BU_:  Airbag BAP_Tester ICAS1_Gateway ICAS1_KommunikationsServer LE1 LE2 Motor_BEV Schaltbetaetigung

BU_:  Airbag BAP_Tester ICAS1_Gateway ICAS1_KommunikationsServer LE1 LE2 Motor_BEV Schaltbetaetigung

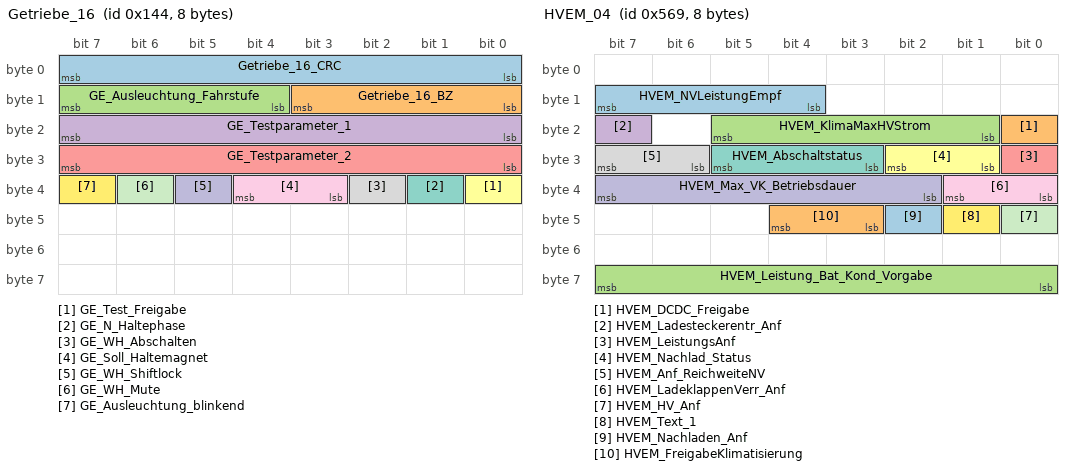
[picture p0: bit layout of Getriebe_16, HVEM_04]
BO_ 324 Getriebe_16: 8 Motor_BEV
 SG_ Getriebe_16_CRC  : 0|8@1+ (1.000000,0.000000) [0.000000|255.000000] "" ICAS1_Gateway Schaltbetaetigung
 SG_ Getriebe_16_BZ  : 8|4@1+ (1.000000,0.000000) [0.000000|15.000000] "" ICAS1_Gateway Schaltbetaetigung
 SG_ GE_Ausleuchtung_Fahrstufe  : 12|4@1+ (1.000000,0.000000) [0.000000|15.000000] "" ICAS1_Gateway Schaltbetaetigung
 SG_ GE_Testparameter_1  : 16|8@1+ (1.000000,0.000000) [0.000000|255.000000] "" ICAS1_Gateway Schaltbetaetigung
 SG_ GE_Testparameter_2  : 24|8@1+ (1.000000,0.000000) [0.000000|255.000000] "" ICAS1_Gateway Schaltbetaetigung
 SG_ GE_Test_Freigabe  : 32|1@1+ (1.000000,0.000000) [0.000000|1.000000] "" ICAS1_Gateway Schaltbetaetigung
 SG_ GE_N_Haltephase  : 33|1@1+ (1.000000,0.000000) [0.000000|1.000000] "" ICAS1_Gateway Schaltbetaetigung
 SG_ GE_WH_Abschalten  : 34|1@1+ (1.000000,0.000000) [0.000000|1.000000] "" ICAS1_Gateway Schaltbetaetigung
 SG_ GE_Soll_Haltemagnet  : 35|2@1+ (1.000000,0.000000) [0.000000|3.000000] "" ICAS1_Gateway Schaltbetaetigung
 SG_ GE_WH_Shiftlock  : 37|1@1+ (1.000000,0.000000) [0.000000|1.000000] "" ICAS1_Gateway Schaltbetaetigung
 SG_ GE_WH_Mute  : 38|1@1+ (1.000000,0.000000) [0.000000|1.000000] "" ICAS1_Gateway Schaltbetaetigung
 SG_ GE_Ausleuchtung_blinkend  : 39|1@1+ (1.000000,0.000000) [0.000000|1.000000] "" ICAS1_Gateway Schaltbetaetigung

BO_ 299 GRA_ACC_01: 8 ICAS1_Gateway
 SG_ GRA_ACC_01_CRC  : 0|8@1+ (1.000000,0.000000) [0.000000|255.000000] "" Motor_BEV
 SG_ GRA_ACC_01_BZ  : 8|4@1+ (1.000000,0.000000) [0.000000|15.000000] "" Motor_BEV
 SG_ GRA_Hauptschalter  : 12|1@1+ (1.000000,0.000000) [0.000000|1.000000] "" Motor_BEV
 SG_ GRA_Abbrechen  : 13|1@1+ (1.000000,0.000000) [0.000000|1.000000] "" Motor_BEV
 SG_ GRA_Typ_Hauptschalter  : 14|1@1+ (1.000000,0.000000) [0.000000|1.000000] "" Motor_BEV
 SG_ GRA_Limiter  : 15|1@1+ (1.000000,0.000000) [0.000000|1.000000] "" Motor_BEV
 SG_ GRA_Tip_Setzen  : 16|1@1+ (1.000000,0.000000) [0.000000|1.000000] "" Motor_BEV
 SG_ GRA_Tip_Hoch  : 17|1@1+ (1.000000,0.000000) [0.000000|1.000000] "" Motor_BEV
 SG_ GRA_Tip_Runter  : 18|1@1+ (1.000000,0.000000) [0.000000|1.000000] "" Motor_BEV
 SG_ GRA_Tip_Wiederaufnahme  : 19|1@1+ (1.000000,0.000000) [0.000000|1.000000] "" Motor_BEV
 SG_ GRA_Verstellung_Zeitluecke  : 20|2@1+ (1.000000,0.000000) [0.000000|3.000000] "" Vector__XXX
 SG_ GRA_Codierung  : 22|2@1+ (1.000000,0.000000) [0.000000|3.000000] "" Motor_BEV
 SG_ GRA_Fehler  : 24|1@1+ (1.000000,0.000000) [0.000000|1.000000] "" Motor_BEV
 SG_ GRA_LIM_Taste_verfuegbar  : 25|1@1+ (1.000000,0.000000) [0.000000|1.000000] "" Motor_BEV
 SG_ GRA_Tip_Stufe_2  : 26|1@1+ (1.000000,0.000000) [0.000000|1.000000] "" Motor_BEV
 SG_ GRA_Typ_Bedienteil  : 27|3@1+ (1.000000,0.000000) [0.000000|7.000000] "" Motor_BEV
 SG_ GRA_TravelAssist  : 30|1@1+ (1.000000,0.000000) [0.000000|1.000000] "" Vector__XXX
 SG_ GRA_reserveByte4  : 31|1@1+ (1.000000,0.000000) [0.000000|1.000000] "" Vector__XXX
 SG_ GRA_reserveByte5  : 32|8@1+ (1.000000,0.000000) [0.000000|255.000000] "" Vector__XXX
 SG_ GRA_reserveByte6  : 40|8@1+ (1.000000,0.000000) [0.000000|255.000000] "" Vector__XXX
 SG_ GRA_reserveByte7  : 48|8@1+ (1.000000,0.000000) [0.000000|255.000000] "" Vector__XXX
 SG_ GRA_reserveByte8  : 56|8@1+ (1.000000,0.000000) [0.000000|255.000000] "" Vector__XXX

BO_ 1452 HVEM_02: 8 ICAS1_Gateway
 SG_ HVEM_IstStrom_HVVerbraucher  : 0|12@1+ (0.100000,-204.700000) [-204.700000|204.600000] "Unit_Amper" Vector__XXX
 SG_ HVEM_Energie_Klima_Vorgabe_HighR  : 12|3@1+ (10.000000,0.000000) [0.000000|50.000000] "Unit_WattHour" Vector__XXX
 SG_ HVEM_IstLeistungNA  : 15|9@1+ (50.000000,0.000000) [0.000000|25450.000000] "Unit_Watt" Motor_BEV
 SG_ HVEM_Leistung_Klima_Vorgabe  : 24|8@1+ (50.000000,0.000000) [0.000000|12650.000000] "Unit_Watt" Vector__XXX
 SG_ HVEM_Nutzbare_Energie  : 32|11@1+ (50.000000,0.000000) [0.000000|102200.000000] "Unit_WattHour" Vector__XXX
 SG_ HVEM_Energie_Klima_Vorgabe  : 43|8@1+ (50.000000,0.000000) [0.000000|12650.000000] "Unit_WattHour" Vector__XXX
 SG_ HVEM_HVK_Aktivitaet  : 51|2@1+ (1.000000,0.000000) [0.000000|3.000000] "" Motor_BEV
 SG_ HVEM_Pruefpuls_Anf  : 53|2@1+ (1.000000,0.000000) [0.000000|3.000000] "" Motor_BEV
 SG_ HVEM_HV_Anf  : 62|1@1+ (1.000000,0.000000) [0.000000|1.000000] "" Motor_BEV
 SG_ HVEM_MO_MaxLeistungIgnoriert  : 63|1@1+ (1.000000,0.000000) [0.000000|1.000000] "" Vector__XXX

BO_ 1385 HVEM_04: 8 ICAS1_Gateway
 SG_ HVEM_NVLeistungEmpf  : 12|4@1+ (100.000000,0.000000) [0.000000|1500.000000] "Unit_Watt" Vector__XXX
 SG_ HVEM_DCDC_Freigabe  : 16|1@1+ (1.000000,0.000000) [0.000000|1.000000] "" Motor_BEV
 SG_ HVEM_KlimaMaxHVStrom  : 17|5@1+ (1.000000,0.000000) [0.000000|31.000000] "Unit_Amper" Vector__XXX
 SG_ HVEM_Ladesteckerentr_Anf  : 23|1@1+ (1.000000,0.000000) [0.000000|1.000000] "" Vector__XXX
 SG_ HVEM_LeistungsAnf  : 24|1@1+ (1.000000,0.000000) [0.000000|1.000000] "" Vector__XXX
 SG_ HVEM_Nachlad_Status  : 25|2@1+ (1.000000,0.000000) [0.000000|3.000000] "" Vector__XXX
 SG_ HVEM_Abschaltstatus  : 27|3@1+ (1.000000,0.000000) [0.000000|7.000000] "" Vector__XXX
 SG_ HVEM_Anf_ReichweiteNV  : 30|2@1+ (1.000000,0.000000) [0.000000|3.000000] "" Vector__XXX
 SG_ HVEM_LadeklappenVerr_Anf  : 32|2@1+ (1.000000,0.000000) [0.000000|3.000000] "" Vector__XXX
 SG_ HVEM_Max_VK_Betriebsdauer  : 34|6@1+ (1.000000,0.000000) [0.000000|60.000000] "Unit_Minut" Vector__XXX
 SG_ HVEM_HV_Anf  : 40|1@1+ (1.000000,0.000000) [0.000000|1.000000] "" Vector__XXX
 SG_ HVEM_Text_1  : 41|1@1+ (1.000000,0.000000) [0.000000|1.000000] "" Vector__XXX
 SG_ HVEM_Nachladen_Anf  : 42|1@1+ (1.000000,0.000000) [0.000000|1.000000] "" Vector__XXX
 SG_ HVEM_FreigabeKlimatisierung  : 43|2@1+ (1.000000,0.000000) [0.000000|3.000000] "" Vector__XXX
 SG_ HVEM_Leistung_Bat_Kond_Vorgabe  : 56|8@1+ (50.000000,0.000000) [0.000000|12650.000000] "Unit_Watt" Vector__XXX

BO_ 1283 HVK_01: 8 Motor_BEV
 SG_ HVK_01_CRC  : 0|8@1+ (1.000000,0.000000) [0.000000|255.000000] "" ICAS1_Gateway LE1 LE2
 SG_ HVK_01_BZ  : 8|4@1+ (1.000000,0.000000) [0.000000|15.000000] "" ICAS1_Gateway LE1 LE2
 SG_ HVK_Istmodus_Anf  : 12|1@1+ (1.000000,0.000000) [0.000000|1.000000] "" ICAS1_Gateway
 SG_ HVK_TN1_Sollmodus  : 13|2@1+ (1.000000,0.000000) [0.000000|3.000000] "" ICAS1_Gateway
 SG_ HVK_Vorladung_aktiv  : 15|1@1+ (1.000000,0.000000) [0.000000|1.000000] "" ICAS1_Gateway
 SG_ HVK_BMS_Sollmodus  : 24|3@1+ (1.000000,0.000000) [0.000000|7.000000] "" ICAS1_Gateway
 SG_ HVK_DCDC_Sollmodus  : 27|3@1+ (1.000000,0.000000) [0.000000|7.000000] "" ICAS1_Gateway
 SG_ HVK_EKK_Sollmodus  : 30|3@1+ (1.000000,0.000000) [0.000000|7.000000] "" ICAS1_Gateway
 SG_ HVK_HVPTC_Sollmodus  : 33|3@1+ (1.000000,0.000000) [0.000000|7.000000] "" ICAS1_Gateway
 SG_ HVK_HVLM_Sollmodus  : 36|3@1+ (1.000000,0.000000) [0.000000|7.000000] "" ICAS1_Gateway
 SG_ HVK_HV_Netz_Warnungen  : 39|2@1+ (1.000000,0.000000) [0.000000|3.000000] "" ICAS1_Gateway ICAS1_KommunikationsServer
 SG_ HV_Bordnetz_aktiv  : 41|1@1+ (1.000000,0.000000) [0.000000|1.000000] "" ICAS1_Gateway LE1 LE2
 SG_ HV_Bordnetz_Fehler  : 42|1@1+ (1.000000,0.000000) [0.000000|1.000000] "" ICAS1_Gateway
 SG_ HVK_Gesamtst_Spgfreiheit  : 43|2@1+ (1.000000,0.000000) [0.000000|3.000000] "" ICAS1_Gateway ICAS1_KommunikationsServer
 SG_ HVK_AktiveEntladung_Anf  : 45|1@1+ (1.000000,0.000000) [0.000000|1.000000] "" ICAS1_Gateway LE1 LE2
 SG_ HVK_HVEM_Freigabe  : 46|2@1+ (1.000000,0.000000) [0.000000|3.000000] "" ICAS1_Gateway
 SG_ HVK_Notentladung_Anf  : 48|2@1+ (1.000000,0.000000) [0.000000|3.000000] "" ICAS1_Gateway LE1 LE2
 SG_ HVK_Iso_Messung_Start  : 50|3@1+ (1.000000,0.000000) [0.000000|7.000000] "" ICAS1_Gateway
 SG_ HVK_Ladebereit  : 53|3@1+ (1.000000,0.000000) [0.000000|7.000000] "" ICAS1_Gateway
 SG_ HVK_PPulsFreigabe  : 56|2@1+ (1.000000,0.000000) [0.000000|3.000000] "" ICAS1_Gateway

BO_ 2463978813 HVL_01: 8 ICAS1_Gateway
 SG_ HVL_01_CRC  : 0|8@1+ (1.000000,0.000000) [0.000000|255.000000] "" Motor_BEV
 SG_ HVL_01_BZ  : 8|4@1+ (1.000000,0.000000) [0.000000|15.000000] "" Motor_BEV
 SG_ HVL_Steckerstatus  : 12|2@1+ (1.000000,0.000000) [0.000000|3.000000] "" Motor_BEV
 SG_ HVL_LadeAnforderung  : 24|3@1+ (1.000000,0.000000) [0.000000|7.000000] "" Motor_BEV

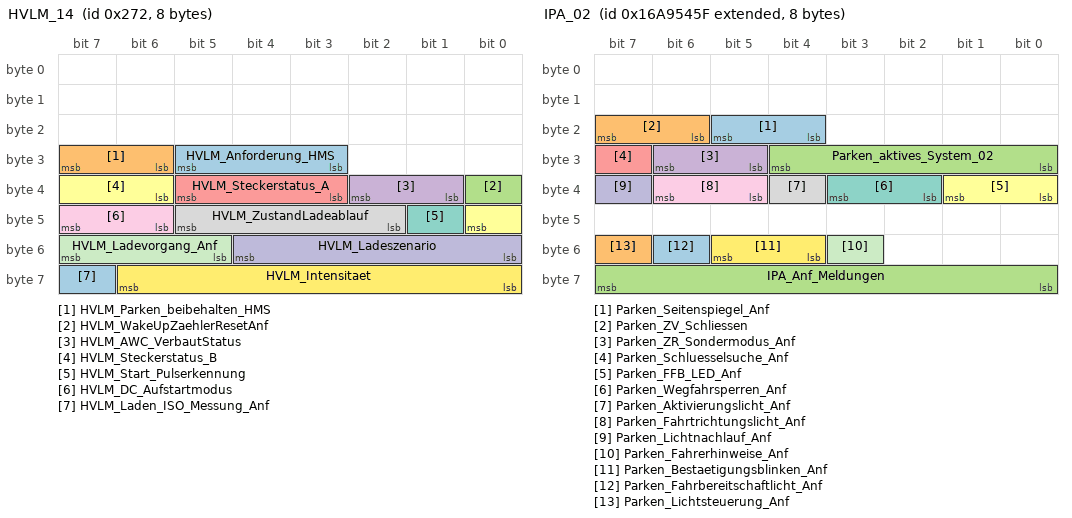
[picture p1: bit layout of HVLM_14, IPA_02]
BO_ 626 HVLM_14: 8 ICAS1_Gateway
 SG_ HVLM_Anforderung_HMS  : 27|3@1+ (1.000000,0.000000) [0.000000|7.000000] "" Vector__XXX
 SG_ HVLM_Parken_beibehalten_HMS  : 30|2@1+ (1.000000,0.000000) [0.000000|3.000000] "" Vector__XXX
 SG_ HVLM_WakeUpZaehlerResetAnf  : 32|1@1+ (1.000000,0.000000) [0.000000|1.000000] "" Vector__XXX
 SG_ HVLM_AWC_VerbautStatus  : 33|2@1+ (1.000000,0.000000) [0.000000|3.000000] "" Motor_BEV
 SG_ HVLM_Steckerstatus_A  : 35|3@1+ (1.000000,0.000000) [0.000000|7.000000] "" Motor_BEV
 SG_ HVLM_Steckerstatus_B  : 38|3@1+ (1.000000,0.000000) [0.000000|7.000000] "" Vector__XXX
 SG_ HVLM_Start_Pulserkennung  : 41|1@1+ (1.000000,0.000000) [0.000000|1.000000] "" Vector__XXX
 SG_ HVLM_ZustandLadeablauf  : 42|4@1+ (1.000000,0.000000) [0.000000|15.000000] "" Motor_BEV
 SG_ HVLM_DC_Aufstartmodus  : 46|2@1+ (1.000000,0.000000) [0.000000|3.000000] "" Motor_BEV
 SG_ HVLM_Ladeszenario  : 48|5@1+ (1.000000,0.000000) [0.000000|31.000000] "" Vector__XXX
 SG_ HVLM_Ladevorgang_Anf  : 53|3@1+ (1.000000,0.000000) [0.000000|7.000000] "" Motor_BEV
 SG_ HVLM_Intensitaet  : 56|7@1+ (1.000000,0.000000) [0.000000|100.000000] "Unit_PerCent" Vector__XXX
 SG_ HVLM_Laden_ISO_Messung_Anf  : 63|1@1+ (1.000000,0.000000) [0.000000|1.000000] "" Motor_BEV

BO_ 268 IMMO_CORD_01: 8 Motor_BEV
 SG_ ImoCord_Auth_Aufforderung_WFS  : 63|1@1+ (1.000000,0.000000) [0.000000|1.000000] "" LE1 LE2

BO_ 23 IMMO_MSG3_Antwort: 8 ICAS1_Gateway
 SG_ WFS_IMMO_MSG3_CRC  : 0|32@1+ (1.000000,0.000000) [0.000000|4294967295.000000] "" LE2
 SG_ WFS_IMMO_MSG3_Status  : 56|8@1+ (1.000000,0.000000) [0.000000|255.000000] "" LE2

BO_ 25 IMMO_MSG4_Antwort: 8 ICAS1_Gateway
 SG_ WFS_IMMO_MSG4_CRC  : 0|32@1+ (1.000000,0.000000) [0.000000|4294967295.000000] "" LE1
 SG_ WFS_IMMO_MSG4_Status  : 56|8@1+ (1.000000,0.000000) [0.000000|255.000000] "" LE1

BO_ 2527679583 IPA_02: 8 ICAS1_Gateway
 SG_ Parken_Seitenspiegel_Anf  : 20|2@1+ (1.000000,0.000000) [0.000000|3.000000] "" Vector__XXX
 SG_ Parken_ZV_Schliessen  : 22|2@1+ (1.000000,0.000000) [0.000000|3.000000] "" Vector__XXX
 SG_ Parken_aktives_System_02  : 24|5@1+ (1.000000,0.000000) [0.000000|31.000000] "" Vector__XXX
 SG_ Parken_ZR_Sondermodus_Anf  : 29|2@1+ (1.000000,0.000000) [0.000000|3.000000] "" Vector__XXX
 SG_ Parken_Schluesselsuche_Anf  : 31|1@1+ (1.000000,0.000000) [0.000000|1.000000] "" Vector__XXX
 SG_ Parken_FFB_LED_Anf  : 32|2@1+ (1.000000,0.000000) [0.000000|3.000000] "" Vector__XXX
 SG_ Parken_Wegfahrsperren_Anf  : 34|2@1+ (1.000000,0.000000) [0.000000|3.000000] "" LE1 LE2
 SG_ Parken_Aktivierungslicht_Anf  : 36|1@1+ (1.000000,0.000000) [0.000000|1.000000] "" Vector__XXX
 SG_ Parken_Fahrtrichtungslicht_Anf  : 37|2@1+ (1.000000,0.000000) [0.000000|3.000000] "" Vector__XXX
 SG_ Parken_Lichtnachlauf_Anf  : 39|1@1+ (1.000000,0.000000) [0.000000|1.000000] "" Vector__XXX
 SG_ Parken_Fahrerhinweise_Anf  : 51|1@1+ (1.000000,0.000000) [0.000000|1.000000] "" Vector__XXX
 SG_ Parken_Bestaetigungsblinken_Anf  : 52|2@1+ (1.000000,0.000000) [0.000000|3.000000] "" Vector__XXX
 SG_ Parken_Fahrbereitschaftlicht_Anf  : 54|1@1+ (1.000000,0.000000) [0.000000|1.000000] "" Vector__XXX
 SG_ Parken_Lichtsteuerung_Anf  : 55|1@1+ (1.000000,0.000000) [0.000000|1.000000] "" Vector__XXX
 SG_ IPA_Anf_Meldungen  : 56|8@1+ (1.000000,0.000000) [0.000000|255.000000] "" Vector__XXX

BO_ 1813 ISO_Airbag_01_Req: 8 ICAS1_Gateway
 SG_ ISO_Airbag_01_Req_Data  : 0|64@1+ (1.000000,0.000000) [0.000000|18446744073709551616.000000] "" Airbag

BO_ 1919 ISO_Airbag_01_Resp: 8 Airbag
 SG_ ISO_Airbag_01_Resp_Data  : 0|64@1+ (1.000000,0.000000) [0.000000|18446744073709551616.000000] "" ICAS1_Gateway

BO_ 1792 ISO_Funktionaler_Req_All: 8 ICAS1_Gateway
 SG_ ISO_ALL_01_Req_Data  : 0|64@1+ (1.000000,0.000000) [0.000000|18446744073709551616.000000] "" Airbag LE1 LE2 Motor_BEV

BO_ 2621440021 ISOx_Airbag_01_Req_FD: 64 ICAS1_Gateway
 SG_ ISOx_Airbag_01_Req_FD_Data  : 0|512@1+ (1.000000,0.000000) [0.000000|13407807929942597099574024998205846127479365820592393377723561443721764030073546976801874298166903427690031858186486050853753882811946569946433649006084096.000000] "" Airbag

BO_ 2621571093 ISOx_Airbag_01_Resp_FD: 64 Airbag
 SG_ ISOx_Airbag_01_Resp_FD_Data  : 0|512@1+ (1.000000,0.000000) [0.000000|13407807929942597099574024998205846127479365820592393377723561443721764030073546976801874298166903427690031858186486050853753882811946569946433649006084096.000000] "" ICAS1_Gateway

BO_ 2549874812 ISOx_EMotor_01_Req: 8 ICAS1_Gateway
 SG_ ISO_EMotor_01_Req_Data  : 0|64@1+ (1.000000,0.000000) [0.000000|18446744073709551616.000000] "" LE1

BO_ 2621440124 ISOx_EMotor_01_Req_FD: 64 ICAS1_Gateway
 SG_ ISOx_EMotor_01_Req_FD_Data  : 0|512@1+ (1.000000,0.000000) [0.000000|13407807929942597099574024998205846127479365820592393377723561443721764030073546976801874298166903427690031858186486050853753882811946569946433649006084096.000000] "" LE1

BO_ 2550005884 ISOx_EMotor_01_Resp: 8 LE1
 SG_ ISO_EMotor_01_Resp_Data  : 0|64@1+ (1.000000,0.000000) [0.000000|18446744073709551616.000000] "" ICAS1_Gateway

BO_ 2621571196 ISOx_EMotor_01_Resp_FD: 64 LE1
 SG_ ISOx_EMotor_01_Resp_FD_Data  : 0|512@1+ (1.000000,0.000000) [0.000000|13407807929942597099574024998205846127479365820592393377723561443721764030073546976801874298166903427690031858186486050853753882811946569946433649006084096.000000] "" ICAS1_Gateway

BO_ 2549874872 ISOx_EMotor_02_Req: 8 ICAS1_Gateway
 SG_ ISO_EMotor_02_Req_Data  : 0|64@1+ (1.000000,0.000000) [0.000000|18446744073709551616.000000] "" LE2

BO_ 2621440184 ISOx_EMotor_02_Req_FD: 64 ICAS1_Gateway
 SG_ ISOx_EMotor_02_Req_FD_Data  : 0|512@1+ (1.000000,0.000000) [0.000000|13407807929942597099574024998205846127479365820592393377723561443721764030073546976801874298166903427690031858186486050853753882811946569946433649006084096.000000] "" LE2

BO_ 2550005944 ISOx_EMotor_02_Resp: 8 LE2
 SG_ ISO_EMotor_02_Resp_Data  : 0|64@1+ (1.000000,0.000000) [0.000000|18446744073709551616.000000] "" ICAS1_Gateway

BO_ 2621571256 ISOx_EMotor_02_Resp_FD: 64 LE2
 SG_ ISOx_EMotor_02_Resp_FD_Data  : 0|512@1+ (1.000000,0.000000) [0.000000|13407807929942597099574024998205846127479365820592393377723561443721764030073546976801874298166903427690031858186486050853753882811946569946433649006084096.000000] "" ICAS1_Gateway

BO_ 2621505536 ISOx_Funkt_Req_All_FD: 64 ICAS1_Gateway
 SG_ ISOx_Funkt_Req_All_FD_Data  : 0|512@1+ (1.000000,0.000000) [0.000000|13407807929942597099574024998205846127479365820592393377723561443721764030073546976801874298166903427690031858186486050853753882811946569946433649006084096.000000] "" Airbag LE1 LE2 Motor_BEV

BO_ 2549874806 ISOx_MO_01_Req: 8 ICAS1_Gateway
 SG_ ISOx_MO_01_Req_Data  : 0|64@1+ (1.000000,0.000000) [0.000000|18446744073709551616.000000] "" Motor_BEV

BO_ 2621440118 ISOx_MO_01_Req_FD: 64 ICAS1_Gateway
 SG_ ISOx_MO_01_Req_FD_Data  : 0|512@1+ (1.000000,0.000000) [0.000000|13407807929942597099574024998205846127479365820592393377723561443721764030073546976801874298166903427690031858186486050853753882811946569946433649006084096.000000] "" Motor_BEV

BO_ 2550005878 ISOx_MO_01_Resp: 8 Motor_BEV
 SG_ ISOx_MO_01_Resp_Data  : 0|64@1+ (1.000000,0.000000) [0.000000|18446744073709551616.000000] "" ICAS1_Gateway

BO_ 2621571190 ISOx_MO_01_Resp_FD: 64 Motor_BEV
 SG_ ISOx_MO_01_Resp_FD_Data  : 0|512@1+ (1.000000,0.000000) [0.000000|13407807929942597099574024998205846127479365820592393377723561443721764030073546976801874298166903427690031858186486050853753882811946569946433649006084096.000000] "" ICAS1_Gateway

BO_ 2527679684 Kamera_ASM_01: 8 ICAS1_Gateway
 SG_ Kamera_ASM_Ereignis  : 0|8@1+ (1.000000,0.000000) [1.000000|254.000000] "" Airbag
 SG_ Kamera_ASM_Zeitstempel  : 8|8@1+ (0.080000,0.000000) [0.000000|20.320000] "Unit_Secon" Airbag
 SG_ Kamera_ASM_Data_1  : 16|8@1+ (1.000000,0.000000) [0.000000|255.000000] "" Airbag
 SG_ Kamera_ASM_Data_2  : 24|8@1+ (1.000000,0.000000) [0.000000|255.000000] "" Airbag
 SG_ Kamera_ASM_Data_3  : 32|8@1+ (1.000000,0.000000) [0.000000|255.000000] "" Airbag
 SG_ Kamera_ASM_Data_4  : 40|8@1+ (1.000000,0.000000) [0.000000|255.000000] "" Airbag
 SG_ Kamera_ASM_Data_5  : 48|8@1+ (1.000000,0.000000) [0.000000|255.000000] "" Airbag
 SG_ Kamera_ASM_Data_6  : 56|8@1+ (1.000000,0.000000) [0.000000|255.000000] "" Airbag

BO_ 960 Klemmen_Status_01: 4 ICAS1_Gateway
 SG_ Klemmen_Status_01_CRC  : 0|8@1+ (1.000000,0.000000) [0.000000|255.000000] "" Motor_BEV
 SG_ Klemmen_Status_01_BZ  : 8|4@1+ (1.000000,0.000000) [0.000000|15.000000] "" Motor_BEV
 SG_ RSt_Fahrerhinweise  : 12|4@1+ (1.000000,0.000000) [0.000000|15.000000] "" Vector__XXX
 SG_ ZAS_Kl_S  : 16|1@1+ (1.000000,0.000000) [0.000000|1.000000] "" Vector__XXX
 SG_ ZAS_Kl_15  : 17|1@1+ (1.000000,0.000000) [0.000000|1.000000] "" Airbag LE1 LE2 Motor_BEV Schaltbetaetigung
 SG_ ZAS_Kl_X  : 18|1@1+ (1.000000,0.000000) [0.000000|1.000000] "" Vector__XXX
 SG_ ZAS_Kl_50_Startanforderung  : 19|1@1+ (1.000000,0.000000) [0.000000|1.000000] "" Motor_BEV
 SG_ BCM_Remotestart_Betrieb  : 20|1@1+ (1.000000,0.000000) [0.000000|1.000000] "" Vector__XXX
 SG_ ZAS_Kl_Infotainment  : 21|1@1+ (1.000000,0.000000) [0.000000|1.000000] "" Vector__XXX
 SG_ BCM_Remotestart_KL15_Anf  : 22|1@1+ (1.000000,0.000000) [0.000000|1.000000] "" Vector__XXX
 SG_ BCM_Remotestart_MO_Start  : 23|1@1+ (1.000000,0.000000) [0.000000|1.000000] "" Vector__XXX
 SG_ KST_Warn_P1_ZST_def  : 24|1@1+ (1.000000,0.000000) [0.000000|1.000000] "" Vector__XXX
 SG_ KST_Warn_P2_ZST_def  : 25|1@1+ (1.000000,0.000000) [0.000000|1.000000] "" Vector__XXX
 SG_ KST_Fahrerhinweis_1  : 26|1@1+ (1.000000,0.000000) [0.000000|1.000000] "" Vector__XXX
 SG_ KST_Fahrerhinweis_2  : 27|1@1+ (1.000000,0.000000) [0.000000|1.000000] "" Vector__XXX
 SG_ BCM_Ausparken_Betrieb  : 28|1@1+ (1.000000,0.000000) [0.000000|1.000000] "" Vector__XXX
 SG_ KST_Fahrerhinweis_4  : 29|1@1+ (1.000000,0.000000) [0.000000|1.000000] "" Vector__XXX
 SG_ KST_Fahrerhinweis_5  : 30|1@1+ (1.000000,0.000000) [0.000000|1.000000] "" Vector__XXX
 SG_ KST_Fahrerhinweis_6  : 31|1@1+ (1.000000,0.000000) [0.000000|1.000000] "" Vector__XXX

BO_ 2463978753 Klemmen_Status_02: 8 ICAS1_Gateway
 SG_ KST_WFS_Fahrfreigabe_Anforderung  : 12|2@1+ (1.000000,0.000000) [0.000000|3.000000] "" LE1 LE2
 SG_ KST_Sonderzustand_Status  : 14|2@1+ (1.000000,0.000000) [0.000000|3.000000] "" LE1 LE2
 SG_ KST_Sonderzustand_Anforderung  : 16|5@1+ (1.000000,0.000000) [0.000000|31.000000] "" LE1 LE2

BO_ 1420 Klemmen_Steuerung_01: 8 ICAS1_Gateway
 SG_ Klemmen_Steuerung_01_CRC  : 0|8@1+ (1.000000,0.000000) [0.000000|255.000000] "" Vector__XXX
 SG_ Klemmen_Steuerung_01_BZ  : 8|4@1+ (1.000000,0.000000) [0.000000|15.000000] "" Vector__XXX
 SG_ KST_Anf_Klemme_15  : 12|1@1+ (1.000000,0.000000) [0.000000|1.000000] "" Vector__XXX
 SG_ KST_Anf_Klemme_50  : 13|1@1+ (1.000000,0.000000) [0.000000|1.000000] "" Motor_BEV
 SG_ KST_Anf_Klemme_S  : 14|1@1+ (1.000000,0.000000) [0.000000|1.000000] "" Vector__XXX
 SG_ KST_Txt_Werkstatt  : 15|1@1+ (1.000000,0.000000) [0.000000|1.000000] "" Vector__XXX
 SG_ KST_Txt_P_Gang  : 16|1@1+ (1.000000,0.000000) [0.000000|1.000000] "" Vector__XXX
 SG_ KST_Txt_Panikabschaltung  : 17|1@1+ (1.000000,0.000000) [0.000000|1.000000] "" Vector__XXX
 SG_ KST_Anf_Klemmenfreigabe_ELV  : 18|1@1+ (1.000000,0.000000) [0.000000|1.000000] "" Vector__XXX
 SG_ KST_Txt_Komfortabschaltung  : 19|1@1+ (1.000000,0.000000) [0.000000|1.000000] "" Vector__XXX
 SG_ KST_ZAT_betaetigt  : 20|1@1+ (1.000000,0.000000) [0.000000|1.000000] "" Vector__XXX
 SG_ KST_Unterdr_Zuendungsmeldung  : 21|1@1+ (1.000000,0.000000) [0.000000|1.000000] "" Vector__XXX
 SG_ KST_aut_Abschaltung_Zuendung  : 22|1@1+ (1.000000,0.000000) [0.000000|1.000000] "" Vector__XXX
 SG_ KST_Anf_Klemmenfreigabe_WFS  : 23|1@1+ (1.000000,0.000000) [0.000000|1.000000] "" Vector__XXX
 SG_ KST_Anf_ZV_Verriegelung  : 24|1@1+ (1.000000,0.000000) [0.000000|1.000000] "" Vector__XXX
 SG_ Relais_VoKo_angesteuert  : 25|1@1+ (1.000000,0.000000) [0.000000|1.000000] "" Vector__XXX
 SG_ RSt_Anforderung_HMS  : 26|3@1+ (1.000000,0.000000) [0.000000|7.000000] "" Vector__XXX
 SG_ KST_Zuendungswarnung  : 29|2@1+ (1.000000,0.000000) [0.000000|3.000000] "" Vector__XXX
 SG_ KST_Fahrer_Info_Text  : 31|3@1+ (1.000000,0.000000) [0.000000|7.000000] "" Vector__XXX

BO_ 949 Klima_11: 8 ICAS1_Gateway
 SG_ KL_Drehz_Anh  : 0|1@1+ (1.000000,0.000000) [0.000000|1.000000] "" Vector__XXX
 SG_ KL_Vorwarn_Komp_ein  : 1|1@1+ (1.000000,0.000000) [0.000000|1.000000] "" Vector__XXX
 SG_ KL_AC_Schalter  : 2|1@1+ (1.000000,0.000000) [0.000000|1.000000] "" Vector__XXX
 SG_ KL_Komp_Moment_alt  : 3|1@1+ (1.000000,0.000000) [0.000000|1.000000] "" Vector__XXX
 SG_ KL_Vorwarn_Zuheizer_ein  : 6|1@1+ (1.000000,0.000000) [0.000000|1.000000] "" Vector__XXX
 SG_ KL_Zustand  : 7|1@1+ (1.000000,0.000000) [0.000000|1.000000] "" Vector__XXX
 SG_ KL_Kompressorkupplung_linear  : 8|8@1+ (20.000000,0.000000) [0.000000|4000.000000] "Unit_MilliAmper" Vector__XXX
 SG_ KL_Charisma_FahrPr  : 16|4@1+ (1.000000,0.000000) [0.000000|15.000000] "" Vector__XXX
 SG_ KL_Charisma_Status  : 20|2@1+ (1.000000,0.000000) [0.000000|3.000000] "" Vector__XXX
 SG_ KL_nachtr_Stopp_Anf  : 22|1@1+ (1.000000,0.000000) [0.000000|1.000000] "" Vector__XXX
 SG_ KL_T_Charge  : 23|1@1+ (1.000000,0.000000) [0.000000|1.000000] "" Vector__XXX
 SG_ KL_Last_Kompr  : 24|8@1+ (0.250000,0.000000) [0.000000|63.500000] "Unit_NewtoMeter" Vector__XXX
 SG_ KL_Spannungs_Anf  : 32|2@1+ (1.000000,0.000000) [0.000000|3.000000] "" Vector__XXX
 SG_ KL_Thermomanagement  : 34|2@1+ (1.000000,0.000000) [0.000000|3.000000] "" Motor_BEV
 SG_ KL_StartStopp_Info  : 36|2@1+ (1.000000,0.000000) [0.000000|3.000000] "" Vector__XXX
 SG_ KL_Freilauf_Info  : 38|2@1+ (1.000000,0.000000) [0.000000|3.000000] "" Vector__XXX
 SG_ KL_Anf_KL  : 40|8@1+ (0.400000,0.000000) [0.000000|101.600000] "Unit_PerCent" Motor_BEV
 SG_ KL_el_Zuheizer_Stufe  : 48|3@1+ (1.000000,0.000000) [0.000000|7.000000] "" Vector__XXX
 SG_ KL_Ausstattung_Klima  : 51|3@1+ (1.000000,0.000000) [0.000000|7.000000] "" Vector__XXX
 SG_ KL_Variante_Standheizung  : 54|2@1+ (1.000000,0.000000) [0.000000|3.000000] "" Vector__XXX
 SG_ KL_Anf_KV  : 57|7@1+ (1.000000,0.000000) [0.000000|100.000000] "Unit_PerCent" Motor_BEV

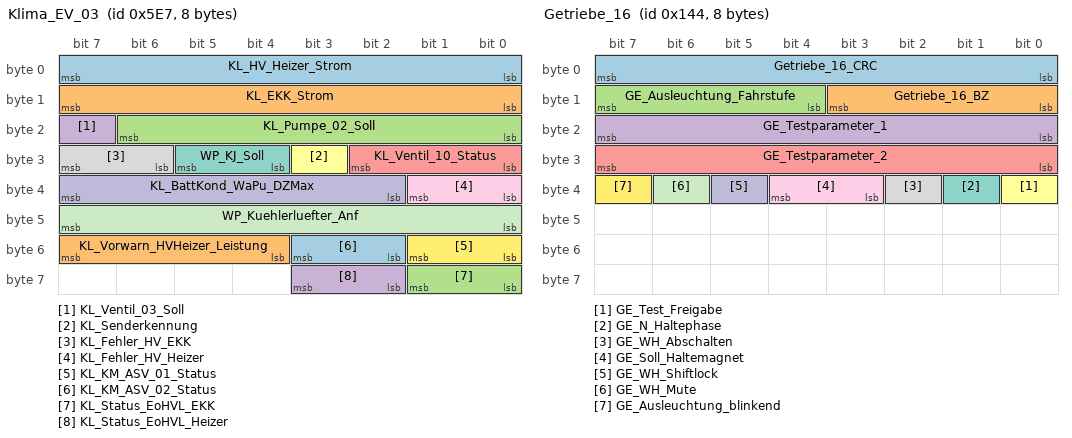
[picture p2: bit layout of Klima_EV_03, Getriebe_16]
BO_ 1511 Klima_EV_03: 8 ICAS1_Gateway
 SG_ KL_HV_Heizer_Strom  : 0|8@1+ (0.250000,0.000000) [0.000000|63.500000] "Unit_Amper" Motor_BEV
 SG_ KL_EKK_Strom  : 8|8@1+ (0.250000,0.000000) [0.000000|63.500000] "Unit_Amper" Motor_BEV
 SG_ KL_Pumpe_02_Soll  : 16|7@1+ (1.000000,0.000000) [0.000000|100.000000] "Unit_PerCent" Motor_BEV
 SG_ KL_Ventil_03_Soll  : 23|1@1+ (1.000000,0.000000) [0.000000|1.000000] "" Vector__XXX
 SG_ KL_Ventil_10_Status  : 24|3@1+ (1.000000,0.000000) [0.000000|7.000000] "" Vector__XXX
 SG_ KL_Senderkennung  : 27|1@1+ (1.000000,0.000000) [0.000000|1.000000] "" Vector__XXX
 SG_ WP_KJ_Soll  : 28|2@1+ (1.000000,0.000000) [0.000000|3.000000] "" Vector__XXX
 SG_ KL_Fehler_HV_EKK  : 30|2@1+ (1.000000,0.000000) [0.000000|3.000000] "" Vector__XXX
 SG_ KL_Fehler_HV_Heizer  : 32|2@1+ (1.000000,0.000000) [0.000000|3.000000] "" Vector__XXX
 SG_ KL_BattKond_WaPu_DZMax  : 34|6@1+ (2.000000,0.000000) [0.000000|100.000000] "Unit_PerCent" Vector__XXX
 SG_ WP_Kuehlerluefter_Anf  : 40|8@1+ (0.400000,0.000000) [0.000000|101.600000] "Unit_PerCent" Vector__XXX
 SG_ KL_KM_ASV_01_Status  : 48|2@1+ (1.000000,0.000000) [0.000000|3.000000] "" Vector__XXX
 SG_ KL_KM_ASV_02_Status  : 50|2@1+ (1.000000,0.000000) [0.000000|3.000000] "" Vector__XXX
 SG_ KL_Vorwarn_HVHeizer_Leistung  : 52|4@1+ (1.000000,0.000000) [0.000000|15.000000] "" Vector__XXX
 SG_ KL_Status_EoHVL_EKK  : 56|2@1+ (1.000000,0.000000) [0.000000|3.000000] "" Motor_BEV
 SG_ KL_Status_EoHVL_Heizer  : 58|2@1+ (1.000000,0.000000) [0.000000|3.000000] "" Motor_BEV

BU_:  Airbag BAP_Tester ICAS1_Gateway ICAS1_KommunikationsServer LE1 LE2 Motor_BEV Schaltbetaetigung

BO_ 324 Getriebe_16: 8 Motor_BEV
 SG_ Getriebe_16_CRC  : 0|8@1+ (1.000000,0.000000) [0.000000|255.000000] "" ICAS1_Gateway Schaltbetaetigung
 SG_ Getriebe_16_BZ  : 8|4@1+ (1.000000,0.000000) [0.000000|15.000000] "" ICAS1_Gateway Schaltbetaetigung
 SG_ GE_Ausleuchtung_Fahrstufe  : 12|4@1+ (1.000000,0.000000) [0.000000|15.000000] "" ICAS1_Gateway Schaltbetaetigung
 SG_ GE_Testparameter_1  : 16|8@1+ (1.000000,0.000000) [0.000000|255.000000] "" ICAS1_Gateway Schaltbetaetigung
 SG_ GE_Testparameter_2  : 24|8@1+ (1.000000,0.000000) [0.000000|255.000000] "" ICAS1_Gateway Schaltbetaetigung
 SG_ GE_Test_Freigabe  : 32|1@1+ (1.000000,0.000000) [0.000000|1.000000] "" ICAS1_Gateway Schaltbetaetigung
 SG_ GE_N_Haltephase  : 33|1@1+ (1.000000,0.000000) [0.000000|1.000000] "" ICAS1_Gateway Schaltbetaetigung
 SG_ GE_WH_Abschalten  : 34|1@1+ (1.000000,0.000000) [0.000000|1.000000] "" ICAS1_Gateway Schaltbetaetigung
 SG_ GE_Soll_Haltemagnet  : 35|2@1+ (1.000000,0.000000) [0.000000|3.000000] "" ICAS1_Gateway Schaltbetaetigung
 SG_ GE_WH_Shiftlock  : 37|1@1+ (1.000000,0.000000) [0.000000|1.000000] "" ICAS1_Gateway Schaltbetaetigung
 SG_ GE_WH_Mute  : 38|1@1+ (1.000000,0.000000) [0.000000|1.000000] "" ICAS1_Gateway Schaltbetaetigung
 SG_ GE_Ausleuchtung_blinkend  : 39|1@1+ (1.000000,0.000000) [0.000000|1.000000] "" ICAS1_Gateway Schaltbetaetigung

BO_ 299 GRA_ACC_01: 8 ICAS1_Gateway
 SG_ GRA_ACC_01_CRC  : 0|8@1+ (1.000000,0.000000) [0.000000|255.000000] "" Motor_BEV
 SG_ GRA_ACC_01_BZ  : 8|4@1+ (1.000000,0.000000) [0.000000|15.000000] "" Motor_BEV
 SG_ GRA_Hauptschalter  : 12|1@1+ (1.000000,0.000000) [0.000000|1.000000] "" Motor_BEV
 SG_ GRA_Abbrechen  : 13|1@1+ (1.000000,0.000000) [0.000000|1.000000] "" Motor_BEV
 SG_ GRA_Typ_Hauptschalter  : 14|1@1+ (1.000000,0.000000) [0.000000|1.000000] "" Motor_BEV
 SG_ GRA_Limiter  : 15|1@1+ (1.000000,0.000000) [0.000000|1.000000] "" Motor_BEV
 SG_ GRA_Tip_Setzen  : 16|1@1+ (1.000000,0.000000) [0.000000|1.000000] "" Motor_BEV
 SG_ GRA_Tip_Hoch  : 17|1@1+ (1.000000,0.000000) [0.000000|1.000000] "" Motor_BEV
 SG_ GRA_Tip_Runter  : 18|1@1+ (1.000000,0.000000) [0.000000|1.000000] "" Motor_BEV
 SG_ GRA_Tip_Wiederaufnahme  : 19|1@1+ (1.000000,0.000000) [0.000000|1.000000] "" Motor_BEV
 SG_ GRA_Verstellung_Zeitluecke  : 20|2@1+ (1.000000,0.000000) [0.000000|3.000000] "" Vector__XXX
 SG_ GRA_Codierung  : 22|2@1+ (1.000000,0.000000) [0.000000|3.000000] "" Motor_BEV
 SG_ GRA_Fehler  : 24|1@1+ (1.000000,0.000000) [0.000000|1.000000] "" Motor_BEV
 SG_ GRA_LIM_Taste_verfuegbar  : 25|1@1+ (1.000000,0.000000) [0.000000|1.000000] "" Motor_BEV
 SG_ GRA_Tip_Stufe_2  : 26|1@1+ (1.000000,0.000000) [0.000000|1.000000] "" Motor_BEV
 SG_ GRA_Typ_Bedienteil  : 27|3@1+ (1.000000,0.000000) [0.000000|7.000000] "" Motor_BEV
 SG_ GRA_TravelAssist  : 30|1@1+ (1.000000,0.000000) [0.000000|1.000000] "" Vector__XXX
 SG_ GRA_reserveByte4  : 31|1@1+ (1.000000,0.000000) [0.000000|1.000000] "" Vector__XXX
 SG_ GRA_reserveByte5  : 32|8@1+ (1.000000,0.000000) [0.000000|255.000000] "" Vector__XXX
 SG_ GRA_reserveByte6  : 40|8@1+ (1.000000,0.000000) [0.000000|255.000000] "" Vector__XXX
 SG_ GRA_reserveByte7  : 48|8@1+ (1.000000,0.000000) [0.000000|255.000000] "" Vector__XXX
 SG_ GRA_reserveByte8  : 56|8@1+ (1.000000,0.000000) [0.000000|255.000000] "" Vector__XXX

BO_ 1452 HVEM_02: 8 ICAS1_Gateway
 SG_ HVEM_IstStrom_HVVerbraucher  : 0|12@1+ (0.100000,-204.700000) [-204.700000|204.600000] "Unit_Amper" Vector__XXX
 SG_ HVEM_Energie_Klima_Vorgabe_HighR  : 12|3@1+ (10.000000,0.000000) [0.000000|50.000000] "Unit_WattHour" Vector__XXX
 SG_ HVEM_IstLeistungNA  : 15|9@1+ (50.000000,0.000000) [0.000000|25450.000000] "Unit_Watt" Motor_BEV
 SG_ HVEM_Leistung_Klima_Vorgabe  : 24|8@1+ (50.000000,0.000000) [0.000000|12650.000000] "Unit_Watt" Vector__XXX
 SG_ HVEM_Nutzbare_Energie  : 32|11@1+ (50.000000,0.000000) [0.000000|102200.000000] "Unit_WattHour" Vector__XXX
 SG_ HVEM_Energie_Klima_Vorgabe  : 43|8@1+ (50.000000,0.000000) [0.000000|12650.000000] "Unit_WattHour" Vector__XXX
 SG_ HVEM_HVK_Aktivitaet  : 51|2@1+ (1.000000,0.000000) [0.000000|3.000000] "" Motor_BEV
 SG_ HVEM_Pruefpuls_Anf  : 53|2@1+ (1.000000,0.000000) [0.000000|3.000000] "" Motor_BEV
 SG_ HVEM_HV_Anf  : 62|1@1+ (1.000000,0.000000) [0.000000|1.000000] "" Motor_BEV
 SG_ HVEM_MO_MaxLeistungIgnoriert  : 63|1@1+ (1.000000,0.000000) [0.000000|1.000000] "" Vector__XXX

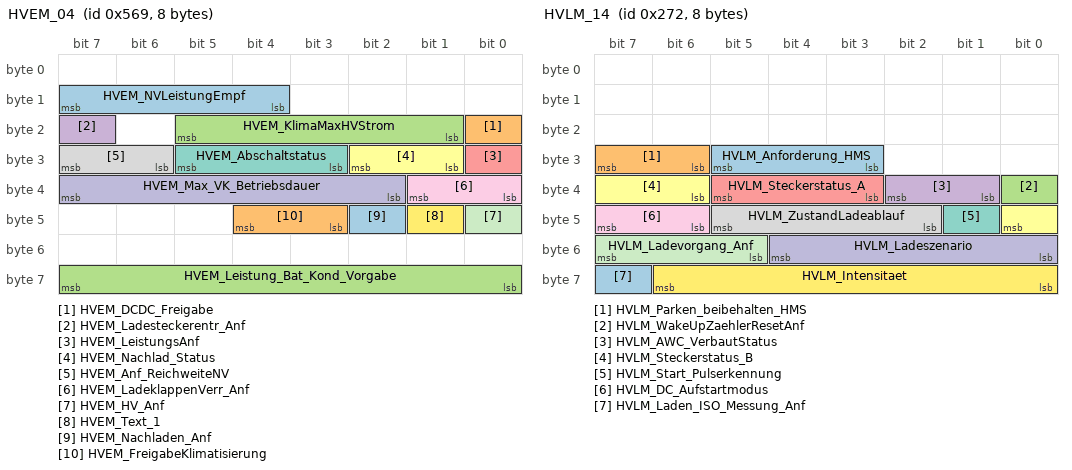
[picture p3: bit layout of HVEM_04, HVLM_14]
BO_ 1385 HVEM_04: 8 ICAS1_Gateway
 SG_ HVEM_NVLeistungEmpf  : 12|4@1+ (100.000000,0.000000) [0.000000|1500.000000] "Unit_Watt" Vector__XXX
 SG_ HVEM_DCDC_Freigabe  : 16|1@1+ (1.000000,0.000000) [0.000000|1.000000] "" Motor_BEV
 SG_ HVEM_KlimaMaxHVStrom  : 17|5@1+ (1.000000,0.000000) [0.000000|31.000000] "Unit_Amper" Vector__XXX
 SG_ HVEM_Ladesteckerentr_Anf  : 23|1@1+ (1.000000,0.000000) [0.000000|1.000000] "" Vector__XXX
 SG_ HVEM_LeistungsAnf  : 24|1@1+ (1.000000,0.000000) [0.000000|1.000000] "" Vector__XXX
 SG_ HVEM_Nachlad_Status  : 25|2@1+ (1.000000,0.000000) [0.000000|3.000000] "" Vector__XXX
 SG_ HVEM_Abschaltstatus  : 27|3@1+ (1.000000,0.000000) [0.000000|7.000000] "" Vector__XXX
 SG_ HVEM_Anf_ReichweiteNV  : 30|2@1+ (1.000000,0.000000) [0.000000|3.000000] "" Vector__XXX
 SG_ HVEM_LadeklappenVerr_Anf  : 32|2@1+ (1.000000,0.000000) [0.000000|3.000000] "" Vector__XXX
 SG_ HVEM_Max_VK_Betriebsdauer  : 34|6@1+ (1.000000,0.000000) [0.000000|60.000000] "Unit_Minut" Vector__XXX
 SG_ HVEM_HV_Anf  : 40|1@1+ (1.000000,0.000000) [0.000000|1.000000] "" Vector__XXX
 SG_ HVEM_Text_1  : 41|1@1+ (1.000000,0.000000) [0.000000|1.000000] "" Vector__XXX
 SG_ HVEM_Nachladen_Anf  : 42|1@1+ (1.000000,0.000000) [0.000000|1.000000] "" Vector__XXX
 SG_ HVEM_FreigabeKlimatisierung  : 43|2@1+ (1.000000,0.000000) [0.000000|3.000000] "" Vector__XXX
 SG_ HVEM_Leistung_Bat_Kond_Vorgabe  : 56|8@1+ (50.000000,0.000000) [0.000000|12650.000000] "Unit_Watt" Vector__XXX

BO_ 1283 HVK_01: 8 Motor_BEV
 SG_ HVK_01_CRC  : 0|8@1+ (1.000000,0.000000) [0.000000|255.000000] "" ICAS1_Gateway LE1 LE2
 SG_ HVK_01_BZ  : 8|4@1+ (1.000000,0.000000) [0.000000|15.000000] "" ICAS1_Gateway LE1 LE2
 SG_ HVK_Istmodus_Anf  : 12|1@1+ (1.000000,0.000000) [0.000000|1.000000] "" ICAS1_Gateway
 SG_ HVK_TN1_Sollmodus  : 13|2@1+ (1.000000,0.000000) [0.000000|3.000000] "" ICAS1_Gateway
 SG_ HVK_Vorladung_aktiv  : 15|1@1+ (1.000000,0.000000) [0.000000|1.000000] "" ICAS1_Gateway
 SG_ HVK_BMS_Sollmodus  : 24|3@1+ (1.000000,0.000000) [0.000000|7.000000] "" ICAS1_Gateway
 SG_ HVK_DCDC_Sollmodus  : 27|3@1+ (1.000000,0.000000) [0.000000|7.000000] "" ICAS1_Gateway
 SG_ HVK_EKK_Sollmodus  : 30|3@1+ (1.000000,0.000000) [0.000000|7.000000] "" ICAS1_Gateway
 SG_ HVK_HVPTC_Sollmodus  : 33|3@1+ (1.000000,0.000000) [0.000000|7.000000] "" ICAS1_Gateway
 SG_ HVK_HVLM_Sollmodus  : 36|3@1+ (1.000000,0.000000) [0.000000|7.000000] "" ICAS1_Gateway
 SG_ HVK_HV_Netz_Warnungen  : 39|2@1+ (1.000000,0.000000) [0.000000|3.000000] "" ICAS1_Gateway ICAS1_KommunikationsServer
 SG_ HV_Bordnetz_aktiv  : 41|1@1+ (1.000000,0.000000) [0.000000|1.000000] "" ICAS1_Gateway LE1 LE2
 SG_ HV_Bordnetz_Fehler  : 42|1@1+ (1.000000,0.000000) [0.000000|1.000000] "" ICAS1_Gateway
 SG_ HVK_Gesamtst_Spgfreiheit  : 43|2@1+ (1.000000,0.000000) [0.000000|3.000000] "" ICAS1_Gateway ICAS1_KommunikationsServer
 SG_ HVK_AktiveEntladung_Anf  : 45|1@1+ (1.000000,0.000000) [0.000000|1.000000] "" ICAS1_Gateway LE1 LE2
 SG_ HVK_HVEM_Freigabe  : 46|2@1+ (1.000000,0.000000) [0.000000|3.000000] "" ICAS1_Gateway
 SG_ HVK_Notentladung_Anf  : 48|2@1+ (1.000000,0.000000) [0.000000|3.000000] "" ICAS1_Gateway LE1 LE2
 SG_ HVK_Iso_Messung_Start  : 50|3@1+ (1.000000,0.000000) [0.000000|7.000000] "" ICAS1_Gateway
 SG_ HVK_Ladebereit  : 53|3@1+ (1.000000,0.000000) [0.000000|7.000000] "" ICAS1_Gateway
 SG_ HVK_PPulsFreigabe  : 56|2@1+ (1.000000,0.000000) [0.000000|3.000000] "" ICAS1_Gateway

BO_ 2463978813 HVL_01: 8 ICAS1_Gateway
 SG_ HVL_01_CRC  : 0|8@1+ (1.000000,0.000000) [0.000000|255.000000] "" Motor_BEV
 SG_ HVL_01_BZ  : 8|4@1+ (1.000000,0.000000) [0.000000|15.000000] "" Motor_BEV
 SG_ HVL_Steckerstatus  : 12|2@1+ (1.000000,0.000000) [0.000000|3.000000] "" Motor_BEV
 SG_ HVL_LadeAnforderung  : 24|3@1+ (1.000000,0.000000) [0.000000|7.000000] "" Motor_BEV

BO_ 626 HVLM_14: 8 ICAS1_Gateway
 SG_ HVLM_Anforderung_HMS  : 27|3@1+ (1.000000,0.000000) [0.000000|7.000000] "" Vector__XXX
 SG_ HVLM_Parken_beibehalten_HMS  : 30|2@1+ (1.000000,0.000000) [0.000000|3.000000] "" Vector__XXX
 SG_ HVLM_WakeUpZaehlerResetAnf  : 32|1@1+ (1.000000,0.000000) [0.000000|1.000000] "" Vector__XXX
 SG_ HVLM_AWC_VerbautStatus  : 33|2@1+ (1.000000,0.000000) [0.000000|3.000000] "" Motor_BEV
 SG_ HVLM_Steckerstatus_A  : 35|3@1+ (1.000000,0.000000) [0.000000|7.000000] "" Motor_BEV
 SG_ HVLM_Steckerstatus_B  : 38|3@1+ (1.000000,0.000000) [0.000000|7.000000] "" Vector__XXX
 SG_ HVLM_Start_Pulserkennung  : 41|1@1+ (1.000000,0.000000) [0.000000|1.000000] "" Vector__XXX
 SG_ HVLM_ZustandLadeablauf  : 42|4@1+ (1.000000,0.000000) [0.000000|15.000000] "" Motor_BEV
 SG_ HVLM_DC_Aufstartmodus  : 46|2@1+ (1.000000,0.000000) [0.000000|3.000000] "" Motor_BEV
 SG_ HVLM_Ladeszenario  : 48|5@1+ (1.000000,0.000000) [0.000000|31.000000] "" Vector__XXX
 SG_ HVLM_Ladevorgang_Anf  : 53|3@1+ (1.000000,0.000000) [0.000000|7.000000] "" Motor_BEV
 SG_ HVLM_Intensitaet  : 56|7@1+ (1.000000,0.000000) [0.000000|100.000000] "Unit_PerCent" Vector__XXX
 SG_ HVLM_Laden_ISO_Messung_Anf  : 63|1@1+ (1.000000,0.000000) [0.000000|1.000000] "" Motor_BEV

BO_ 268 IMMO_CORD_01: 8 Motor_BEV
 SG_ ImoCord_Auth_Aufforderung_WFS  : 63|1@1+ (1.000000,0.000000) [0.000000|1.000000] "" LE1 LE2

BO_ 23 IMMO_MSG3_Antwort: 8 ICAS1_Gateway
 SG_ WFS_IMMO_MSG3_CRC  : 0|32@1+ (1.000000,0.000000) [0.000000|4294967295.000000] "" LE2
 SG_ WFS_IMMO_MSG3_Status  : 56|8@1+ (1.000000,0.000000) [0.000000|255.000000] "" LE2

BO_ 25 IMMO_MSG4_Antwort: 8 ICAS1_Gateway
 SG_ WFS_IMMO_MSG4_CRC  : 0|32@1+ (1.000000,0.000000) [0.000000|4294967295.000000] "" LE1
 SG_ WFS_IMMO_MSG4_Status  : 56|8@1+ (1.000000,0.000000) [0.000000|255.000000] "" LE1

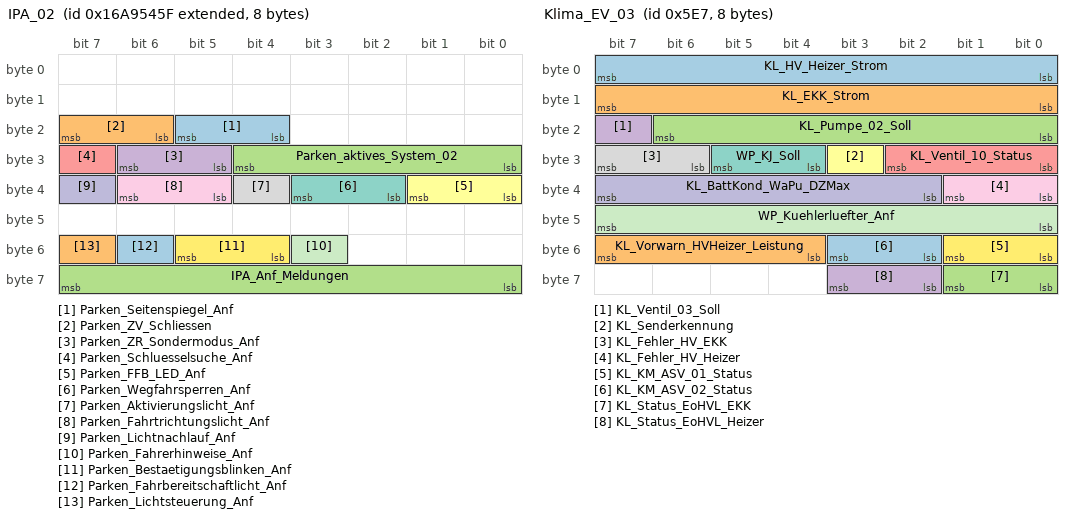
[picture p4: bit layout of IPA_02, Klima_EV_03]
BO_ 2527679583 IPA_02: 8 ICAS1_Gateway
 SG_ Parken_Seitenspiegel_Anf  : 20|2@1+ (1.000000,0.000000) [0.000000|3.000000] "" Vector__XXX
 SG_ Parken_ZV_Schliessen  : 22|2@1+ (1.000000,0.000000) [0.000000|3.000000] "" Vector__XXX
 SG_ Parken_aktives_System_02  : 24|5@1+ (1.000000,0.000000) [0.000000|31.000000] "" Vector__XXX
 SG_ Parken_ZR_Sondermodus_Anf  : 29|2@1+ (1.000000,0.000000) [0.000000|3.000000] "" Vector__XXX
 SG_ Parken_Schluesselsuche_Anf  : 31|1@1+ (1.000000,0.000000) [0.000000|1.000000] "" Vector__XXX
 SG_ Parken_FFB_LED_Anf  : 32|2@1+ (1.000000,0.000000) [0.000000|3.000000] "" Vector__XXX
 SG_ Parken_Wegfahrsperren_Anf  : 34|2@1+ (1.000000,0.000000) [0.000000|3.000000] "" LE1 LE2
 SG_ Parken_Aktivierungslicht_Anf  : 36|1@1+ (1.000000,0.000000) [0.000000|1.000000] "" Vector__XXX
 SG_ Parken_Fahrtrichtungslicht_Anf  : 37|2@1+ (1.000000,0.000000) [0.000000|3.000000] "" Vector__XXX
 SG_ Parken_Lichtnachlauf_Anf  : 39|1@1+ (1.000000,0.000000) [0.000000|1.000000] "" Vector__XXX
 SG_ Parken_Fahrerhinweise_Anf  : 51|1@1+ (1.000000,0.000000) [0.000000|1.000000] "" Vector__XXX
 SG_ Parken_Bestaetigungsblinken_Anf  : 52|2@1+ (1.000000,0.000000) [0.000000|3.000000] "" Vector__XXX
 SG_ Parken_Fahrbereitschaftlicht_Anf  : 54|1@1+ (1.000000,0.000000) [0.000000|1.000000] "" Vector__XXX
 SG_ Parken_Lichtsteuerung_Anf  : 55|1@1+ (1.000000,0.000000) [0.000000|1.000000] "" Vector__XXX
 SG_ IPA_Anf_Meldungen  : 56|8@1+ (1.000000,0.000000) [0.000000|255.000000] "" Vector__XXX

BO_ 1813 ISO_Airbag_01_Req: 8 ICAS1_Gateway
 SG_ ISO_Airbag_01_Req_Data  : 0|64@1+ (1.000000,0.000000) [0.000000|18446744073709551616.000000] "" Airbag

BO_ 1919 ISO_Airbag_01_Resp: 8 Airbag
 SG_ ISO_Airbag_01_Resp_Data  : 0|64@1+ (1.000000,0.000000) [0.000000|18446744073709551616.000000] "" ICAS1_Gateway

BO_ 1792 ISO_Funktionaler_Req_All: 8 ICAS1_Gateway
 SG_ ISO_ALL_01_Req_Data  : 0|64@1+ (1.000000,0.000000) [0.000000|18446744073709551616.000000] "" Airbag LE1 LE2 Motor_BEV

BO_ 2621440021 ISOx_Airbag_01_Req_FD: 64 ICAS1_Gateway
 SG_ ISOx_Airbag_01_Req_FD_Data  : 0|512@1+ (1.000000,0.000000) [0.000000|13407807929942597099574024998205846127479365820592393377723561443721764030073546976801874298166903427690031858186486050853753882811946569946433649006084096.000000] "" Airbag

BO_ 2621571093 ISOx_Airbag_01_Resp_FD: 64 Airbag
 SG_ ISOx_Airbag_01_Resp_FD_Data  : 0|512@1+ (1.000000,0.000000) [0.000000|13407807929942597099574024998205846127479365820592393377723561443721764030073546976801874298166903427690031858186486050853753882811946569946433649006084096.000000] "" ICAS1_Gateway

BO_ 2549874812 ISOx_EMotor_01_Req: 8 ICAS1_Gateway
 SG_ ISO_EMotor_01_Req_Data  : 0|64@1+ (1.000000,0.000000) [0.000000|18446744073709551616.000000] "" LE1

BO_ 2621440124 ISOx_EMotor_01_Req_FD: 64 ICAS1_Gateway
 SG_ ISOx_EMotor_01_Req_FD_Data  : 0|512@1+ (1.000000,0.000000) [0.000000|13407807929942597099574024998205846127479365820592393377723561443721764030073546976801874298166903427690031858186486050853753882811946569946433649006084096.000000] "" LE1

BO_ 2550005884 ISOx_EMotor_01_Resp: 8 LE1
 SG_ ISO_EMotor_01_Resp_Data  : 0|64@1+ (1.000000,0.000000) [0.000000|18446744073709551616.000000] "" ICAS1_Gateway

BO_ 2621571196 ISOx_EMotor_01_Resp_FD: 64 LE1
 SG_ ISOx_EMotor_01_Resp_FD_Data  : 0|512@1+ (1.000000,0.000000) [0.000000|13407807929942597099574024998205846127479365820592393377723561443721764030073546976801874298166903427690031858186486050853753882811946569946433649006084096.000000] "" ICAS1_Gateway

BO_ 2549874872 ISOx_EMotor_02_Req: 8 ICAS1_Gateway
 SG_ ISO_EMotor_02_Req_Data  : 0|64@1+ (1.000000,0.000000) [0.000000|18446744073709551616.000000] "" LE2

BO_ 2621440184 ISOx_EMotor_02_Req_FD: 64 ICAS1_Gateway
 SG_ ISOx_EMotor_02_Req_FD_Data  : 0|512@1+ (1.000000,0.000000) [0.000000|13407807929942597099574024998205846127479365820592393377723561443721764030073546976801874298166903427690031858186486050853753882811946569946433649006084096.000000] "" LE2

BO_ 2550005944 ISOx_EMotor_02_Resp: 8 LE2
 SG_ ISO_EMotor_02_Resp_Data  : 0|64@1+ (1.000000,0.000000) [0.000000|18446744073709551616.000000] "" ICAS1_Gateway

BO_ 2621571256 ISOx_EMotor_02_Resp_FD: 64 LE2
 SG_ ISOx_EMotor_02_Resp_FD_Data  : 0|512@1+ (1.000000,0.000000) [0.000000|13407807929942597099574024998205846127479365820592393377723561443721764030073546976801874298166903427690031858186486050853753882811946569946433649006084096.000000] "" ICAS1_Gateway

BO_ 2621505536 ISOx_Funkt_Req_All_FD: 64 ICAS1_Gateway
 SG_ ISOx_Funkt_Req_All_FD_Data  : 0|512@1+ (1.000000,0.000000) [0.000000|13407807929942597099574024998205846127479365820592393377723561443721764030073546976801874298166903427690031858186486050853753882811946569946433649006084096.000000] "" Airbag LE1 LE2 Motor_BEV

BO_ 2549874806 ISOx_MO_01_Req: 8 ICAS1_Gateway
 SG_ ISOx_MO_01_Req_Data  : 0|64@1+ (1.000000,0.000000) [0.000000|18446744073709551616.000000] "" Motor_BEV

BO_ 2621440118 ISOx_MO_01_Req_FD: 64 ICAS1_Gateway
 SG_ ISOx_MO_01_Req_FD_Data  : 0|512@1+ (1.000000,0.000000) [0.000000|13407807929942597099574024998205846127479365820592393377723561443721764030073546976801874298166903427690031858186486050853753882811946569946433649006084096.000000] "" Motor_BEV

BO_ 2550005878 ISOx_MO_01_Resp: 8 Motor_BEV
 SG_ ISOx_MO_01_Resp_Data  : 0|64@1+ (1.000000,0.000000) [0.000000|18446744073709551616.000000] "" ICAS1_Gateway

BO_ 2621571190 ISOx_MO_01_Resp_FD: 64 Motor_BEV
 SG_ ISOx_MO_01_Resp_FD_Data  : 0|512@1+ (1.000000,0.000000) [0.000000|13407807929942597099574024998205846127479365820592393377723561443721764030073546976801874298166903427690031858186486050853753882811946569946433649006084096.000000] "" ICAS1_Gateway

BO_ 2527679684 Kamera_ASM_01: 8 ICAS1_Gateway
 SG_ Kamera_ASM_Ereignis  : 0|8@1+ (1.000000,0.000000) [1.000000|254.000000] "" Airbag
 SG_ Kamera_ASM_Zeitstempel  : 8|8@1+ (0.080000,0.000000) [0.000000|20.320000] "Unit_Secon" Airbag
 SG_ Kamera_ASM_Data_1  : 16|8@1+ (1.000000,0.000000) [0.000000|255.000000] "" Airbag
 SG_ Kamera_ASM_Data_2  : 24|8@1+ (1.000000,0.000000) [0.000000|255.000000] "" Airbag
 SG_ Kamera_ASM_Data_3  : 32|8@1+ (1.000000,0.000000) [0.000000|255.000000] "" Airbag
 SG_ Kamera_ASM_Data_4  : 40|8@1+ (1.000000,0.000000) [0.000000|255.000000] "" Airbag
 SG_ Kamera_ASM_Data_5  : 48|8@1+ (1.000000,0.000000) [0.000000|255.000000] "" Airbag
 SG_ Kamera_ASM_Data_6  : 56|8@1+ (1.000000,0.000000) [0.000000|255.000000] "" Airbag

BO_ 960 Klemmen_Status_01: 4 ICAS1_Gateway
 SG_ Klemmen_Status_01_CRC  : 0|8@1+ (1.000000,0.000000) [0.000000|255.000000] "" Motor_BEV
 SG_ Klemmen_Status_01_BZ  : 8|4@1+ (1.000000,0.000000) [0.000000|15.000000] "" Motor_BEV
 SG_ RSt_Fahrerhinweise  : 12|4@1+ (1.000000,0.000000) [0.000000|15.000000] "" Vector__XXX
 SG_ ZAS_Kl_S  : 16|1@1+ (1.000000,0.000000) [0.000000|1.000000] "" Vector__XXX
 SG_ ZAS_Kl_15  : 17|1@1+ (1.000000,0.000000) [0.000000|1.000000] "" Airbag LE1 LE2 Motor_BEV Schaltbetaetigung
 SG_ ZAS_Kl_X  : 18|1@1+ (1.000000,0.000000) [0.000000|1.000000] "" Vector__XXX
 SG_ ZAS_Kl_50_Startanforderung  : 19|1@1+ (1.000000,0.000000) [0.000000|1.000000] "" Motor_BEV
 SG_ BCM_Remotestart_Betrieb  : 20|1@1+ (1.000000,0.000000) [0.000000|1.000000] "" Vector__XXX
 SG_ ZAS_Kl_Infotainment  : 21|1@1+ (1.000000,0.000000) [0.000000|1.000000] "" Vector__XXX
 SG_ BCM_Remotestart_KL15_Anf  : 22|1@1+ (1.000000,0.000000) [0.000000|1.000000] "" Vector__XXX
 SG_ BCM_Remotestart_MO_Start  : 23|1@1+ (1.000000,0.000000) [0.000000|1.000000] "" Vector__XXX
 SG_ KST_Warn_P1_ZST_def  : 24|1@1+ (1.000000,0.000000) [0.000000|1.000000] "" Vector__XXX
 SG_ KST_Warn_P2_ZST_def  : 25|1@1+ (1.000000,0.000000) [0.000000|1.000000] "" Vector__XXX
 SG_ KST_Fahrerhinweis_1  : 26|1@1+ (1.000000,0.000000) [0.000000|1.000000] "" Vector__XXX
 SG_ KST_Fahrerhinweis_2  : 27|1@1+ (1.000000,0.000000) [0.000000|1.000000] "" Vector__XXX
 SG_ BCM_Ausparken_Betrieb  : 28|1@1+ (1.000000,0.000000) [0.000000|1.000000] "" Vector__XXX
 SG_ KST_Fahrerhinweis_4  : 29|1@1+ (1.000000,0.000000) [0.000000|1.000000] "" Vector__XXX
 SG_ KST_Fahrerhinweis_5  : 30|1@1+ (1.000000,0.000000) [0.000000|1.000000] "" Vector__XXX
 SG_ KST_Fahrerhinweis_6  : 31|1@1+ (1.000000,0.000000) [0.000000|1.000000] "" Vector__XXX

BO_ 2463978753 Klemmen_Status_02: 8 ICAS1_Gateway
 SG_ KST_WFS_Fahrfreigabe_Anforderung  : 12|2@1+ (1.000000,0.000000) [0.000000|3.000000] "" LE1 LE2
 SG_ KST_Sonderzustand_Status  : 14|2@1+ (1.000000,0.000000) [0.000000|3.000000] "" LE1 LE2
 SG_ KST_Sonderzustand_Anforderung  : 16|5@1+ (1.000000,0.000000) [0.000000|31.000000] "" LE1 LE2

BO_ 1420 Klemmen_Steuerung_01: 8 ICAS1_Gateway
 SG_ Klemmen_Steuerung_01_CRC  : 0|8@1+ (1.000000,0.000000) [0.000000|255.000000] "" Vector__XXX
 SG_ Klemmen_Steuerung_01_BZ  : 8|4@1+ (1.000000,0.000000) [0.000000|15.000000] "" Vector__XXX
 SG_ KST_Anf_Klemme_15  : 12|1@1+ (1.000000,0.000000) [0.000000|1.000000] "" Vector__XXX
 SG_ KST_Anf_Klemme_50  : 13|1@1+ (1.000000,0.000000) [0.000000|1.000000] "" Motor_BEV
 SG_ KST_Anf_Klemme_S  : 14|1@1+ (1.000000,0.000000) [0.000000|1.000000] "" Vector__XXX
 SG_ KST_Txt_Werkstatt  : 15|1@1+ (1.000000,0.000000) [0.000000|1.000000] "" Vector__XXX
 SG_ KST_Txt_P_Gang  : 16|1@1+ (1.000000,0.000000) [0.000000|1.000000] "" Vector__XXX
 SG_ KST_Txt_Panikabschaltung  : 17|1@1+ (1.000000,0.000000) [0.000000|1.000000] "" Vector__XXX
 SG_ KST_Anf_Klemmenfreigabe_ELV  : 18|1@1+ (1.000000,0.000000) [0.000000|1.000000] "" Vector__XXX
 SG_ KST_Txt_Komfortabschaltung  : 19|1@1+ (1.000000,0.000000) [0.000000|1.000000] "" Vector__XXX
 SG_ KST_ZAT_betaetigt  : 20|1@1+ (1.000000,0.000000) [0.000000|1.000000] "" Vector__XXX
 SG_ KST_Unterdr_Zuendungsmeldung  : 21|1@1+ (1.000000,0.000000) [0.000000|1.000000] "" Vector__XXX
 SG_ KST_aut_Abschaltung_Zuendung  : 22|1@1+ (1.000000,0.000000) [0.000000|1.000000] "" Vector__XXX
 SG_ KST_Anf_Klemmenfreigabe_WFS  : 23|1@1+ (1.000000,0.000000) [0.000000|1.000000] "" Vector__XXX
 SG_ KST_Anf_ZV_Verriegelung  : 24|1@1+ (1.000000,0.000000) [0.000000|1.000000] "" Vector__XXX
 SG_ Relais_VoKo_angesteuert  : 25|1@1+ (1.000000,0.000000) [0.000000|1.000000] "" Vector__XXX
 SG_ RSt_Anforderung_HMS  : 26|3@1+ (1.000000,0.000000) [0.000000|7.000000] "" Vector__XXX
 SG_ KST_Zuendungswarnung  : 29|2@1+ (1.000000,0.000000) [0.000000|3.000000] "" Vector__XXX
 SG_ KST_Fahrer_Info_Text  : 31|3@1+ (1.000000,0.000000) [0.000000|7.000000] "" Vector__XXX

BO_ 949 Klima_11: 8 ICAS1_Gateway
 SG_ KL_Drehz_Anh  : 0|1@1+ (1.000000,0.000000) [0.000000|1.000000] "" Vector__XXX
 SG_ KL_Vorwarn_Komp_ein  : 1|1@1+ (1.000000,0.000000) [0.000000|1.000000] "" Vector__XXX
 SG_ KL_AC_Schalter  : 2|1@1+ (1.000000,0.000000) [0.000000|1.000000] "" Vector__XXX
 SG_ KL_Komp_Moment_alt  : 3|1@1+ (1.000000,0.000000) [0.000000|1.000000] "" Vector__XXX
 SG_ KL_Vorwarn_Zuheizer_ein  : 6|1@1+ (1.000000,0.000000) [0.000000|1.000000] "" Vector__XXX
 SG_ KL_Zustand  : 7|1@1+ (1.000000,0.000000) [0.000000|1.000000] "" Vector__XXX
 SG_ KL_Kompressorkupplung_linear  : 8|8@1+ (20.000000,0.000000) [0.000000|4000.000000] "Unit_MilliAmper" Vector__XXX
 SG_ KL_Charisma_FahrPr  : 16|4@1+ (1.000000,0.000000) [0.000000|15.000000] "" Vector__XXX
 SG_ KL_Charisma_Status  : 20|2@1+ (1.000000,0.000000) [0.000000|3.000000] "" Vector__XXX
 SG_ KL_nachtr_Stopp_Anf  : 22|1@1+ (1.000000,0.000000) [0.000000|1.000000] "" Vector__XXX
 SG_ KL_T_Charge  : 23|1@1+ (1.000000,0.000000) [0.000000|1.000000] "" Vector__XXX
 SG_ KL_Last_Kompr  : 24|8@1+ (0.250000,0.000000) [0.000000|63.500000] "Unit_NewtoMeter" Vector__XXX
 SG_ KL_Spannungs_Anf  : 32|2@1+ (1.000000,0.000000) [0.000000|3.000000] "" Vector__XXX
 SG_ KL_Thermomanagement  : 34|2@1+ (1.000000,0.000000) [0.000000|3.000000] "" Motor_BEV
 SG_ KL_StartStopp_Info  : 36|2@1+ (1.000000,0.000000) [0.000000|3.000000] "" Vector__XXX
 SG_ KL_Freilauf_Info  : 38|2@1+ (1.000000,0.000000) [0.000000|3.000000] "" Vector__XXX
 SG_ KL_Anf_KL  : 40|8@1+ (0.400000,0.000000) [0.000000|101.600000] "Unit_PerCent" Motor_BEV
 SG_ KL_el_Zuheizer_Stufe  : 48|3@1+ (1.000000,0.000000) [0.000000|7.000000] "" Vector__XXX
 SG_ KL_Ausstattung_Klima  : 51|3@1+ (1.000000,0.000000) [0.000000|7.000000] "" Vector__XXX
 SG_ KL_Variante_Standheizung  : 54|2@1+ (1.000000,0.000000) [0.000000|3.000000] "" Vector__XXX
 SG_ KL_Anf_KV  : 57|7@1+ (1.000000,0.000000) [0.000000|100.000000] "Unit_PerCent" Motor_BEV

BO_ 1511 Klima_EV_03: 8 ICAS1_Gateway
 SG_ KL_HV_Heizer_Strom  : 0|8@1+ (0.250000,0.000000) [0.000000|63.500000] "Unit_Amper" Motor_BEV
 SG_ KL_EKK_Strom  : 8|8@1+ (0.250000,0.000000) [0.000000|63.500000] "Unit_Amper" Motor_BEV
 SG_ KL_Pumpe_02_Soll  : 16|7@1+ (1.000000,0.000000) [0.000000|100.000000] "Unit_PerCent" Motor_BEV
 SG_ KL_Ventil_03_Soll  : 23|1@1+ (1.000000,0.000000) [0.000000|1.000000] "" Vector__XXX
 SG_ KL_Ventil_10_Status  : 24|3@1+ (1.000000,0.000000) [0.000000|7.000000] "" Vector__XXX
 SG_ KL_Senderkennung  : 27|1@1+ (1.000000,0.000000) [0.000000|1.000000] "" Vector__XXX
 SG_ WP_KJ_Soll  : 28|2@1+ (1.000000,0.000000) [0.000000|3.000000] "" Vector__XXX
 SG_ KL_Fehler_HV_EKK  : 30|2@1+ (1.000000,0.000000) [0.000000|3.000000] "" Vector__XXX
 SG_ KL_Fehler_HV_Heizer  : 32|2@1+ (1.000000,0.000000) [0.000000|3.000000] "" Vector__XXX
 SG_ KL_BattKond_WaPu_DZMax  : 34|6@1+ (2.000000,0.000000) [0.000000|100.000000] "Unit_PerCent" Vector__XXX
 SG_ WP_Kuehlerluefter_Anf  : 40|8@1+ (0.400000,0.000000) [0.000000|101.600000] "Unit_PerCent" Vector__XXX
 SG_ KL_KM_ASV_01_Status  : 48|2@1+ (1.000000,0.000000) [0.000000|3.000000] "" Vector__XXX
 SG_ KL_KM_ASV_02_Status  : 50|2@1+ (1.000000,0.000000) [0.000000|3.000000] "" Vector__XXX
 SG_ KL_Vorwarn_HVHeizer_Leistung  : 52|4@1+ (1.000000,0.000000) [0.000000|15.000000] "" Vector__XXX
 SG_ KL_Status_EoHVL_EKK  : 56|2@1+ (1.000000,0.000000) [0.000000|3.000000] "" Motor_BEV
 SG_ KL_Status_EoHVL_Heizer  : 58|2@1+ (1.000000,0.000000) [0.000000|3.000000] "" Motor_BEV

BU_:  Airbag BAP_Tester ICAS1_Gateway ICAS1_KommunikationsServer LE1 LE2 Motor_BEV Schaltbetaetigung

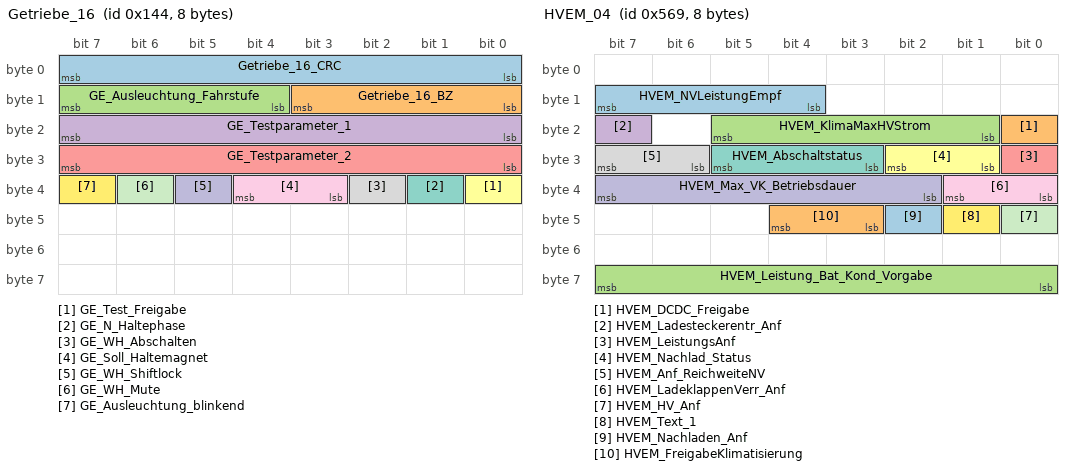
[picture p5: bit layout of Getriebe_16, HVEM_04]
BO_ 324 Getriebe_16: 8 Motor_BEV
 SG_ Getriebe_16_CRC  : 0|8@1+ (1.000000,0.000000) [0.000000|255.000000] "" ICAS1_Gateway Schaltbetaetigung
 SG_ Getriebe_16_BZ  : 8|4@1+ (1.000000,0.000000) [0.000000|15.000000] "" ICAS1_Gateway Schaltbetaetigung
 SG_ GE_Ausleuchtung_Fahrstufe  : 12|4@1+ (1.000000,0.000000) [0.000000|15.000000] "" ICAS1_Gateway Schaltbetaetigung
 SG_ GE_Testparameter_1  : 16|8@1+ (1.000000,0.000000) [0.000000|255.000000] "" ICAS1_Gateway Schaltbetaetigung
 SG_ GE_Testparameter_2  : 24|8@1+ (1.000000,0.000000) [0.000000|255.000000] "" ICAS1_Gateway Schaltbetaetigung
 SG_ GE_Test_Freigabe  : 32|1@1+ (1.000000,0.000000) [0.000000|1.000000] "" ICAS1_Gateway Schaltbetaetigung
 SG_ GE_N_Haltephase  : 33|1@1+ (1.000000,0.000000) [0.000000|1.000000] "" ICAS1_Gateway Schaltbetaetigung
 SG_ GE_WH_Abschalten  : 34|1@1+ (1.000000,0.000000) [0.000000|1.000000] "" ICAS1_Gateway Schaltbetaetigung
 SG_ GE_Soll_Haltemagnet  : 35|2@1+ (1.000000,0.000000) [0.000000|3.000000] "" ICAS1_Gateway Schaltbetaetigung
 SG_ GE_WH_Shiftlock  : 37|1@1+ (1.000000,0.000000) [0.000000|1.000000] "" ICAS1_Gateway Schaltbetaetigung
 SG_ GE_WH_Mute  : 38|1@1+ (1.000000,0.000000) [0.000000|1.000000] "" ICAS1_Gateway Schaltbetaetigung
 SG_ GE_Ausleuchtung_blinkend  : 39|1@1+ (1.000000,0.000000) [0.000000|1.000000] "" ICAS1_Gateway Schaltbetaetigung

BO_ 299 GRA_ACC_01: 8 ICAS1_Gateway
 SG_ GRA_ACC_01_CRC  : 0|8@1+ (1.000000,0.000000) [0.000000|255.000000] "" Motor_BEV
 SG_ GRA_ACC_01_BZ  : 8|4@1+ (1.000000,0.000000) [0.000000|15.000000] "" Motor_BEV
 SG_ GRA_Hauptschalter  : 12|1@1+ (1.000000,0.000000) [0.000000|1.000000] "" Motor_BEV
 SG_ GRA_Abbrechen  : 13|1@1+ (1.000000,0.000000) [0.000000|1.000000] "" Motor_BEV
 SG_ GRA_Typ_Hauptschalter  : 14|1@1+ (1.000000,0.000000) [0.000000|1.000000] "" Motor_BEV
 SG_ GRA_Limiter  : 15|1@1+ (1.000000,0.000000) [0.000000|1.000000] "" Motor_BEV
 SG_ GRA_Tip_Setzen  : 16|1@1+ (1.000000,0.000000) [0.000000|1.000000] "" Motor_BEV
 SG_ GRA_Tip_Hoch  : 17|1@1+ (1.000000,0.000000) [0.000000|1.000000] "" Motor_BEV
 SG_ GRA_Tip_Runter  : 18|1@1+ (1.000000,0.000000) [0.000000|1.000000] "" Motor_BEV
 SG_ GRA_Tip_Wiederaufnahme  : 19|1@1+ (1.000000,0.000000) [0.000000|1.000000] "" Motor_BEV
 SG_ GRA_Verstellung_Zeitluecke  : 20|2@1+ (1.000000,0.000000) [0.000000|3.000000] "" Vector__XXX
 SG_ GRA_Codierung  : 22|2@1+ (1.000000,0.000000) [0.000000|3.000000] "" Motor_BEV
 SG_ GRA_Fehler  : 24|1@1+ (1.000000,0.000000) [0.000000|1.000000] "" Motor_BEV
 SG_ GRA_LIM_Taste_verfuegbar  : 25|1@1+ (1.000000,0.000000) [0.000000|1.000000] "" Motor_BEV
 SG_ GRA_Tip_Stufe_2  : 26|1@1+ (1.000000,0.000000) [0.000000|1.000000] "" Motor_BEV
 SG_ GRA_Typ_Bedienteil  : 27|3@1+ (1.000000,0.000000) [0.000000|7.000000] "" Motor_BEV
 SG_ GRA_TravelAssist  : 30|1@1+ (1.000000,0.000000) [0.000000|1.000000] "" Vector__XXX
 SG_ GRA_reserveByte4  : 31|1@1+ (1.000000,0.000000) [0.000000|1.000000] "" Vector__XXX
 SG_ GRA_reserveByte5  : 32|8@1+ (1.000000,0.000000) [0.000000|255.000000] "" Vector__XXX
 SG_ GRA_reserveByte6  : 40|8@1+ (1.000000,0.000000) [0.000000|255.000000] "" Vector__XXX
 SG_ GRA_reserveByte7  : 48|8@1+ (1.000000,0.000000) [0.000000|255.000000] "" Vector__XXX
 SG_ GRA_reserveByte8  : 56|8@1+ (1.000000,0.000000) [0.000000|255.000000] "" Vector__XXX

BO_ 1452 HVEM_02: 8 ICAS1_Gateway
 SG_ HVEM_IstStrom_HVVerbraucher  : 0|12@1+ (0.100000,-204.700000) [-204.700000|204.600000] "Unit_Amper" Vector__XXX
 SG_ HVEM_Energie_Klima_Vorgabe_HighR  : 12|3@1+ (10.000000,0.000000) [0.000000|50.000000] "Unit_WattHour" Vector__XXX
 SG_ HVEM_IstLeistungNA  : 15|9@1+ (50.000000,0.000000) [0.000000|25450.000000] "Unit_Watt" Motor_BEV
 SG_ HVEM_Leistung_Klima_Vorgabe  : 24|8@1+ (50.000000,0.000000) [0.000000|12650.000000] "Unit_Watt" Vector__XXX
 SG_ HVEM_Nutzbare_Energie  : 32|11@1+ (50.000000,0.000000) [0.000000|102200.000000] "Unit_WattHour" Vector__XXX
 SG_ HVEM_Energie_Klima_Vorgabe  : 43|8@1+ (50.000000,0.000000) [0.000000|12650.000000] "Unit_WattHour" Vector__XXX
 SG_ HVEM_HVK_Aktivitaet  : 51|2@1+ (1.000000,0.000000) [0.000000|3.000000] "" Motor_BEV
 SG_ HVEM_Pruefpuls_Anf  : 53|2@1+ (1.000000,0.000000) [0.000000|3.000000] "" Motor_BEV
 SG_ HVEM_HV_Anf  : 62|1@1+ (1.000000,0.000000) [0.000000|1.000000] "" Motor_BEV
 SG_ HVEM_MO_MaxLeistungIgnoriert  : 63|1@1+ (1.000000,0.000000) [0.000000|1.000000] "" Vector__XXX

BO_ 1385 HVEM_04: 8 ICAS1_Gateway
 SG_ HVEM_NVLeistungEmpf  : 12|4@1+ (100.000000,0.000000) [0.000000|1500.000000] "Unit_Watt" Vector__XXX
 SG_ HVEM_DCDC_Freigabe  : 16|1@1+ (1.000000,0.000000) [0.000000|1.000000] "" Motor_BEV
 SG_ HVEM_KlimaMaxHVStrom  : 17|5@1+ (1.000000,0.000000) [0.000000|31.000000] "Unit_Amper" Vector__XXX
 SG_ HVEM_Ladesteckerentr_Anf  : 23|1@1+ (1.000000,0.000000) [0.000000|1.000000] "" Vector__XXX
 SG_ HVEM_LeistungsAnf  : 24|1@1+ (1.000000,0.000000) [0.000000|1.000000] "" Vector__XXX
 SG_ HVEM_Nachlad_Status  : 25|2@1+ (1.000000,0.000000) [0.000000|3.000000] "" Vector__XXX
 SG_ HVEM_Abschaltstatus  : 27|3@1+ (1.000000,0.000000) [0.000000|7.000000] "" Vector__XXX
 SG_ HVEM_Anf_ReichweiteNV  : 30|2@1+ (1.000000,0.000000) [0.000000|3.000000] "" Vector__XXX
 SG_ HVEM_LadeklappenVerr_Anf  : 32|2@1+ (1.000000,0.000000) [0.000000|3.000000] "" Vector__XXX
 SG_ HVEM_Max_VK_Betriebsdauer  : 34|6@1+ (1.000000,0.000000) [0.000000|60.000000] "Unit_Minut" Vector__XXX
 SG_ HVEM_HV_Anf  : 40|1@1+ (1.000000,0.000000) [0.000000|1.000000] "" Vector__XXX
 SG_ HVEM_Text_1  : 41|1@1+ (1.000000,0.000000) [0.000000|1.000000] "" Vector__XXX
 SG_ HVEM_Nachladen_Anf  : 42|1@1+ (1.000000,0.000000) [0.000000|1.000000] "" Vector__XXX
 SG_ HVEM_FreigabeKlimatisierung  : 43|2@1+ (1.000000,0.000000) [0.000000|3.000000] "" Vector__XXX
 SG_ HVEM_Leistung_Bat_Kond_Vorgabe  : 56|8@1+ (50.000000,0.000000) [0.000000|12650.000000] "Unit_Watt" Vector__XXX

BO_ 1283 HVK_01: 8 Motor_BEV
 SG_ HVK_01_CRC  : 0|8@1+ (1.000000,0.000000) [0.000000|255.000000] "" ICAS1_Gateway LE1 LE2
 SG_ HVK_01_BZ  : 8|4@1+ (1.000000,0.000000) [0.000000|15.000000] "" ICAS1_Gateway LE1 LE2
 SG_ HVK_Istmodus_Anf  : 12|1@1+ (1.000000,0.000000) [0.000000|1.000000] "" ICAS1_Gateway
 SG_ HVK_TN1_Sollmodus  : 13|2@1+ (1.000000,0.000000) [0.000000|3.000000] "" ICAS1_Gateway
 SG_ HVK_Vorladung_aktiv  : 15|1@1+ (1.000000,0.000000) [0.000000|1.000000] "" ICAS1_Gateway
 SG_ HVK_BMS_Sollmodus  : 24|3@1+ (1.000000,0.000000) [0.000000|7.000000] "" ICAS1_Gateway
 SG_ HVK_DCDC_Sollmodus  : 27|3@1+ (1.000000,0.000000) [0.000000|7.000000] "" ICAS1_Gateway
 SG_ HVK_EKK_Sollmodus  : 30|3@1+ (1.000000,0.000000) [0.000000|7.000000] "" ICAS1_Gateway
 SG_ HVK_HVPTC_Sollmodus  : 33|3@1+ (1.000000,0.000000) [0.000000|7.000000] "" ICAS1_Gateway
 SG_ HVK_HVLM_Sollmodus  : 36|3@1+ (1.000000,0.000000) [0.000000|7.000000] "" ICAS1_Gateway
 SG_ HVK_HV_Netz_Warnungen  : 39|2@1+ (1.000000,0.000000) [0.000000|3.000000] "" ICAS1_Gateway ICAS1_KommunikationsServer
 SG_ HV_Bordnetz_aktiv  : 41|1@1+ (1.000000,0.000000) [0.000000|1.000000] "" ICAS1_Gateway LE1 LE2
 SG_ HV_Bordnetz_Fehler  : 42|1@1+ (1.000000,0.000000) [0.000000|1.000000] "" ICAS1_Gateway
 SG_ HVK_Gesamtst_Spgfreiheit  : 43|2@1+ (1.000000,0.000000) [0.000000|3.000000] "" ICAS1_Gateway ICAS1_KommunikationsServer
 SG_ HVK_AktiveEntladung_Anf  : 45|1@1+ (1.000000,0.000000) [0.000000|1.000000] "" ICAS1_Gateway LE1 LE2
 SG_ HVK_HVEM_Freigabe  : 46|2@1+ (1.000000,0.000000) [0.000000|3.000000] "" ICAS1_Gateway
 SG_ HVK_Notentladung_Anf  : 48|2@1+ (1.000000,0.000000) [0.000000|3.000000] "" ICAS1_Gateway LE1 LE2
 SG_ HVK_Iso_Messung_Start  : 50|3@1+ (1.000000,0.000000) [0.000000|7.000000] "" ICAS1_Gateway
 SG_ HVK_Ladebereit  : 53|3@1+ (1.000000,0.000000) [0.000000|7.000000] "" ICAS1_Gateway
 SG_ HVK_PPulsFreigabe  : 56|2@1+ (1.000000,0.000000) [0.000000|3.000000] "" ICAS1_Gateway

BO_ 2463978813 HVL_01: 8 ICAS1_Gateway
 SG_ HVL_01_CRC  : 0|8@1+ (1.000000,0.000000) [0.000000|255.000000] "" Motor_BEV
 SG_ HVL_01_BZ  : 8|4@1+ (1.000000,0.000000) [0.000000|15.000000] "" Motor_BEV
 SG_ HVL_Steckerstatus  : 12|2@1+ (1.000000,0.000000) [0.000000|3.000000] "" Motor_BEV
 SG_ HVL_LadeAnforderung  : 24|3@1+ (1.000000,0.000000) [0.000000|7.000000] "" Motor_BEV

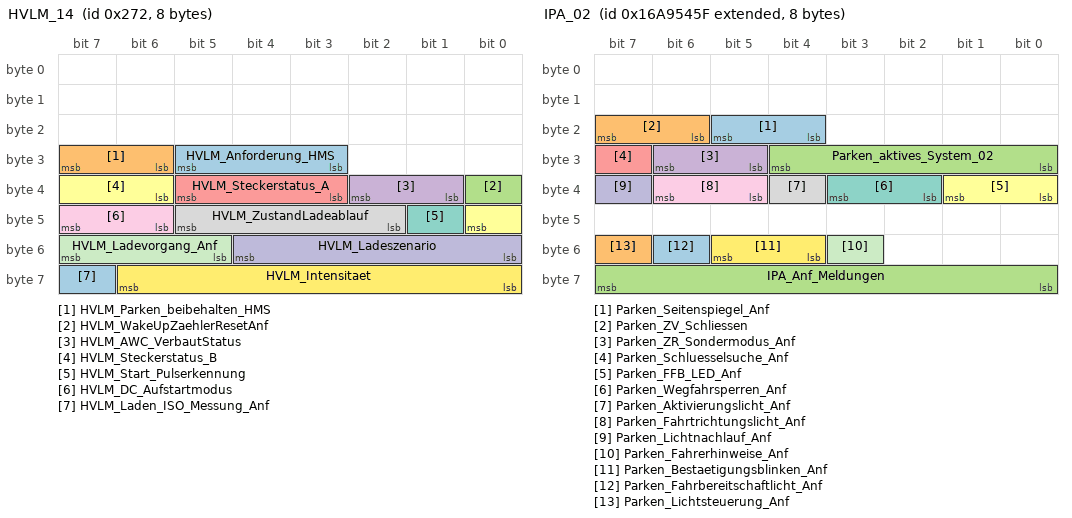
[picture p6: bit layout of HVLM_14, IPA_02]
BO_ 626 HVLM_14: 8 ICAS1_Gateway
 SG_ HVLM_Anforderung_HMS  : 27|3@1+ (1.000000,0.000000) [0.000000|7.000000] "" Vector__XXX
 SG_ HVLM_Parken_beibehalten_HMS  : 30|2@1+ (1.000000,0.000000) [0.000000|3.000000] "" Vector__XXX
 SG_ HVLM_WakeUpZaehlerResetAnf  : 32|1@1+ (1.000000,0.000000) [0.000000|1.000000] "" Vector__XXX
 SG_ HVLM_AWC_VerbautStatus  : 33|2@1+ (1.000000,0.000000) [0.000000|3.000000] "" Motor_BEV
 SG_ HVLM_Steckerstatus_A  : 35|3@1+ (1.000000,0.000000) [0.000000|7.000000] "" Motor_BEV
 SG_ HVLM_Steckerstatus_B  : 38|3@1+ (1.000000,0.000000) [0.000000|7.000000] "" Vector__XXX
 SG_ HVLM_Start_Pulserkennung  : 41|1@1+ (1.000000,0.000000) [0.000000|1.000000] "" Vector__XXX
 SG_ HVLM_ZustandLadeablauf  : 42|4@1+ (1.000000,0.000000) [0.000000|15.000000] "" Motor_BEV
 SG_ HVLM_DC_Aufstartmodus  : 46|2@1+ (1.000000,0.000000) [0.000000|3.000000] "" Motor_BEV
 SG_ HVLM_Ladeszenario  : 48|5@1+ (1.000000,0.000000) [0.000000|31.000000] "" Vector__XXX
 SG_ HVLM_Ladevorgang_Anf  : 53|3@1+ (1.000000,0.000000) [0.000000|7.000000] "" Motor_BEV
 SG_ HVLM_Intensitaet  : 56|7@1+ (1.000000,0.000000) [0.000000|100.000000] "Unit_PerCent" Vector__XXX
 SG_ HVLM_Laden_ISO_Messung_Anf  : 63|1@1+ (1.000000,0.000000) [0.000000|1.000000] "" Motor_BEV

BO_ 268 IMMO_CORD_01: 8 Motor_BEV
 SG_ ImoCord_Auth_Aufforderung_WFS  : 63|1@1+ (1.000000,0.000000) [0.000000|1.000000] "" LE1 LE2

BO_ 23 IMMO_MSG3_Antwort: 8 ICAS1_Gateway
 SG_ WFS_IMMO_MSG3_CRC  : 0|32@1+ (1.000000,0.000000) [0.000000|4294967295.000000] "" LE2
 SG_ WFS_IMMO_MSG3_Status  : 56|8@1+ (1.000000,0.000000) [0.000000|255.000000] "" LE2

BO_ 25 IMMO_MSG4_Antwort: 8 ICAS1_Gateway
 SG_ WFS_IMMO_MSG4_CRC  : 0|32@1+ (1.000000,0.000000) [0.000000|4294967295.000000] "" LE1
 SG_ WFS_IMMO_MSG4_Status  : 56|8@1+ (1.000000,0.000000) [0.000000|255.000000] "" LE1

BO_ 2527679583 IPA_02: 8 ICAS1_Gateway
 SG_ Parken_Seitenspiegel_Anf  : 20|2@1+ (1.000000,0.000000) [0.000000|3.000000] "" Vector__XXX
 SG_ Parken_ZV_Schliessen  : 22|2@1+ (1.000000,0.000000) [0.000000|3.000000] "" Vector__XXX
 SG_ Parken_aktives_System_02  : 24|5@1+ (1.000000,0.000000) [0.000000|31.000000] "" Vector__XXX
 SG_ Parken_ZR_Sondermodus_Anf  : 29|2@1+ (1.000000,0.000000) [0.000000|3.000000] "" Vector__XXX
 SG_ Parken_Schluesselsuche_Anf  : 31|1@1+ (1.000000,0.000000) [0.000000|1.000000] "" Vector__XXX
 SG_ Parken_FFB_LED_Anf  : 32|2@1+ (1.000000,0.000000) [0.000000|3.000000] "" Vector__XXX
 SG_ Parken_Wegfahrsperren_Anf  : 34|2@1+ (1.000000,0.000000) [0.000000|3.000000] "" LE1 LE2
 SG_ Parken_Aktivierungslicht_Anf  : 36|1@1+ (1.000000,0.000000) [0.000000|1.000000] "" Vector__XXX
 SG_ Parken_Fahrtrichtungslicht_Anf  : 37|2@1+ (1.000000,0.000000) [0.000000|3.000000] "" Vector__XXX
 SG_ Parken_Lichtnachlauf_Anf  : 39|1@1+ (1.000000,0.000000) [0.000000|1.000000] "" Vector__XXX
 SG_ Parken_Fahrerhinweise_Anf  : 51|1@1+ (1.000000,0.000000) [0.000000|1.000000] "" Vector__XXX
 SG_ Parken_Bestaetigungsblinken_Anf  : 52|2@1+ (1.000000,0.000000) [0.000000|3.000000] "" Vector__XXX
 SG_ Parken_Fahrbereitschaftlicht_Anf  : 54|1@1+ (1.000000,0.000000) [0.000000|1.000000] "" Vector__XXX
 SG_ Parken_Lichtsteuerung_Anf  : 55|1@1+ (1.000000,0.000000) [0.000000|1.000000] "" Vector__XXX
 SG_ IPA_Anf_Meldungen  : 56|8@1+ (1.000000,0.000000) [0.000000|255.000000] "" Vector__XXX

BO_ 1813 ISO_Airbag_01_Req: 8 ICAS1_Gateway
 SG_ ISO_Airbag_01_Req_Data  : 0|64@1+ (1.000000,0.000000) [0.000000|18446744073709551616.000000] "" Airbag

BO_ 1919 ISO_Airbag_01_Resp: 8 Airbag
 SG_ ISO_Airbag_01_Resp_Data  : 0|64@1+ (1.000000,0.000000) [0.000000|18446744073709551616.000000] "" ICAS1_Gateway

BO_ 1792 ISO_Funktionaler_Req_All: 8 ICAS1_Gateway
 SG_ ISO_ALL_01_Req_Data  : 0|64@1+ (1.000000,0.000000) [0.000000|18446744073709551616.000000] "" Airbag LE1 LE2 Motor_BEV

BO_ 2621440021 ISOx_Airbag_01_Req_FD: 64 ICAS1_Gateway
 SG_ ISOx_Airbag_01_Req_FD_Data  : 0|512@1+ (1.000000,0.000000) [0.000000|13407807929942597099574024998205846127479365820592393377723561443721764030073546976801874298166903427690031858186486050853753882811946569946433649006084096.000000] "" Airbag

BO_ 2621571093 ISOx_Airbag_01_Resp_FD: 64 Airbag
 SG_ ISOx_Airbag_01_Resp_FD_Data  : 0|512@1+ (1.000000,0.000000) [0.000000|13407807929942597099574024998205846127479365820592393377723561443721764030073546976801874298166903427690031858186486050853753882811946569946433649006084096.000000] "" ICAS1_Gateway

BO_ 2549874812 ISOx_EMotor_01_Req: 8 ICAS1_Gateway
 SG_ ISO_EMotor_01_Req_Data  : 0|64@1+ (1.000000,0.000000) [0.000000|18446744073709551616.000000] "" LE1

BO_ 2621440124 ISOx_EMotor_01_Req_FD: 64 ICAS1_Gateway
 SG_ ISOx_EMotor_01_Req_FD_Data  : 0|512@1+ (1.000000,0.000000) [0.000000|13407807929942597099574024998205846127479365820592393377723561443721764030073546976801874298166903427690031858186486050853753882811946569946433649006084096.000000] "" LE1

BO_ 2550005884 ISOx_EMotor_01_Resp: 8 LE1
 SG_ ISO_EMotor_01_Resp_Data  : 0|64@1+ (1.000000,0.000000) [0.000000|18446744073709551616.000000] "" ICAS1_Gateway

BO_ 2621571196 ISOx_EMotor_01_Resp_FD: 64 LE1
 SG_ ISOx_EMotor_01_Resp_FD_Data  : 0|512@1+ (1.000000,0.000000) [0.000000|13407807929942597099574024998205846127479365820592393377723561443721764030073546976801874298166903427690031858186486050853753882811946569946433649006084096.000000] "" ICAS1_Gateway

BO_ 2549874872 ISOx_EMotor_02_Req: 8 ICAS1_Gateway
 SG_ ISO_EMotor_02_Req_Data  : 0|64@1+ (1.000000,0.000000) [0.000000|18446744073709551616.000000] "" LE2

BO_ 2621440184 ISOx_EMotor_02_Req_FD: 64 ICAS1_Gateway
 SG_ ISOx_EMotor_02_Req_FD_Data  : 0|512@1+ (1.000000,0.000000) [0.000000|13407807929942597099574024998205846127479365820592393377723561443721764030073546976801874298166903427690031858186486050853753882811946569946433649006084096.000000] "" LE2

BO_ 2550005944 ISOx_EMotor_02_Resp: 8 LE2
 SG_ ISO_EMotor_02_Resp_Data  : 0|64@1+ (1.000000,0.000000) [0.000000|18446744073709551616.000000] "" ICAS1_Gateway

BO_ 2621571256 ISOx_EMotor_02_Resp_FD: 64 LE2
 SG_ ISOx_EMotor_02_Resp_FD_Data  : 0|512@1+ (1.000000,0.000000) [0.000000|13407807929942597099574024998205846127479365820592393377723561443721764030073546976801874298166903427690031858186486050853753882811946569946433649006084096.000000] "" ICAS1_Gateway

BO_ 2621505536 ISOx_Funkt_Req_All_FD: 64 ICAS1_Gateway
 SG_ ISOx_Funkt_Req_All_FD_Data  : 0|512@1+ (1.000000,0.000000) [0.000000|13407807929942597099574024998205846127479365820592393377723561443721764030073546976801874298166903427690031858186486050853753882811946569946433649006084096.000000] "" Airbag LE1 LE2 Motor_BEV

BO_ 2549874806 ISOx_MO_01_Req: 8 ICAS1_Gateway
 SG_ ISOx_MO_01_Req_Data  : 0|64@1+ (1.000000,0.000000) [0.000000|18446744073709551616.000000] "" Motor_BEV

BO_ 2621440118 ISOx_MO_01_Req_FD: 64 ICAS1_Gateway
 SG_ ISOx_MO_01_Req_FD_Data  : 0|512@1+ (1.000000,0.000000) [0.000000|13407807929942597099574024998205846127479365820592393377723561443721764030073546976801874298166903427690031858186486050853753882811946569946433649006084096.000000] "" Motor_BEV

BO_ 2550005878 ISOx_MO_01_Resp: 8 Motor_BEV
 SG_ ISOx_MO_01_Resp_Data  : 0|64@1+ (1.000000,0.000000) [0.000000|18446744073709551616.000000] "" ICAS1_Gateway

BO_ 2621571190 ISOx_MO_01_Resp_FD: 64 Motor_BEV
 SG_ ISOx_MO_01_Resp_FD_Data  : 0|512@1+ (1.000000,0.000000) [0.000000|13407807929942597099574024998205846127479365820592393377723561443721764030073546976801874298166903427690031858186486050853753882811946569946433649006084096.000000] "" ICAS1_Gateway

BO_ 2527679684 Kamera_ASM_01: 8 ICAS1_Gateway
 SG_ Kamera_ASM_Ereignis  : 0|8@1+ (1.000000,0.000000) [1.000000|254.000000] "" Airbag
 SG_ Kamera_ASM_Zeitstempel  : 8|8@1+ (0.080000,0.000000) [0.000000|20.320000] "Unit_Secon" Airbag
 SG_ Kamera_ASM_Data_1  : 16|8@1+ (1.000000,0.000000) [0.000000|255.000000] "" Airbag
 SG_ Kamera_ASM_Data_2  : 24|8@1+ (1.000000,0.000000) [0.000000|255.000000] "" Airbag
 SG_ Kamera_ASM_Data_3  : 32|8@1+ (1.000000,0.000000) [0.000000|255.000000] "" Airbag
 SG_ Kamera_ASM_Data_4  : 40|8@1+ (1.000000,0.000000) [0.000000|255.000000] "" Airbag
 SG_ Kamera_ASM_Data_5  : 48|8@1+ (1.000000,0.000000) [0.000000|255.000000] "" Airbag
 SG_ Kamera_ASM_Data_6  : 56|8@1+ (1.000000,0.000000) [0.000000|255.000000] "" Airbag

BO_ 960 Klemmen_Status_01: 4 ICAS1_Gateway
 SG_ Klemmen_Status_01_CRC  : 0|8@1+ (1.000000,0.000000) [0.000000|255.000000] "" Motor_BEV
 SG_ Klemmen_Status_01_BZ  : 8|4@1+ (1.000000,0.000000) [0.000000|15.000000] "" Motor_BEV
 SG_ RSt_Fahrerhinweise  : 12|4@1+ (1.000000,0.000000) [0.000000|15.000000] "" Vector__XXX
 SG_ ZAS_Kl_S  : 16|1@1+ (1.000000,0.000000) [0.000000|1.000000] "" Vector__XXX
 SG_ ZAS_Kl_15  : 17|1@1+ (1.000000,0.000000) [0.000000|1.000000] "" Airbag LE1 LE2 Motor_BEV Schaltbetaetigung
 SG_ ZAS_Kl_X  : 18|1@1+ (1.000000,0.000000) [0.000000|1.000000] "" Vector__XXX
 SG_ ZAS_Kl_50_Startanforderung  : 19|1@1+ (1.000000,0.000000) [0.000000|1.000000] "" Motor_BEV
 SG_ BCM_Remotestart_Betrieb  : 20|1@1+ (1.000000,0.000000) [0.000000|1.000000] "" Vector__XXX
 SG_ ZAS_Kl_Infotainment  : 21|1@1+ (1.000000,0.000000) [0.000000|1.000000] "" Vector__XXX
 SG_ BCM_Remotestart_KL15_Anf  : 22|1@1+ (1.000000,0.000000) [0.000000|1.000000] "" Vector__XXX
 SG_ BCM_Remotestart_MO_Start  : 23|1@1+ (1.000000,0.000000) [0.000000|1.000000] "" Vector__XXX
 SG_ KST_Warn_P1_ZST_def  : 24|1@1+ (1.000000,0.000000) [0.000000|1.000000] "" Vector__XXX
 SG_ KST_Warn_P2_ZST_def  : 25|1@1+ (1.000000,0.000000) [0.000000|1.000000] "" Vector__XXX
 SG_ KST_Fahrerhinweis_1  : 26|1@1+ (1.000000,0.000000) [0.000000|1.000000] "" Vector__XXX
 SG_ KST_Fahrerhinweis_2  : 27|1@1+ (1.000000,0.000000) [0.000000|1.000000] "" Vector__XXX
 SG_ BCM_Ausparken_Betrieb  : 28|1@1+ (1.000000,0.000000) [0.000000|1.000000] "" Vector__XXX
 SG_ KST_Fahrerhinweis_4  : 29|1@1+ (1.000000,0.000000) [0.000000|1.000000] "" Vector__XXX
 SG_ KST_Fahrerhinweis_5  : 30|1@1+ (1.000000,0.000000) [0.000000|1.000000] "" Vector__XXX
 SG_ KST_Fahrerhinweis_6  : 31|1@1+ (1.000000,0.000000) [0.000000|1.000000] "" Vector__XXX

BO_ 2463978753 Klemmen_Status_02: 8 ICAS1_Gateway
 SG_ KST_WFS_Fahrfreigabe_Anforderung  : 12|2@1+ (1.000000,0.000000) [0.000000|3.000000] "" LE1 LE2
 SG_ KST_Sonderzustand_Status  : 14|2@1+ (1.000000,0.000000) [0.000000|3.000000] "" LE1 LE2
 SG_ KST_Sonderzustand_Anforderung  : 16|5@1+ (1.000000,0.000000) [0.000000|31.000000] "" LE1 LE2

BO_ 1420 Klemmen_Steuerung_01: 8 ICAS1_Gateway
 SG_ Klemmen_Steuerung_01_CRC  : 0|8@1+ (1.000000,0.000000) [0.000000|255.000000] "" Vector__XXX
 SG_ Klemmen_Steuerung_01_BZ  : 8|4@1+ (1.000000,0.000000) [0.000000|15.000000] "" Vector__XXX
 SG_ KST_Anf_Klemme_15  : 12|1@1+ (1.000000,0.000000) [0.000000|1.000000] "" Vector__XXX
 SG_ KST_Anf_Klemme_50  : 13|1@1+ (1.000000,0.000000) [0.000000|1.000000] "" Motor_BEV
 SG_ KST_Anf_Klemme_S  : 14|1@1+ (1.000000,0.000000) [0.000000|1.000000] "" Vector__XXX
 SG_ KST_Txt_Werkstatt  : 15|1@1+ (1.000000,0.000000) [0.000000|1.000000] "" Vector__XXX
 SG_ KST_Txt_P_Gang  : 16|1@1+ (1.000000,0.000000) [0.000000|1.000000] "" Vector__XXX
 SG_ KST_Txt_Panikabschaltung  : 17|1@1+ (1.000000,0.000000) [0.000000|1.000000] "" Vector__XXX
 SG_ KST_Anf_Klemmenfreigabe_ELV  : 18|1@1+ (1.000000,0.000000) [0.000000|1.000000] "" Vector__XXX
 SG_ KST_Txt_Komfortabschaltung  : 19|1@1+ (1.000000,0.000000) [0.000000|1.000000] "" Vector__XXX
 SG_ KST_ZAT_betaetigt  : 20|1@1+ (1.000000,0.000000) [0.000000|1.000000] "" Vector__XXX
 SG_ KST_Unterdr_Zuendungsmeldung  : 21|1@1+ (1.000000,0.000000) [0.000000|1.000000] "" Vector__XXX
 SG_ KST_aut_Abschaltung_Zuendung  : 22|1@1+ (1.000000,0.000000) [0.000000|1.000000] "" Vector__XXX
 SG_ KST_Anf_Klemmenfreigabe_WFS  : 23|1@1+ (1.000000,0.000000) [0.000000|1.000000] "" Vector__XXX
 SG_ KST_Anf_ZV_Verriegelung  : 24|1@1+ (1.000000,0.000000) [0.000000|1.000000] "" Vector__XXX
 SG_ Relais_VoKo_angesteuert  : 25|1@1+ (1.000000,0.000000) [0.000000|1.000000] "" Vector__XXX
 SG_ RSt_Anforderung_HMS  : 26|3@1+ (1.000000,0.000000) [0.000000|7.000000] "" Vector__XXX
 SG_ KST_Zuendungswarnung  : 29|2@1+ (1.000000,0.000000) [0.000000|3.000000] "" Vector__XXX
 SG_ KST_Fahrer_Info_Text  : 31|3@1+ (1.000000,0.000000) [0.000000|7.000000] "" Vector__XXX

BO_ 949 Klima_11: 8 ICAS1_Gateway
 SG_ KL_Drehz_Anh  : 0|1@1+ (1.000000,0.000000) [0.000000|1.000000] "" Vector__XXX
 SG_ KL_Vorwarn_Komp_ein  : 1|1@1+ (1.000000,0.000000) [0.000000|1.000000] "" Vector__XXX
 SG_ KL_AC_Schalter  : 2|1@1+ (1.000000,0.000000) [0.000000|1.000000] "" Vector__XXX
 SG_ KL_Komp_Moment_alt  : 3|1@1+ (1.000000,0.000000) [0.000000|1.000000] "" Vector__XXX
 SG_ KL_Vorwarn_Zuheizer_ein  : 6|1@1+ (1.000000,0.000000) [0.000000|1.000000] "" Vector__XXX
 SG_ KL_Zustand  : 7|1@1+ (1.000000,0.000000) [0.000000|1.000000] "" Vector__XXX
 SG_ KL_Kompressorkupplung_linear  : 8|8@1+ (20.000000,0.000000) [0.000000|4000.000000] "Unit_MilliAmper" Vector__XXX
 SG_ KL_Charisma_FahrPr  : 16|4@1+ (1.000000,0.000000) [0.000000|15.000000] "" Vector__XXX
 SG_ KL_Charisma_Status  : 20|2@1+ (1.000000,0.000000) [0.000000|3.000000] "" Vector__XXX
 SG_ KL_nachtr_Stopp_Anf  : 22|1@1+ (1.000000,0.000000) [0.000000|1.000000] "" Vector__XXX
 SG_ KL_T_Charge  : 23|1@1+ (1.000000,0.000000) [0.000000|1.000000] "" Vector__XXX
 SG_ KL_Last_Kompr  : 24|8@1+ (0.250000,0.000000) [0.000000|63.500000] "Unit_NewtoMeter" Vector__XXX
 SG_ KL_Spannungs_Anf  : 32|2@1+ (1.000000,0.000000) [0.000000|3.000000] "" Vector__XXX
 SG_ KL_Thermomanagement  : 34|2@1+ (1.000000,0.000000) [0.000000|3.000000] "" Motor_BEV
 SG_ KL_StartStopp_Info  : 36|2@1+ (1.000000,0.000000) [0.000000|3.000000] "" Vector__XXX
 SG_ KL_Freilauf_Info  : 38|2@1+ (1.000000,0.000000) [0.000000|3.000000] "" Vector__XXX
 SG_ KL_Anf_KL  : 40|8@1+ (0.400000,0.000000) [0.000000|101.600000] "Unit_PerCent" Motor_BEV
 SG_ KL_el_Zuheizer_Stufe  : 48|3@1+ (1.000000,0.000000) [0.000000|7.000000] "" Vector__XXX
 SG_ KL_Ausstattung_Klima  : 51|3@1+ (1.000000,0.000000) [0.000000|7.000000] "" Vector__XXX
 SG_ KL_Variante_Standheizung  : 54|2@1+ (1.000000,0.000000) [0.000000|3.000000] "" Vector__XXX
 SG_ KL_Anf_KV  : 57|7@1+ (1.000000,0.000000) [0.000000|100.000000] "Unit_PerCent" Motor_BEV

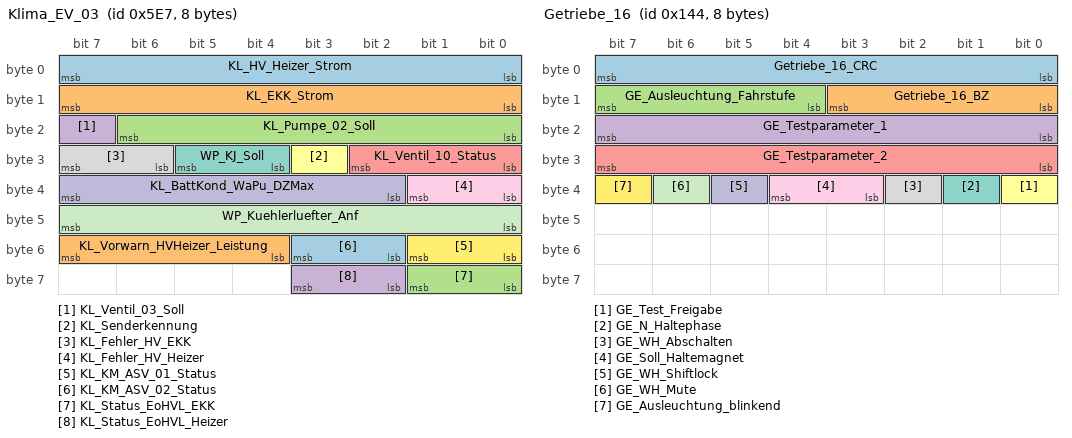
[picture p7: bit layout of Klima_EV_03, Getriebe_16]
BO_ 1511 Klima_EV_03: 8 ICAS1_Gateway
 SG_ KL_HV_Heizer_Strom  : 0|8@1+ (0.250000,0.000000) [0.000000|63.500000] "Unit_Amper" Motor_BEV
 SG_ KL_EKK_Strom  : 8|8@1+ (0.250000,0.000000) [0.000000|63.500000] "Unit_Amper" Motor_BEV
 SG_ KL_Pumpe_02_Soll  : 16|7@1+ (1.000000,0.000000) [0.000000|100.000000] "Unit_PerCent" Motor_BEV
 SG_ KL_Ventil_03_Soll  : 23|1@1+ (1.000000,0.000000) [0.000000|1.000000] "" Vector__XXX
 SG_ KL_Ventil_10_Status  : 24|3@1+ (1.000000,0.000000) [0.000000|7.000000] "" Vector__XXX
 SG_ KL_Senderkennung  : 27|1@1+ (1.000000,0.000000) [0.000000|1.000000] "" Vector__XXX
 SG_ WP_KJ_Soll  : 28|2@1+ (1.000000,0.000000) [0.000000|3.000000] "" Vector__XXX
 SG_ KL_Fehler_HV_EKK  : 30|2@1+ (1.000000,0.000000) [0.000000|3.000000] "" Vector__XXX
 SG_ KL_Fehler_HV_Heizer  : 32|2@1+ (1.000000,0.000000) [0.000000|3.000000] "" Vector__XXX
 SG_ KL_BattKond_WaPu_DZMax  : 34|6@1+ (2.000000,0.000000) [0.000000|100.000000] "Unit_PerCent" Vector__XXX
 SG_ WP_Kuehlerluefter_Anf  : 40|8@1+ (0.400000,0.000000) [0.000000|101.600000] "Unit_PerCent" Vector__XXX
 SG_ KL_KM_ASV_01_Status  : 48|2@1+ (1.000000,0.000000) [0.000000|3.000000] "" Vector__XXX
 SG_ KL_KM_ASV_02_Status  : 50|2@1+ (1.000000,0.000000) [0.000000|3.000000] "" Vector__XXX
 SG_ KL_Vorwarn_HVHeizer_Leistung  : 52|4@1+ (1.000000,0.000000) [0.000000|15.000000] "" Vector__XXX
 SG_ KL_Status_EoHVL_EKK  : 56|2@1+ (1.000000,0.000000) [0.000000|3.000000] "" Motor_BEV
 SG_ KL_Status_EoHVL_Heizer  : 58|2@1+ (1.000000,0.000000) [0.000000|3.000000] "" Motor_BEV

BU_:  Airbag BAP_Tester ICAS1_Gateway ICAS1_KommunikationsServer LE1 LE2 Motor_BEV Schaltbetaetigung

BO_ 324 Getriebe_16: 8 Motor_BEV
 SG_ Getriebe_16_CRC  : 0|8@1+ (1.000000,0.000000) [0.000000|255.000000] "" ICAS1_Gateway Schaltbetaetigung
 SG_ Getriebe_16_BZ  : 8|4@1+ (1.000000,0.000000) [0.000000|15.000000] "" ICAS1_Gateway Schaltbetaetigung
 SG_ GE_Ausleuchtung_Fahrstufe  : 12|4@1+ (1.000000,0.000000) [0.000000|15.000000] "" ICAS1_Gateway Schaltbetaetigung
 SG_ GE_Testparameter_1  : 16|8@1+ (1.000000,0.000000) [0.000000|255.000000] "" ICAS1_Gateway Schaltbetaetigung
 SG_ GE_Testparameter_2  : 24|8@1+ (1.000000,0.000000) [0.000000|255.000000] "" ICAS1_Gateway Schaltbetaetigung
 SG_ GE_Test_Freigabe  : 32|1@1+ (1.000000,0.000000) [0.000000|1.000000] "" ICAS1_Gateway Schaltbetaetigung
 SG_ GE_N_Haltephase  : 33|1@1+ (1.000000,0.000000) [0.000000|1.000000] "" ICAS1_Gateway Schaltbetaetigung
 SG_ GE_WH_Abschalten  : 34|1@1+ (1.000000,0.000000) [0.000000|1.000000] "" ICAS1_Gateway Schaltbetaetigung
 SG_ GE_Soll_Haltemagnet  : 35|2@1+ (1.000000,0.000000) [0.000000|3.000000] "" ICAS1_Gateway Schaltbetaetigung
 SG_ GE_WH_Shiftlock  : 37|1@1+ (1.000000,0.000000) [0.000000|1.000000] "" ICAS1_Gateway Schaltbetaetigung
 SG_ GE_WH_Mute  : 38|1@1+ (1.000000,0.000000) [0.000000|1.000000] "" ICAS1_Gateway Schaltbetaetigung
 SG_ GE_Ausleuchtung_blinkend  : 39|1@1+ (1.000000,0.000000) [0.000000|1.000000] "" ICAS1_Gateway Schaltbetaetigung

BO_ 299 GRA_ACC_01: 8 ICAS1_Gateway
 SG_ GRA_ACC_01_CRC  : 0|8@1+ (1.000000,0.000000) [0.000000|255.000000] "" Motor_BEV
 SG_ GRA_ACC_01_BZ  : 8|4@1+ (1.000000,0.000000) [0.000000|15.000000] "" Motor_BEV
 SG_ GRA_Hauptschalter  : 12|1@1+ (1.000000,0.000000) [0.000000|1.000000] "" Motor_BEV
 SG_ GRA_Abbrechen  : 13|1@1+ (1.000000,0.000000) [0.000000|1.000000] "" Motor_BEV
 SG_ GRA_Typ_Hauptschalter  : 14|1@1+ (1.000000,0.000000) [0.000000|1.000000] "" Motor_BEV
 SG_ GRA_Limiter  : 15|1@1+ (1.000000,0.000000) [0.000000|1.000000] "" Motor_BEV
 SG_ GRA_Tip_Setzen  : 16|1@1+ (1.000000,0.000000) [0.000000|1.000000] "" Motor_BEV
 SG_ GRA_Tip_Hoch  : 17|1@1+ (1.000000,0.000000) [0.000000|1.000000] "" Motor_BEV
 SG_ GRA_Tip_Runter  : 18|1@1+ (1.000000,0.000000) [0.000000|1.000000] "" Motor_BEV
 SG_ GRA_Tip_Wiederaufnahme  : 19|1@1+ (1.000000,0.000000) [0.000000|1.000000] "" Motor_BEV
 SG_ GRA_Verstellung_Zeitluecke  : 20|2@1+ (1.000000,0.000000) [0.000000|3.000000] "" Vector__XXX
 SG_ GRA_Codierung  : 22|2@1+ (1.000000,0.000000) [0.000000|3.000000] "" Motor_BEV
 SG_ GRA_Fehler  : 24|1@1+ (1.000000,0.000000) [0.000000|1.000000] "" Motor_BEV
 SG_ GRA_LIM_Taste_verfuegbar  : 25|1@1+ (1.000000,0.000000) [0.000000|1.000000] "" Motor_BEV
 SG_ GRA_Tip_Stufe_2  : 26|1@1+ (1.000000,0.000000) [0.000000|1.000000] "" Motor_BEV
 SG_ GRA_Typ_Bedienteil  : 27|3@1+ (1.000000,0.000000) [0.000000|7.000000] "" Motor_BEV
 SG_ GRA_TravelAssist  : 30|1@1+ (1.000000,0.000000) [0.000000|1.000000] "" Vector__XXX
 SG_ GRA_reserveByte4  : 31|1@1+ (1.000000,0.000000) [0.000000|1.000000] "" Vector__XXX
 SG_ GRA_reserveByte5  : 32|8@1+ (1.000000,0.000000) [0.000000|255.000000] "" Vector__XXX
 SG_ GRA_reserveByte6  : 40|8@1+ (1.000000,0.000000) [0.000000|255.000000] "" Vector__XXX
 SG_ GRA_reserveByte7  : 48|8@1+ (1.000000,0.000000) [0.000000|255.000000] "" Vector__XXX
 SG_ GRA_reserveByte8  : 56|8@1+ (1.000000,0.000000) [0.000000|255.000000] "" Vector__XXX

BO_ 1452 HVEM_02: 8 ICAS1_Gateway
 SG_ HVEM_IstStrom_HVVerbraucher  : 0|12@1+ (0.100000,-204.700000) [-204.700000|204.600000] "Unit_Amper" Vector__XXX
 SG_ HVEM_Energie_Klima_Vorgabe_HighR  : 12|3@1+ (10.000000,0.000000) [0.000000|50.000000] "Unit_WattHour" Vector__XXX
 SG_ HVEM_IstLeistungNA  : 15|9@1+ (50.000000,0.000000) [0.000000|25450.000000] "Unit_Watt" Motor_BEV
 SG_ HVEM_Leistung_Klima_Vorgabe  : 24|8@1+ (50.000000,0.000000) [0.000000|12650.000000] "Unit_Watt" Vector__XXX
 SG_ HVEM_Nutzbare_Energie  : 32|11@1+ (50.000000,0.000000) [0.000000|102200.000000] "Unit_WattHour" Vector__XXX
 SG_ HVEM_Energie_Klima_Vorgabe  : 43|8@1+ (50.000000,0.000000) [0.000000|12650.000000] "Unit_WattHour" Vector__XXX
 SG_ HVEM_HVK_Aktivitaet  : 51|2@1+ (1.000000,0.000000) [0.000000|3.000000] "" Motor_BEV
 SG_ HVEM_Pruefpuls_Anf  : 53|2@1+ (1.000000,0.000000) [0.000000|3.000000] "" Motor_BEV
 SG_ HVEM_HV_Anf  : 62|1@1+ (1.000000,0.000000) [0.000000|1.000000] "" Motor_BEV
 SG_ HVEM_MO_MaxLeistungIgnoriert  : 63|1@1+ (1.000000,0.000000) [0.000000|1.000000] "" Vector__XXX

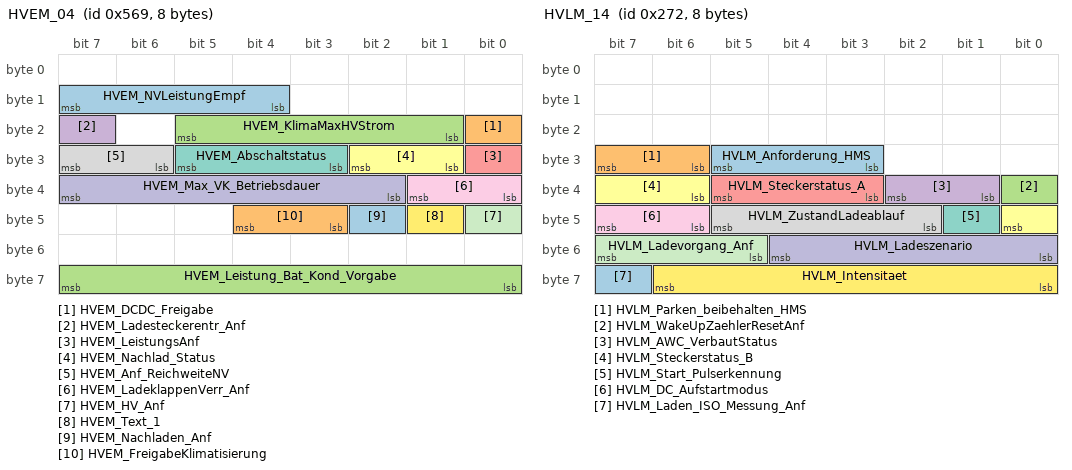
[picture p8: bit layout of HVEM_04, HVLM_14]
BO_ 1385 HVEM_04: 8 ICAS1_Gateway
 SG_ HVEM_NVLeistungEmpf  : 12|4@1+ (100.000000,0.000000) [0.000000|1500.000000] "Unit_Watt" Vector__XXX
 SG_ HVEM_DCDC_Freigabe  : 16|1@1+ (1.000000,0.000000) [0.000000|1.000000] "" Motor_BEV
 SG_ HVEM_KlimaMaxHVStrom  : 17|5@1+ (1.000000,0.000000) [0.000000|31.000000] "Unit_Amper" Vector__XXX
 SG_ HVEM_Ladesteckerentr_Anf  : 23|1@1+ (1.000000,0.000000) [0.000000|1.000000] "" Vector__XXX
 SG_ HVEM_LeistungsAnf  : 24|1@1+ (1.000000,0.000000) [0.000000|1.000000] "" Vector__XXX
 SG_ HVEM_Nachlad_Status  : 25|2@1+ (1.000000,0.000000) [0.000000|3.000000] "" Vector__XXX
 SG_ HVEM_Abschaltstatus  : 27|3@1+ (1.000000,0.000000) [0.000000|7.000000] "" Vector__XXX
 SG_ HVEM_Anf_ReichweiteNV  : 30|2@1+ (1.000000,0.000000) [0.000000|3.000000] "" Vector__XXX
 SG_ HVEM_LadeklappenVerr_Anf  : 32|2@1+ (1.000000,0.000000) [0.000000|3.000000] "" Vector__XXX
 SG_ HVEM_Max_VK_Betriebsdauer  : 34|6@1+ (1.000000,0.000000) [0.000000|60.000000] "Unit_Minut" Vector__XXX
 SG_ HVEM_HV_Anf  : 40|1@1+ (1.000000,0.000000) [0.000000|1.000000] "" Vector__XXX
 SG_ HVEM_Text_1  : 41|1@1+ (1.000000,0.000000) [0.000000|1.000000] "" Vector__XXX
 SG_ HVEM_Nachladen_Anf  : 42|1@1+ (1.000000,0.000000) [0.000000|1.000000] "" Vector__XXX
 SG_ HVEM_FreigabeKlimatisierung  : 43|2@1+ (1.000000,0.000000) [0.000000|3.000000] "" Vector__XXX
 SG_ HVEM_Leistung_Bat_Kond_Vorgabe  : 56|8@1+ (50.000000,0.000000) [0.000000|12650.000000] "Unit_Watt" Vector__XXX

BO_ 1283 HVK_01: 8 Motor_BEV
 SG_ HVK_01_CRC  : 0|8@1+ (1.000000,0.000000) [0.000000|255.000000] "" ICAS1_Gateway LE1 LE2
 SG_ HVK_01_BZ  : 8|4@1+ (1.000000,0.000000) [0.000000|15.000000] "" ICAS1_Gateway LE1 LE2
 SG_ HVK_Istmodus_Anf  : 12|1@1+ (1.000000,0.000000) [0.000000|1.000000] "" ICAS1_Gateway
 SG_ HVK_TN1_Sollmodus  : 13|2@1+ (1.000000,0.000000) [0.000000|3.000000] "" ICAS1_Gateway
 SG_ HVK_Vorladung_aktiv  : 15|1@1+ (1.000000,0.000000) [0.000000|1.000000] "" ICAS1_Gateway
 SG_ HVK_BMS_Sollmodus  : 24|3@1+ (1.000000,0.000000) [0.000000|7.000000] "" ICAS1_Gateway
 SG_ HVK_DCDC_Sollmodus  : 27|3@1+ (1.000000,0.000000) [0.000000|7.000000] "" ICAS1_Gateway
 SG_ HVK_EKK_Sollmodus  : 30|3@1+ (1.000000,0.000000) [0.000000|7.000000] "" ICAS1_Gateway
 SG_ HVK_HVPTC_Sollmodus  : 33|3@1+ (1.000000,0.000000) [0.000000|7.000000] "" ICAS1_Gateway
 SG_ HVK_HVLM_Sollmodus  : 36|3@1+ (1.000000,0.000000) [0.000000|7.000000] "" ICAS1_Gateway
 SG_ HVK_HV_Netz_Warnungen  : 39|2@1+ (1.000000,0.000000) [0.000000|3.000000] "" ICAS1_Gateway ICAS1_KommunikationsServer
 SG_ HV_Bordnetz_aktiv  : 41|1@1+ (1.000000,0.000000) [0.000000|1.000000] "" ICAS1_Gateway LE1 LE2
 SG_ HV_Bordnetz_Fehler  : 42|1@1+ (1.000000,0.000000) [0.000000|1.000000] "" ICAS1_Gateway
 SG_ HVK_Gesamtst_Spgfreiheit  : 43|2@1+ (1.000000,0.000000) [0.000000|3.000000] "" ICAS1_Gateway ICAS1_KommunikationsServer
 SG_ HVK_AktiveEntladung_Anf  : 45|1@1+ (1.000000,0.000000) [0.000000|1.000000] "" ICAS1_Gateway LE1 LE2
 SG_ HVK_HVEM_Freigabe  : 46|2@1+ (1.000000,0.000000) [0.000000|3.000000] "" ICAS1_Gateway
 SG_ HVK_Notentladung_Anf  : 48|2@1+ (1.000000,0.000000) [0.000000|3.000000] "" ICAS1_Gateway LE1 LE2
 SG_ HVK_Iso_Messung_Start  : 50|3@1+ (1.000000,0.000000) [0.000000|7.000000] "" ICAS1_Gateway
 SG_ HVK_Ladebereit  : 53|3@1+ (1.000000,0.000000) [0.000000|7.000000] "" ICAS1_Gateway
 SG_ HVK_PPulsFreigabe  : 56|2@1+ (1.000000,0.000000) [0.000000|3.000000] "" ICAS1_Gateway

BO_ 2463978813 HVL_01: 8 ICAS1_Gateway
 SG_ HVL_01_CRC  : 0|8@1+ (1.000000,0.000000) [0.000000|255.000000] "" Motor_BEV
 SG_ HVL_01_BZ  : 8|4@1+ (1.000000,0.000000) [0.000000|15.000000] "" Motor_BEV
 SG_ HVL_Steckerstatus  : 12|2@1+ (1.000000,0.000000) [0.000000|3.000000] "" Motor_BEV
 SG_ HVL_LadeAnforderung  : 24|3@1+ (1.000000,0.000000) [0.000000|7.000000] "" Motor_BEV

BO_ 626 HVLM_14: 8 ICAS1_Gateway
 SG_ HVLM_Anforderung_HMS  : 27|3@1+ (1.000000,0.000000) [0.000000|7.000000] "" Vector__XXX
 SG_ HVLM_Parken_beibehalten_HMS  : 30|2@1+ (1.000000,0.000000) [0.000000|3.000000] "" Vector__XXX
 SG_ HVLM_WakeUpZaehlerResetAnf  : 32|1@1+ (1.000000,0.000000) [0.000000|1.000000] "" Vector__XXX
 SG_ HVLM_AWC_VerbautStatus  : 33|2@1+ (1.000000,0.000000) [0.000000|3.000000] "" Motor_BEV
 SG_ HVLM_Steckerstatus_A  : 35|3@1+ (1.000000,0.000000) [0.000000|7.000000] "" Motor_BEV
 SG_ HVLM_Steckerstatus_B  : 38|3@1+ (1.000000,0.000000) [0.000000|7.000000] "" Vector__XXX
 SG_ HVLM_Start_Pulserkennung  : 41|1@1+ (1.000000,0.000000) [0.000000|1.000000] "" Vector__XXX
 SG_ HVLM_ZustandLadeablauf  : 42|4@1+ (1.000000,0.000000) [0.000000|15.000000] "" Motor_BEV
 SG_ HVLM_DC_Aufstartmodus  : 46|2@1+ (1.000000,0.000000) [0.000000|3.000000] "" Motor_BEV
 SG_ HVLM_Ladeszenario  : 48|5@1+ (1.000000,0.000000) [0.000000|31.000000] "" Vector__XXX
 SG_ HVLM_Ladevorgang_Anf  : 53|3@1+ (1.000000,0.000000) [0.000000|7.000000] "" Motor_BEV
 SG_ HVLM_Intensitaet  : 56|7@1+ (1.000000,0.000000) [0.000000|100.000000] "Unit_PerCent" Vector__XXX
 SG_ HVLM_Laden_ISO_Messung_Anf  : 63|1@1+ (1.000000,0.000000) [0.000000|1.000000] "" Motor_BEV

BO_ 268 IMMO_CORD_01: 8 Motor_BEV
 SG_ ImoCord_Auth_Aufforderung_WFS  : 63|1@1+ (1.000000,0.000000) [0.000000|1.000000] "" LE1 LE2

BO_ 23 IMMO_MSG3_Antwort: 8 ICAS1_Gateway
 SG_ WFS_IMMO_MSG3_CRC  : 0|32@1+ (1.000000,0.000000) [0.000000|4294967295.000000] "" LE2
 SG_ WFS_IMMO_MSG3_Status  : 56|8@1+ (1.000000,0.000000) [0.000000|255.000000] "" LE2

BO_ 25 IMMO_MSG4_Antwort: 8 ICAS1_Gateway
 SG_ WFS_IMMO_MSG4_CRC  : 0|32@1+ (1.000000,0.000000) [0.000000|4294967295.000000] "" LE1
 SG_ WFS_IMMO_MSG4_Status  : 56|8@1+ (1.000000,0.000000) [0.000000|255.000000] "" LE1

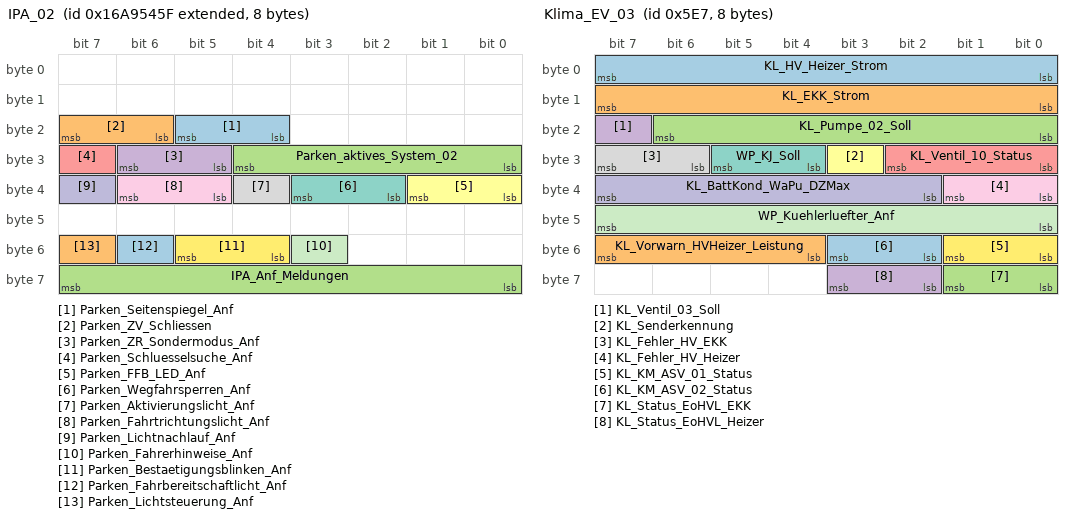
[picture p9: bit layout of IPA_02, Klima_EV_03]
BO_ 2527679583 IPA_02: 8 ICAS1_Gateway
 SG_ Parken_Seitenspiegel_Anf  : 20|2@1+ (1.000000,0.000000) [0.000000|3.000000] "" Vector__XXX
 SG_ Parken_ZV_Schliessen  : 22|2@1+ (1.000000,0.000000) [0.000000|3.000000] "" Vector__XXX
 SG_ Parken_aktives_System_02  : 24|5@1+ (1.000000,0.000000) [0.000000|31.000000] "" Vector__XXX
 SG_ Parken_ZR_Sondermodus_Anf  : 29|2@1+ (1.000000,0.000000) [0.000000|3.000000] "" Vector__XXX
 SG_ Parken_Schluesselsuche_Anf  : 31|1@1+ (1.000000,0.000000) [0.000000|1.000000] "" Vector__XXX
 SG_ Parken_FFB_LED_Anf  : 32|2@1+ (1.000000,0.000000) [0.000000|3.000000] "" Vector__XXX
 SG_ Parken_Wegfahrsperren_Anf  : 34|2@1+ (1.000000,0.000000) [0.000000|3.000000] "" LE1 LE2
 SG_ Parken_Aktivierungslicht_Anf  : 36|1@1+ (1.000000,0.000000) [0.000000|1.000000] "" Vector__XXX
 SG_ Parken_Fahrtrichtungslicht_Anf  : 37|2@1+ (1.000000,0.000000) [0.000000|3.000000] "" Vector__XXX
 SG_ Parken_Lichtnachlauf_Anf  : 39|1@1+ (1.000000,0.000000) [0.000000|1.000000] "" Vector__XXX
 SG_ Parken_Fahrerhinweise_Anf  : 51|1@1+ (1.000000,0.000000) [0.000000|1.000000] "" Vector__XXX
 SG_ Parken_Bestaetigungsblinken_Anf  : 52|2@1+ (1.000000,0.000000) [0.000000|3.000000] "" Vector__XXX
 SG_ Parken_Fahrbereitschaftlicht_Anf  : 54|1@1+ (1.000000,0.000000) [0.000000|1.000000] "" Vector__XXX
 SG_ Parken_Lichtsteuerung_Anf  : 55|1@1+ (1.000000,0.000000) [0.000000|1.000000] "" Vector__XXX
 SG_ IPA_Anf_Meldungen  : 56|8@1+ (1.000000,0.000000) [0.000000|255.000000] "" Vector__XXX

BO_ 1813 ISO_Airbag_01_Req: 8 ICAS1_Gateway
 SG_ ISO_Airbag_01_Req_Data  : 0|64@1+ (1.000000,0.000000) [0.000000|18446744073709551616.000000] "" Airbag

BO_ 1919 ISO_Airbag_01_Resp: 8 Airbag
 SG_ ISO_Airbag_01_Resp_Data  : 0|64@1+ (1.000000,0.000000) [0.000000|18446744073709551616.000000] "" ICAS1_Gateway

BO_ 1792 ISO_Funktionaler_Req_All: 8 ICAS1_Gateway
 SG_ ISO_ALL_01_Req_Data  : 0|64@1+ (1.000000,0.000000) [0.000000|18446744073709551616.000000] "" Airbag LE1 LE2 Motor_BEV

BO_ 2621440021 ISOx_Airbag_01_Req_FD: 64 ICAS1_Gateway
 SG_ ISOx_Airbag_01_Req_FD_Data  : 0|512@1+ (1.000000,0.000000) [0.000000|13407807929942597099574024998205846127479365820592393377723561443721764030073546976801874298166903427690031858186486050853753882811946569946433649006084096.000000] "" Airbag

BO_ 2621571093 ISOx_Airbag_01_Resp_FD: 64 Airbag
 SG_ ISOx_Airbag_01_Resp_FD_Data  : 0|512@1+ (1.000000,0.000000) [0.000000|13407807929942597099574024998205846127479365820592393377723561443721764030073546976801874298166903427690031858186486050853753882811946569946433649006084096.000000] "" ICAS1_Gateway

BO_ 2549874812 ISOx_EMotor_01_Req: 8 ICAS1_Gateway
 SG_ ISO_EMotor_01_Req_Data  : 0|64@1+ (1.000000,0.000000) [0.000000|18446744073709551616.000000] "" LE1

BO_ 2621440124 ISOx_EMotor_01_Req_FD: 64 ICAS1_Gateway
 SG_ ISOx_EMotor_01_Req_FD_Data  : 0|512@1+ (1.000000,0.000000) [0.000000|13407807929942597099574024998205846127479365820592393377723561443721764030073546976801874298166903427690031858186486050853753882811946569946433649006084096.000000] "" LE1

BO_ 2550005884 ISOx_EMotor_01_Resp: 8 LE1
 SG_ ISO_EMotor_01_Resp_Data  : 0|64@1+ (1.000000,0.000000) [0.000000|18446744073709551616.000000] "" ICAS1_Gateway

BO_ 2621571196 ISOx_EMotor_01_Resp_FD: 64 LE1
 SG_ ISOx_EMotor_01_Resp_FD_Data  : 0|512@1+ (1.000000,0.000000) [0.000000|13407807929942597099574024998205846127479365820592393377723561443721764030073546976801874298166903427690031858186486050853753882811946569946433649006084096.000000] "" ICAS1_Gateway

BO_ 2549874872 ISOx_EMotor_02_Req: 8 ICAS1_Gateway
 SG_ ISO_EMotor_02_Req_Data  : 0|64@1+ (1.000000,0.000000) [0.000000|18446744073709551616.000000] "" LE2

BO_ 2621440184 ISOx_EMotor_02_Req_FD: 64 ICAS1_Gateway
 SG_ ISOx_EMotor_02_Req_FD_Data  : 0|512@1+ (1.000000,0.000000) [0.000000|13407807929942597099574024998205846127479365820592393377723561443721764030073546976801874298166903427690031858186486050853753882811946569946433649006084096.000000] "" LE2

BO_ 2550005944 ISOx_EMotor_02_Resp: 8 LE2
 SG_ ISO_EMotor_02_Resp_Data  : 0|64@1+ (1.000000,0.000000) [0.000000|18446744073709551616.000000] "" ICAS1_Gateway

BO_ 2621571256 ISOx_EMotor_02_Resp_FD: 64 LE2
 SG_ ISOx_EMotor_02_Resp_FD_Data  : 0|512@1+ (1.000000,0.000000) [0.000000|13407807929942597099574024998205846127479365820592393377723561443721764030073546976801874298166903427690031858186486050853753882811946569946433649006084096.000000] "" ICAS1_Gateway

BO_ 2621505536 ISOx_Funkt_Req_All_FD: 64 ICAS1_Gateway
 SG_ ISOx_Funkt_Req_All_FD_Data  : 0|512@1+ (1.000000,0.000000) [0.000000|13407807929942597099574024998205846127479365820592393377723561443721764030073546976801874298166903427690031858186486050853753882811946569946433649006084096.000000] "" Airbag LE1 LE2 Motor_BEV

BO_ 2549874806 ISOx_MO_01_Req: 8 ICAS1_Gateway
 SG_ ISOx_MO_01_Req_Data  : 0|64@1+ (1.000000,0.000000) [0.000000|18446744073709551616.000000] "" Motor_BEV

BO_ 2621440118 ISOx_MO_01_Req_FD: 64 ICAS1_Gateway
 SG_ ISOx_MO_01_Req_FD_Data  : 0|512@1+ (1.000000,0.000000) [0.000000|13407807929942597099574024998205846127479365820592393377723561443721764030073546976801874298166903427690031858186486050853753882811946569946433649006084096.000000] "" Motor_BEV

BO_ 2550005878 ISOx_MO_01_Resp: 8 Motor_BEV
 SG_ ISOx_MO_01_Resp_Data  : 0|64@1+ (1.000000,0.000000) [0.000000|18446744073709551616.000000] "" ICAS1_Gateway

BO_ 2621571190 ISOx_MO_01_Resp_FD: 64 Motor_BEV
 SG_ ISOx_MO_01_Resp_FD_Data  : 0|512@1+ (1.000000,0.000000) [0.000000|13407807929942597099574024998205846127479365820592393377723561443721764030073546976801874298166903427690031858186486050853753882811946569946433649006084096.000000] "" ICAS1_Gateway

BO_ 2527679684 Kamera_ASM_01: 8 ICAS1_Gateway
 SG_ Kamera_ASM_Ereignis  : 0|8@1+ (1.000000,0.000000) [1.000000|254.000000] "" Airbag
 SG_ Kamera_ASM_Zeitstempel  : 8|8@1+ (0.080000,0.000000) [0.000000|20.320000] "Unit_Secon" Airbag
 SG_ Kamera_ASM_Data_1  : 16|8@1+ (1.000000,0.000000) [0.000000|255.000000] "" Airbag
 SG_ Kamera_ASM_Data_2  : 24|8@1+ (1.000000,0.000000) [0.000000|255.000000] "" Airbag
 SG_ Kamera_ASM_Data_3  : 32|8@1+ (1.000000,0.000000) [0.000000|255.000000] "" Airbag
 SG_ Kamera_ASM_Data_4  : 40|8@1+ (1.000000,0.000000) [0.000000|255.000000] "" Airbag
 SG_ Kamera_ASM_Data_5  : 48|8@1+ (1.000000,0.000000) [0.000000|255.000000] "" Airbag
 SG_ Kamera_ASM_Data_6  : 56|8@1+ (1.000000,0.000000) [0.000000|255.000000] "" Airbag

BO_ 960 Klemmen_Status_01: 4 ICAS1_Gateway
 SG_ Klemmen_Status_01_CRC  : 0|8@1+ (1.000000,0.000000) [0.000000|255.000000] "" Motor_BEV
 SG_ Klemmen_Status_01_BZ  : 8|4@1+ (1.000000,0.000000) [0.000000|15.000000] "" Motor_BEV
 SG_ RSt_Fahrerhinweise  : 12|4@1+ (1.000000,0.000000) [0.000000|15.000000] "" Vector__XXX
 SG_ ZAS_Kl_S  : 16|1@1+ (1.000000,0.000000) [0.000000|1.000000] "" Vector__XXX
 SG_ ZAS_Kl_15  : 17|1@1+ (1.000000,0.000000) [0.000000|1.000000] "" Airbag LE1 LE2 Motor_BEV Schaltbetaetigung
 SG_ ZAS_Kl_X  : 18|1@1+ (1.000000,0.000000) [0.000000|1.000000] "" Vector__XXX
 SG_ ZAS_Kl_50_Startanforderung  : 19|1@1+ (1.000000,0.000000) [0.000000|1.000000] "" Motor_BEV
 SG_ BCM_Remotestart_Betrieb  : 20|1@1+ (1.000000,0.000000) [0.000000|1.000000] "" Vector__XXX
 SG_ ZAS_Kl_Infotainment  : 21|1@1+ (1.000000,0.000000) [0.000000|1.000000] "" Vector__XXX
 SG_ BCM_Remotestart_KL15_Anf  : 22|1@1+ (1.000000,0.000000) [0.000000|1.000000] "" Vector__XXX
 SG_ BCM_Remotestart_MO_Start  : 23|1@1+ (1.000000,0.000000) [0.000000|1.000000] "" Vector__XXX
 SG_ KST_Warn_P1_ZST_def  : 24|1@1+ (1.000000,0.000000) [0.000000|1.000000] "" Vector__XXX
 SG_ KST_Warn_P2_ZST_def  : 25|1@1+ (1.000000,0.000000) [0.000000|1.000000] "" Vector__XXX
 SG_ KST_Fahrerhinweis_1  : 26|1@1+ (1.000000,0.000000) [0.000000|1.000000] "" Vector__XXX
 SG_ KST_Fahrerhinweis_2  : 27|1@1+ (1.000000,0.000000) [0.000000|1.000000] "" Vector__XXX
 SG_ BCM_Ausparken_Betrieb  : 28|1@1+ (1.000000,0.000000) [0.000000|1.000000] "" Vector__XXX
 SG_ KST_Fahrerhinweis_4  : 29|1@1+ (1.000000,0.000000) [0.000000|1.000000] "" Vector__XXX
 SG_ KST_Fahrerhinweis_5  : 30|1@1+ (1.000000,0.000000) [0.000000|1.000000] "" Vector__XXX
 SG_ KST_Fahrerhinweis_6  : 31|1@1+ (1.000000,0.000000) [0.000000|1.000000] "" Vector__XXX

BO_ 2463978753 Klemmen_Status_02: 8 ICAS1_Gateway
 SG_ KST_WFS_Fahrfreigabe_Anforderung  : 12|2@1+ (1.000000,0.000000) [0.000000|3.000000] "" LE1 LE2
 SG_ KST_Sonderzustand_Status  : 14|2@1+ (1.000000,0.000000) [0.000000|3.000000] "" LE1 LE2
 SG_ KST_Sonderzustand_Anforderung  : 16|5@1+ (1.000000,0.000000) [0.000000|31.000000] "" LE1 LE2

BO_ 1420 Klemmen_Steuerung_01: 8 ICAS1_Gateway
 SG_ Klemmen_Steuerung_01_CRC  : 0|8@1+ (1.000000,0.000000) [0.000000|255.000000] "" Vector__XXX
 SG_ Klemmen_Steuerung_01_BZ  : 8|4@1+ (1.000000,0.000000) [0.000000|15.000000] "" Vector__XXX
 SG_ KST_Anf_Klemme_15  : 12|1@1+ (1.000000,0.000000) [0.000000|1.000000] "" Vector__XXX
 SG_ KST_Anf_Klemme_50  : 13|1@1+ (1.000000,0.000000) [0.000000|1.000000] "" Motor_BEV
 SG_ KST_Anf_Klemme_S  : 14|1@1+ (1.000000,0.000000) [0.000000|1.000000] "" Vector__XXX
 SG_ KST_Txt_Werkstatt  : 15|1@1+ (1.000000,0.000000) [0.000000|1.000000] "" Vector__XXX
 SG_ KST_Txt_P_Gang  : 16|1@1+ (1.000000,0.000000) [0.000000|1.000000] "" Vector__XXX
 SG_ KST_Txt_Panikabschaltung  : 17|1@1+ (1.000000,0.000000) [0.000000|1.000000] "" Vector__XXX
 SG_ KST_Anf_Klemmenfreigabe_ELV  : 18|1@1+ (1.000000,0.000000) [0.000000|1.000000] "" Vector__XXX
 SG_ KST_Txt_Komfortabschaltung  : 19|1@1+ (1.000000,0.000000) [0.000000|1.000000] "" Vector__XXX
 SG_ KST_ZAT_betaetigt  : 20|1@1+ (1.000000,0.000000) [0.000000|1.000000] "" Vector__XXX
 SG_ KST_Unterdr_Zuendungsmeldung  : 21|1@1+ (1.000000,0.000000) [0.000000|1.000000] "" Vector__XXX
 SG_ KST_aut_Abschaltung_Zuendung  : 22|1@1+ (1.000000,0.000000) [0.000000|1.000000] "" Vector__XXX
 SG_ KST_Anf_Klemmenfreigabe_WFS  : 23|1@1+ (1.000000,0.000000) [0.000000|1.000000] "" Vector__XXX
 SG_ KST_Anf_ZV_Verriegelung  : 24|1@1+ (1.000000,0.000000) [0.000000|1.000000] "" Vector__XXX
 SG_ Relais_VoKo_angesteuert  : 25|1@1+ (1.000000,0.000000) [0.000000|1.000000] "" Vector__XXX
 SG_ RSt_Anforderung_HMS  : 26|3@1+ (1.000000,0.000000) [0.000000|7.000000] "" Vector__XXX
 SG_ KST_Zuendungswarnung  : 29|2@1+ (1.000000,0.000000) [0.000000|3.000000] "" Vector__XXX
 SG_ KST_Fahrer_Info_Text  : 31|3@1+ (1.000000,0.000000) [0.000000|7.000000] "" Vector__XXX

BO_ 949 Klima_11: 8 ICAS1_Gateway
 SG_ KL_Drehz_Anh  : 0|1@1+ (1.000000,0.000000) [0.000000|1.000000] "" Vector__XXX
 SG_ KL_Vorwarn_Komp_ein  : 1|1@1+ (1.000000,0.000000) [0.000000|1.000000] "" Vector__XXX
 SG_ KL_AC_Schalter  : 2|1@1+ (1.000000,0.000000) [0.000000|1.000000] "" Vector__XXX
 SG_ KL_Komp_Moment_alt  : 3|1@1+ (1.000000,0.000000) [0.000000|1.000000] "" Vector__XXX
 SG_ KL_Vorwarn_Zuheizer_ein  : 6|1@1+ (1.000000,0.000000) [0.000000|1.000000] "" Vector__XXX
 SG_ KL_Zustand  : 7|1@1+ (1.000000,0.000000) [0.000000|1.000000] "" Vector__XXX
 SG_ KL_Kompressorkupplung_linear  : 8|8@1+ (20.000000,0.000000) [0.000000|4000.000000] "Unit_MilliAmper" Vector__XXX
 SG_ KL_Charisma_FahrPr  : 16|4@1+ (1.000000,0.000000) [0.000000|15.000000] "" Vector__XXX
 SG_ KL_Charisma_Status  : 20|2@1+ (1.000000,0.000000) [0.000000|3.000000] "" Vector__XXX
 SG_ KL_nachtr_Stopp_Anf  : 22|1@1+ (1.000000,0.000000) [0.000000|1.000000] "" Vector__XXX
 SG_ KL_T_Charge  : 23|1@1+ (1.000000,0.000000) [0.000000|1.000000] "" Vector__XXX
 SG_ KL_Last_Kompr  : 24|8@1+ (0.250000,0.000000) [0.000000|63.500000] "Unit_NewtoMeter" Vector__XXX
 SG_ KL_Spannungs_Anf  : 32|2@1+ (1.000000,0.000000) [0.000000|3.000000] "" Vector__XXX
 SG_ KL_Thermomanagement  : 34|2@1+ (1.000000,0.000000) [0.000000|3.000000] "" Motor_BEV
 SG_ KL_StartStopp_Info  : 36|2@1+ (1.000000,0.000000) [0.000000|3.000000] "" Vector__XXX
 SG_ KL_Freilauf_Info  : 38|2@1+ (1.000000,0.000000) [0.000000|3.000000] "" Vector__XXX
 SG_ KL_Anf_KL  : 40|8@1+ (0.400000,0.000000) [0.000000|101.600000] "Unit_PerCent" Motor_BEV
 SG_ KL_el_Zuheizer_Stufe  : 48|3@1+ (1.000000,0.000000) [0.000000|7.000000] "" Vector__XXX
 SG_ KL_Ausstattung_Klima  : 51|3@1+ (1.000000,0.000000) [0.000000|7.000000] "" Vector__XXX
 SG_ KL_Variante_Standheizung  : 54|2@1+ (1.000000,0.000000) [0.000000|3.000000] "" Vector__XXX
 SG_ KL_Anf_KV  : 57|7@1+ (1.000000,0.000000) [0.000000|100.000000] "Unit_PerCent" Motor_BEV

BO_ 1511 Klima_EV_03: 8 ICAS1_Gateway
 SG_ KL_HV_Heizer_Strom  : 0|8@1+ (0.250000,0.000000) [0.000000|63.500000] "Unit_Amper" Motor_BEV
 SG_ KL_EKK_Strom  : 8|8@1+ (0.250000,0.000000) [0.000000|63.500000] "Unit_Amper" Motor_BEV
 SG_ KL_Pumpe_02_Soll  : 16|7@1+ (1.000000,0.000000) [0.000000|100.000000] "Unit_PerCent" Motor_BEV
 SG_ KL_Ventil_03_Soll  : 23|1@1+ (1.000000,0.000000) [0.000000|1.000000] "" Vector__XXX
 SG_ KL_Ventil_10_Status  : 24|3@1+ (1.000000,0.000000) [0.000000|7.000000] "" Vector__XXX
 SG_ KL_Senderkennung  : 27|1@1+ (1.000000,0.000000) [0.000000|1.000000] "" Vector__XXX
 SG_ WP_KJ_Soll  : 28|2@1+ (1.000000,0.000000) [0.000000|3.000000] "" Vector__XXX
 SG_ KL_Fehler_HV_EKK  : 30|2@1+ (1.000000,0.000000) [0.000000|3.000000] "" Vector__XXX
 SG_ KL_Fehler_HV_Heizer  : 32|2@1+ (1.000000,0.000000) [0.000000|3.000000] "" Vector__XXX
 SG_ KL_BattKond_WaPu_DZMax  : 34|6@1+ (2.000000,0.000000) [0.000000|100.000000] "Unit_PerCent" Vector__XXX
 SG_ WP_Kuehlerluefter_Anf  : 40|8@1+ (0.400000,0.000000) [0.000000|101.600000] "Unit_PerCent" Vector__XXX
 SG_ KL_KM_ASV_01_Status  : 48|2@1+ (1.000000,0.000000) [0.000000|3.000000] "" Vector__XXX
 SG_ KL_KM_ASV_02_Status  : 50|2@1+ (1.000000,0.000000) [0.000000|3.000000] "" Vector__XXX
 SG_ KL_Vorwarn_HVHeizer_Leistung  : 52|4@1+ (1.000000,0.000000) [0.000000|15.000000] "" Vector__XXX
 SG_ KL_Status_EoHVL_EKK  : 56|2@1+ (1.000000,0.000000) [0.000000|3.000000] "" Motor_BEV
 SG_ KL_Status_EoHVL_Heizer  : 58|2@1+ (1.000000,0.000000) [0.000000|3.000000] "" Motor_BEV

BU_:  Airbag BAP_Tester ICAS1_Gateway ICAS1_KommunikationsServer LE1 LE2 Motor_BEV Schaltbetaetigung

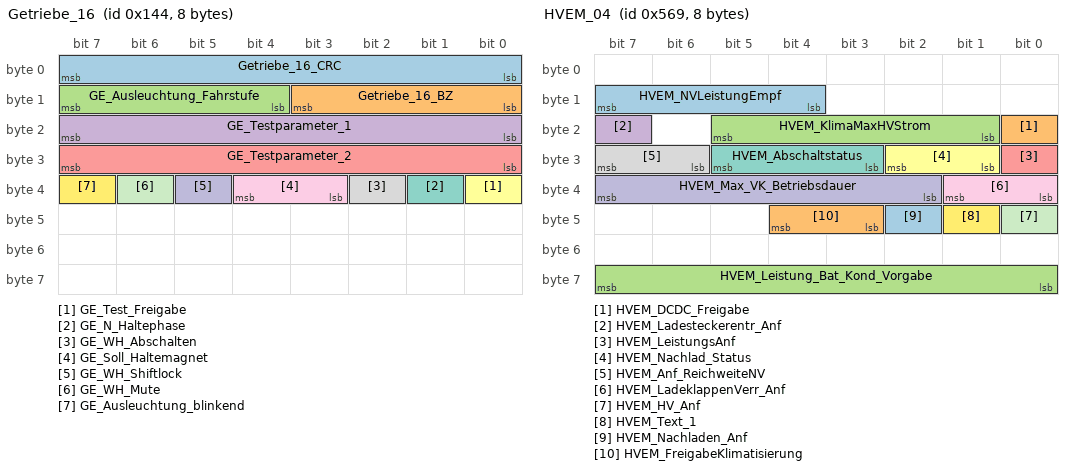
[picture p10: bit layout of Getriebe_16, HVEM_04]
BO_ 324 Getriebe_16: 8 Motor_BEV
 SG_ Getriebe_16_CRC  : 0|8@1+ (1.000000,0.000000) [0.000000|255.000000] "" ICAS1_Gateway Schaltbetaetigung
 SG_ Getriebe_16_BZ  : 8|4@1+ (1.000000,0.000000) [0.000000|15.000000] "" ICAS1_Gateway Schaltbetaetigung
 SG_ GE_Ausleuchtung_Fahrstufe  : 12|4@1+ (1.000000,0.000000) [0.000000|15.000000] "" ICAS1_Gateway Schaltbetaetigung
 SG_ GE_Testparameter_1  : 16|8@1+ (1.000000,0.000000) [0.000000|255.000000] "" ICAS1_Gateway Schaltbetaetigung
 SG_ GE_Testparameter_2  : 24|8@1+ (1.000000,0.000000) [0.000000|255.000000] "" ICAS1_Gateway Schaltbetaetigung
 SG_ GE_Test_Freigabe  : 32|1@1+ (1.000000,0.000000) [0.000000|1.000000] "" ICAS1_Gateway Schaltbetaetigung
 SG_ GE_N_Haltephase  : 33|1@1+ (1.000000,0.000000) [0.000000|1.000000] "" ICAS1_Gateway Schaltbetaetigung
 SG_ GE_WH_Abschalten  : 34|1@1+ (1.000000,0.000000) [0.000000|1.000000] "" ICAS1_Gateway Schaltbetaetigung
 SG_ GE_Soll_Haltemagnet  : 35|2@1+ (1.000000,0.000000) [0.000000|3.000000] "" ICAS1_Gateway Schaltbetaetigung
 SG_ GE_WH_Shiftlock  : 37|1@1+ (1.000000,0.000000) [0.000000|1.000000] "" ICAS1_Gateway Schaltbetaetigung
 SG_ GE_WH_Mute  : 38|1@1+ (1.000000,0.000000) [0.000000|1.000000] "" ICAS1_Gateway Schaltbetaetigung
 SG_ GE_Ausleuchtung_blinkend  : 39|1@1+ (1.000000,0.000000) [0.000000|1.000000] "" ICAS1_Gateway Schaltbetaetigung

BO_ 299 GRA_ACC_01: 8 ICAS1_Gateway
 SG_ GRA_ACC_01_CRC  : 0|8@1+ (1.000000,0.000000) [0.000000|255.000000] "" Motor_BEV
 SG_ GRA_ACC_01_BZ  : 8|4@1+ (1.000000,0.000000) [0.000000|15.000000] "" Motor_BEV
 SG_ GRA_Hauptschalter  : 12|1@1+ (1.000000,0.000000) [0.000000|1.000000] "" Motor_BEV
 SG_ GRA_Abbrechen  : 13|1@1+ (1.000000,0.000000) [0.000000|1.000000] "" Motor_BEV
 SG_ GRA_Typ_Hauptschalter  : 14|1@1+ (1.000000,0.000000) [0.000000|1.000000] "" Motor_BEV
 SG_ GRA_Limiter  : 15|1@1+ (1.000000,0.000000) [0.000000|1.000000] "" Motor_BEV
 SG_ GRA_Tip_Setzen  : 16|1@1+ (1.000000,0.000000) [0.000000|1.000000] "" Motor_BEV
 SG_ GRA_Tip_Hoch  : 17|1@1+ (1.000000,0.000000) [0.000000|1.000000] "" Motor_BEV
 SG_ GRA_Tip_Runter  : 18|1@1+ (1.000000,0.000000) [0.000000|1.000000] "" Motor_BEV
 SG_ GRA_Tip_Wiederaufnahme  : 19|1@1+ (1.000000,0.000000) [0.000000|1.000000] "" Motor_BEV
 SG_ GRA_Verstellung_Zeitluecke  : 20|2@1+ (1.000000,0.000000) [0.000000|3.000000] "" Vector__XXX
 SG_ GRA_Codierung  : 22|2@1+ (1.000000,0.000000) [0.000000|3.000000] "" Motor_BEV
 SG_ GRA_Fehler  : 24|1@1+ (1.000000,0.000000) [0.000000|1.000000] "" Motor_BEV
 SG_ GRA_LIM_Taste_verfuegbar  : 25|1@1+ (1.000000,0.000000) [0.000000|1.000000] "" Motor_BEV
 SG_ GRA_Tip_Stufe_2  : 26|1@1+ (1.000000,0.000000) [0.000000|1.000000] "" Motor_BEV
 SG_ GRA_Typ_Bedienteil  : 27|3@1+ (1.000000,0.000000) [0.000000|7.000000] "" Motor_BEV
 SG_ GRA_TravelAssist  : 30|1@1+ (1.000000,0.000000) [0.000000|1.000000] "" Vector__XXX
 SG_ GRA_reserveByte4  : 31|1@1+ (1.000000,0.000000) [0.000000|1.000000] "" Vector__XXX
 SG_ GRA_reserveByte5  : 32|8@1+ (1.000000,0.000000) [0.000000|255.000000] "" Vector__XXX
 SG_ GRA_reserveByte6  : 40|8@1+ (1.000000,0.000000) [0.000000|255.000000] "" Vector__XXX
 SG_ GRA_reserveByte7  : 48|8@1+ (1.000000,0.000000) [0.000000|255.000000] "" Vector__XXX
 SG_ GRA_reserveByte8  : 56|8@1+ (1.000000,0.000000) [0.000000|255.000000] "" Vector__XXX

BO_ 1452 HVEM_02: 8 ICAS1_Gateway
 SG_ HVEM_IstStrom_HVVerbraucher  : 0|12@1+ (0.100000,-204.700000) [-204.700000|204.600000] "Unit_Amper" Vector__XXX
 SG_ HVEM_Energie_Klima_Vorgabe_HighR  : 12|3@1+ (10.000000,0.000000) [0.000000|50.000000] "Unit_WattHour" Vector__XXX
 SG_ HVEM_IstLeistungNA  : 15|9@1+ (50.000000,0.000000) [0.000000|25450.000000] "Unit_Watt" Motor_BEV
 SG_ HVEM_Leistung_Klima_Vorgabe  : 24|8@1+ (50.000000,0.000000) [0.000000|12650.000000] "Unit_Watt" Vector__XXX
 SG_ HVEM_Nutzbare_Energie  : 32|11@1+ (50.000000,0.000000) [0.000000|102200.000000] "Unit_WattHour" Vector__XXX
 SG_ HVEM_Energie_Klima_Vorgabe  : 43|8@1+ (50.000000,0.000000) [0.000000|12650.000000] "Unit_WattHour" Vector__XXX
 SG_ HVEM_HVK_Aktivitaet  : 51|2@1+ (1.000000,0.000000) [0.000000|3.000000] "" Motor_BEV
 SG_ HVEM_Pruefpuls_Anf  : 53|2@1+ (1.000000,0.000000) [0.000000|3.000000] "" Motor_BEV
 SG_ HVEM_HV_Anf  : 62|1@1+ (1.000000,0.000000) [0.000000|1.000000] "" Motor_BEV
 SG_ HVEM_MO_MaxLeistungIgnoriert  : 63|1@1+ (1.000000,0.000000) [0.000000|1.000000] "" Vector__XXX

BO_ 1385 HVEM_04: 8 ICAS1_Gateway
 SG_ HVEM_NVLeistungEmpf  : 12|4@1+ (100.000000,0.000000) [0.000000|1500.000000] "Unit_Watt" Vector__XXX
 SG_ HVEM_DCDC_Freigabe  : 16|1@1+ (1.000000,0.000000) [0.000000|1.000000] "" Motor_BEV
 SG_ HVEM_KlimaMaxHVStrom  : 17|5@1+ (1.000000,0.000000) [0.000000|31.000000] "Unit_Amper" Vector__XXX
 SG_ HVEM_Ladesteckerentr_Anf  : 23|1@1+ (1.000000,0.000000) [0.000000|1.000000] "" Vector__XXX
 SG_ HVEM_LeistungsAnf  : 24|1@1+ (1.000000,0.000000) [0.000000|1.000000] "" Vector__XXX
 SG_ HVEM_Nachlad_Status  : 25|2@1+ (1.000000,0.000000) [0.000000|3.000000] "" Vector__XXX
 SG_ HVEM_Abschaltstatus  : 27|3@1+ (1.000000,0.000000) [0.000000|7.000000] "" Vector__XXX
 SG_ HVEM_Anf_ReichweiteNV  : 30|2@1+ (1.000000,0.000000) [0.000000|3.000000] "" Vector__XXX
 SG_ HVEM_LadeklappenVerr_Anf  : 32|2@1+ (1.000000,0.000000) [0.000000|3.000000] "" Vector__XXX
 SG_ HVEM_Max_VK_Betriebsdauer  : 34|6@1+ (1.000000,0.000000) [0.000000|60.000000] "Unit_Minut" Vector__XXX
 SG_ HVEM_HV_Anf  : 40|1@1+ (1.000000,0.000000) [0.000000|1.000000] "" Vector__XXX
 SG_ HVEM_Text_1  : 41|1@1+ (1.000000,0.000000) [0.000000|1.000000] "" Vector__XXX
 SG_ HVEM_Nachladen_Anf  : 42|1@1+ (1.000000,0.000000) [0.000000|1.000000] "" Vector__XXX
 SG_ HVEM_FreigabeKlimatisierung  : 43|2@1+ (1.000000,0.000000) [0.000000|3.000000] "" Vector__XXX
 SG_ HVEM_Leistung_Bat_Kond_Vorgabe  : 56|8@1+ (50.000000,0.000000) [0.000000|12650.000000] "Unit_Watt" Vector__XXX

BO_ 1283 HVK_01: 8 Motor_BEV
 SG_ HVK_01_CRC  : 0|8@1+ (1.000000,0.000000) [0.000000|255.000000] "" ICAS1_Gateway LE1 LE2
 SG_ HVK_01_BZ  : 8|4@1+ (1.000000,0.000000) [0.000000|15.000000] "" ICAS1_Gateway LE1 LE2
 SG_ HVK_Istmodus_Anf  : 12|1@1+ (1.000000,0.000000) [0.000000|1.000000] "" ICAS1_Gateway
 SG_ HVK_TN1_Sollmodus  : 13|2@1+ (1.000000,0.000000) [0.000000|3.000000] "" ICAS1_Gateway
 SG_ HVK_Vorladung_aktiv  : 15|1@1+ (1.000000,0.000000) [0.000000|1.000000] "" ICAS1_Gateway
 SG_ HVK_BMS_Sollmodus  : 24|3@1+ (1.000000,0.000000) [0.000000|7.000000] "" ICAS1_Gateway
 SG_ HVK_DCDC_Sollmodus  : 27|3@1+ (1.000000,0.000000) [0.000000|7.000000] "" ICAS1_Gateway
 SG_ HVK_EKK_Sollmodus  : 30|3@1+ (1.000000,0.000000) [0.000000|7.000000] "" ICAS1_Gateway
 SG_ HVK_HVPTC_Sollmodus  : 33|3@1+ (1.000000,0.000000) [0.000000|7.000000] "" ICAS1_Gateway
 SG_ HVK_HVLM_Sollmodus  : 36|3@1+ (1.000000,0.000000) [0.000000|7.000000] "" ICAS1_Gateway
 SG_ HVK_HV_Netz_Warnungen  : 39|2@1+ (1.000000,0.000000) [0.000000|3.000000] "" ICAS1_Gateway ICAS1_KommunikationsServer
 SG_ HV_Bordnetz_aktiv  : 41|1@1+ (1.000000,0.000000) [0.000000|1.000000] "" ICAS1_Gateway LE1 LE2
 SG_ HV_Bordnetz_Fehler  : 42|1@1+ (1.000000,0.000000) [0.000000|1.000000] "" ICAS1_Gateway
 SG_ HVK_Gesamtst_Spgfreiheit  : 43|2@1+ (1.000000,0.000000) [0.000000|3.000000] "" ICAS1_Gateway ICAS1_KommunikationsServer
 SG_ HVK_AktiveEntladung_Anf  : 45|1@1+ (1.000000,0.000000) [0.000000|1.000000] "" ICAS1_Gateway LE1 LE2
 SG_ HVK_HVEM_Freigabe  : 46|2@1+ (1.000000,0.000000) [0.000000|3.000000] "" ICAS1_Gateway
 SG_ HVK_Notentladung_Anf  : 48|2@1+ (1.000000,0.000000) [0.000000|3.000000] "" ICAS1_Gateway LE1 LE2
 SG_ HVK_Iso_Messung_Start  : 50|3@1+ (1.000000,0.000000) [0.000000|7.000000] "" ICAS1_Gateway
 SG_ HVK_Ladebereit  : 53|3@1+ (1.000000,0.000000) [0.000000|7.000000] "" ICAS1_Gateway
 SG_ HVK_PPulsFreigabe  : 56|2@1+ (1.000000,0.000000) [0.000000|3.000000] "" ICAS1_Gateway

BO_ 2463978813 HVL_01: 8 ICAS1_Gateway
 SG_ HVL_01_CRC  : 0|8@1+ (1.000000,0.000000) [0.000000|255.000000] "" Motor_BEV
 SG_ HVL_01_BZ  : 8|4@1+ (1.000000,0.000000) [0.000000|15.000000] "" Motor_BEV
 SG_ HVL_Steckerstatus  : 12|2@1+ (1.000000,0.000000) [0.000000|3.000000] "" Motor_BEV
 SG_ HVL_LadeAnforderung  : 24|3@1+ (1.000000,0.000000) [0.000000|7.000000] "" Motor_BEV

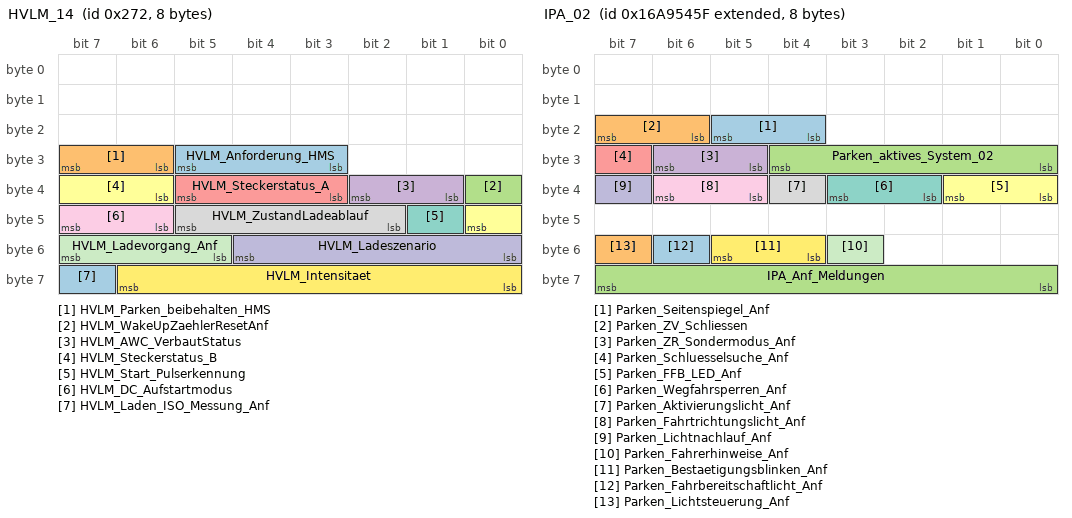
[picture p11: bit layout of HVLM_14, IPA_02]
BO_ 626 HVLM_14: 8 ICAS1_Gateway
 SG_ HVLM_Anforderung_HMS  : 27|3@1+ (1.000000,0.000000) [0.000000|7.000000] "" Vector__XXX
 SG_ HVLM_Parken_beibehalten_HMS  : 30|2@1+ (1.000000,0.000000) [0.000000|3.000000] "" Vector__XXX
 SG_ HVLM_WakeUpZaehlerResetAnf  : 32|1@1+ (1.000000,0.000000) [0.000000|1.000000] "" Vector__XXX
 SG_ HVLM_AWC_VerbautStatus  : 33|2@1+ (1.000000,0.000000) [0.000000|3.000000] "" Motor_BEV
 SG_ HVLM_Steckerstatus_A  : 35|3@1+ (1.000000,0.000000) [0.000000|7.000000] "" Motor_BEV
 SG_ HVLM_Steckerstatus_B  : 38|3@1+ (1.000000,0.000000) [0.000000|7.000000] "" Vector__XXX
 SG_ HVLM_Start_Pulserkennung  : 41|1@1+ (1.000000,0.000000) [0.000000|1.000000] "" Vector__XXX
 SG_ HVLM_ZustandLadeablauf  : 42|4@1+ (1.000000,0.000000) [0.000000|15.000000] "" Motor_BEV
 SG_ HVLM_DC_Aufstartmodus  : 46|2@1+ (1.000000,0.000000) [0.000000|3.000000] "" Motor_BEV
 SG_ HVLM_Ladeszenario  : 48|5@1+ (1.000000,0.000000) [0.000000|31.000000] "" Vector__XXX
 SG_ HVLM_Ladevorgang_Anf  : 53|3@1+ (1.000000,0.000000) [0.000000|7.000000] "" Motor_BEV
 SG_ HVLM_Intensitaet  : 56|7@1+ (1.000000,0.000000) [0.000000|100.000000] "Unit_PerCent" Vector__XXX
 SG_ HVLM_Laden_ISO_Messung_Anf  : 63|1@1+ (1.000000,0.000000) [0.000000|1.000000] "" Motor_BEV

BO_ 268 IMMO_CORD_01: 8 Motor_BEV
 SG_ ImoCord_Auth_Aufforderung_WFS  : 63|1@1+ (1.000000,0.000000) [0.000000|1.000000] "" LE1 LE2

BO_ 23 IMMO_MSG3_Antwort: 8 ICAS1_Gateway
 SG_ WFS_IMMO_MSG3_CRC  : 0|32@1+ (1.000000,0.000000) [0.000000|4294967295.000000] "" LE2
 SG_ WFS_IMMO_MSG3_Status  : 56|8@1+ (1.000000,0.000000) [0.000000|255.000000] "" LE2

BO_ 25 IMMO_MSG4_Antwort: 8 ICAS1_Gateway
 SG_ WFS_IMMO_MSG4_CRC  : 0|32@1+ (1.000000,0.000000) [0.000000|4294967295.000000] "" LE1
 SG_ WFS_IMMO_MSG4_Status  : 56|8@1+ (1.000000,0.000000) [0.000000|255.000000] "" LE1

BO_ 2527679583 IPA_02: 8 ICAS1_Gateway
 SG_ Parken_Seitenspiegel_Anf  : 20|2@1+ (1.000000,0.000000) [0.000000|3.000000] "" Vector__XXX
 SG_ Parken_ZV_Schliessen  : 22|2@1+ (1.000000,0.000000) [0.000000|3.000000] "" Vector__XXX
 SG_ Parken_aktives_System_02  : 24|5@1+ (1.000000,0.000000) [0.000000|31.000000] "" Vector__XXX
 SG_ Parken_ZR_Sondermodus_Anf  : 29|2@1+ (1.000000,0.000000) [0.000000|3.000000] "" Vector__XXX
 SG_ Parken_Schluesselsuche_Anf  : 31|1@1+ (1.000000,0.000000) [0.000000|1.000000] "" Vector__XXX
 SG_ Parken_FFB_LED_Anf  : 32|2@1+ (1.000000,0.000000) [0.000000|3.000000] "" Vector__XXX
 SG_ Parken_Wegfahrsperren_Anf  : 34|2@1+ (1.000000,0.000000) [0.000000|3.000000] "" LE1 LE2
 SG_ Parken_Aktivierungslicht_Anf  : 36|1@1+ (1.000000,0.000000) [0.000000|1.000000] "" Vector__XXX
 SG_ Parken_Fahrtrichtungslicht_Anf  : 37|2@1+ (1.000000,0.000000) [0.000000|3.000000] "" Vector__XXX
 SG_ Parken_Lichtnachlauf_Anf  : 39|1@1+ (1.000000,0.000000) [0.000000|1.000000] "" Vector__XXX
 SG_ Parken_Fahrerhinweise_Anf  : 51|1@1+ (1.000000,0.000000) [0.000000|1.000000] "" Vector__XXX
 SG_ Parken_Bestaetigungsblinken_Anf  : 52|2@1+ (1.000000,0.000000) [0.000000|3.000000] "" Vector__XXX
 SG_ Parken_Fahrbereitschaftlicht_Anf  : 54|1@1+ (1.000000,0.000000) [0.000000|1.000000] "" Vector__XXX
 SG_ Parken_Lichtsteuerung_Anf  : 55|1@1+ (1.000000,0.000000) [0.000000|1.000000] "" Vector__XXX
 SG_ IPA_Anf_Meldungen  : 56|8@1+ (1.000000,0.000000) [0.000000|255.000000] "" Vector__XXX

BO_ 1813 ISO_Airbag_01_Req: 8 ICAS1_Gateway
 SG_ ISO_Airbag_01_Req_Data  : 0|64@1+ (1.000000,0.000000) [0.000000|18446744073709551616.000000] "" Airbag

BO_ 1919 ISO_Airbag_01_Resp: 8 Airbag
 SG_ ISO_Airbag_01_Resp_Data  : 0|64@1+ (1.000000,0.000000) [0.000000|18446744073709551616.000000] "" ICAS1_Gateway

BO_ 1792 ISO_Funktionaler_Req_All: 8 ICAS1_Gateway
 SG_ ISO_ALL_01_Req_Data  : 0|64@1+ (1.000000,0.000000) [0.000000|18446744073709551616.000000] "" Airbag LE1 LE2 Motor_BEV

BO_ 2621440021 ISOx_Airbag_01_Req_FD: 64 ICAS1_Gateway
 SG_ ISOx_Airbag_01_Req_FD_Data  : 0|512@1+ (1.000000,0.000000) [0.000000|13407807929942597099574024998205846127479365820592393377723561443721764030073546976801874298166903427690031858186486050853753882811946569946433649006084096.000000] "" Airbag

BO_ 2621571093 ISOx_Airbag_01_Resp_FD: 64 Airbag
 SG_ ISOx_Airbag_01_Resp_FD_Data  : 0|512@1+ (1.000000,0.000000) [0.000000|13407807929942597099574024998205846127479365820592393377723561443721764030073546976801874298166903427690031858186486050853753882811946569946433649006084096.000000] "" ICAS1_Gateway

BO_ 2549874812 ISOx_EMotor_01_Req: 8 ICAS1_Gateway
 SG_ ISO_EMotor_01_Req_Data  : 0|64@1+ (1.000000,0.000000) [0.000000|18446744073709551616.000000] "" LE1

BO_ 2621440124 ISOx_EMotor_01_Req_FD: 64 ICAS1_Gateway
 SG_ ISOx_EMotor_01_Req_FD_Data  : 0|512@1+ (1.000000,0.000000) [0.000000|13407807929942597099574024998205846127479365820592393377723561443721764030073546976801874298166903427690031858186486050853753882811946569946433649006084096.000000] "" LE1

BO_ 2550005884 ISOx_EMotor_01_Resp: 8 LE1
 SG_ ISO_EMotor_01_Resp_Data  : 0|64@1+ (1.000000,0.000000) [0.000000|18446744073709551616.000000] "" ICAS1_Gateway

BO_ 2621571196 ISOx_EMotor_01_Resp_FD: 64 LE1
 SG_ ISOx_EMotor_01_Resp_FD_Data  : 0|512@1+ (1.000000,0.000000) [0.000000|13407807929942597099574024998205846127479365820592393377723561443721764030073546976801874298166903427690031858186486050853753882811946569946433649006084096.000000] "" ICAS1_Gateway

BO_ 2549874872 ISOx_EMotor_02_Req: 8 ICAS1_Gateway
 SG_ ISO_EMotor_02_Req_Data  : 0|64@1+ (1.000000,0.000000) [0.000000|18446744073709551616.000000] "" LE2

BO_ 2621440184 ISOx_EMotor_02_Req_FD: 64 ICAS1_Gateway
 SG_ ISOx_EMotor_02_Req_FD_Data  : 0|512@1+ (1.000000,0.000000) [0.000000|13407807929942597099574024998205846127479365820592393377723561443721764030073546976801874298166903427690031858186486050853753882811946569946433649006084096.000000] "" LE2

BO_ 2550005944 ISOx_EMotor_02_Resp: 8 LE2
 SG_ ISO_EMotor_02_Resp_Data  : 0|64@1+ (1.000000,0.000000) [0.000000|18446744073709551616.000000] "" ICAS1_Gateway

BO_ 2621571256 ISOx_EMotor_02_Resp_FD: 64 LE2
 SG_ ISOx_EMotor_02_Resp_FD_Data  : 0|512@1+ (1.000000,0.000000) [0.000000|13407807929942597099574024998205846127479365820592393377723561443721764030073546976801874298166903427690031858186486050853753882811946569946433649006084096.000000] "" ICAS1_Gateway

BO_ 2621505536 ISOx_Funkt_Req_All_FD: 64 ICAS1_Gateway
 SG_ ISOx_Funkt_Req_All_FD_Data  : 0|512@1+ (1.000000,0.000000) [0.000000|13407807929942597099574024998205846127479365820592393377723561443721764030073546976801874298166903427690031858186486050853753882811946569946433649006084096.000000] "" Airbag LE1 LE2 Motor_BEV

BO_ 2549874806 ISOx_MO_01_Req: 8 ICAS1_Gateway
 SG_ ISOx_MO_01_Req_Data  : 0|64@1+ (1.000000,0.000000) [0.000000|18446744073709551616.000000] "" Motor_BEV

BO_ 2621440118 ISOx_MO_01_Req_FD: 64 ICAS1_Gateway
 SG_ ISOx_MO_01_Req_FD_Data  : 0|512@1+ (1.000000,0.000000) [0.000000|13407807929942597099574024998205846127479365820592393377723561443721764030073546976801874298166903427690031858186486050853753882811946569946433649006084096.000000] "" Motor_BEV

BO_ 2550005878 ISOx_MO_01_Resp: 8 Motor_BEV
 SG_ ISOx_MO_01_Resp_Data  : 0|64@1+ (1.000000,0.000000) [0.000000|18446744073709551616.000000] "" ICAS1_Gateway

BO_ 2621571190 ISOx_MO_01_Resp_FD: 64 Motor_BEV
 SG_ ISOx_MO_01_Resp_FD_Data  : 0|512@1+ (1.000000,0.000000) [0.000000|13407807929942597099574024998205846127479365820592393377723561443721764030073546976801874298166903427690031858186486050853753882811946569946433649006084096.000000] "" ICAS1_Gateway

BO_ 2527679684 Kamera_ASM_01: 8 ICAS1_Gateway
 SG_ Kamera_ASM_Ereignis  : 0|8@1+ (1.000000,0.000000) [1.000000|254.000000] "" Airbag
 SG_ Kamera_ASM_Zeitstempel  : 8|8@1+ (0.080000,0.000000) [0.000000|20.320000] "Unit_Secon" Airbag
 SG_ Kamera_ASM_Data_1  : 16|8@1+ (1.000000,0.000000) [0.000000|255.000000] "" Airbag
 SG_ Kamera_ASM_Data_2  : 24|8@1+ (1.000000,0.000000) [0.000000|255.000000] "" Airbag
 SG_ Kamera_ASM_Data_3  : 32|8@1+ (1.000000,0.000000) [0.000000|255.000000] "" Airbag
 SG_ Kamera_ASM_Data_4  : 40|8@1+ (1.000000,0.000000) [0.000000|255.000000] "" Airbag
 SG_ Kamera_ASM_Data_5  : 48|8@1+ (1.000000,0.000000) [0.000000|255.000000] "" Airbag
 SG_ Kamera_ASM_Data_6  : 56|8@1+ (1.000000,0.000000) [0.000000|255.000000] "" Airbag

BO_ 960 Klemmen_Status_01: 4 ICAS1_Gateway
 SG_ Klemmen_Status_01_CRC  : 0|8@1+ (1.000000,0.000000) [0.000000|255.000000] "" Motor_BEV
 SG_ Klemmen_Status_01_BZ  : 8|4@1+ (1.000000,0.000000) [0.000000|15.000000] "" Motor_BEV
 SG_ RSt_Fahrerhinweise  : 12|4@1+ (1.000000,0.000000) [0.000000|15.000000] "" Vector__XXX
 SG_ ZAS_Kl_S  : 16|1@1+ (1.000000,0.000000) [0.000000|1.000000] "" Vector__XXX
 SG_ ZAS_Kl_15  : 17|1@1+ (1.000000,0.000000) [0.000000|1.000000] "" Airbag LE1 LE2 Motor_BEV Schaltbetaetigung
 SG_ ZAS_Kl_X  : 18|1@1+ (1.000000,0.000000) [0.000000|1.000000] "" Vector__XXX
 SG_ ZAS_Kl_50_Startanforderung  : 19|1@1+ (1.000000,0.000000) [0.000000|1.000000] "" Motor_BEV
 SG_ BCM_Remotestart_Betrieb  : 20|1@1+ (1.000000,0.000000) [0.000000|1.000000] "" Vector__XXX
 SG_ ZAS_Kl_Infotainment  : 21|1@1+ (1.000000,0.000000) [0.000000|1.000000] "" Vector__XXX
 SG_ BCM_Remotestart_KL15_Anf  : 22|1@1+ (1.000000,0.000000) [0.000000|1.000000] "" Vector__XXX
 SG_ BCM_Remotestart_MO_Start  : 23|1@1+ (1.000000,0.000000) [0.000000|1.000000] "" Vector__XXX
 SG_ KST_Warn_P1_ZST_def  : 24|1@1+ (1.000000,0.000000) [0.000000|1.000000] "" Vector__XXX
 SG_ KST_Warn_P2_ZST_def  : 25|1@1+ (1.000000,0.000000) [0.000000|1.000000] "" Vector__XXX
 SG_ KST_Fahrerhinweis_1  : 26|1@1+ (1.000000,0.000000) [0.000000|1.000000] "" Vector__XXX
 SG_ KST_Fahrerhinweis_2  : 27|1@1+ (1.000000,0.000000) [0.000000|1.000000] "" Vector__XXX
 SG_ BCM_Ausparken_Betrieb  : 28|1@1+ (1.000000,0.000000) [0.000000|1.000000] "" Vector__XXX
 SG_ KST_Fahrerhinweis_4  : 29|1@1+ (1.000000,0.000000) [0.000000|1.000000] "" Vector__XXX
 SG_ KST_Fahrerhinweis_5  : 30|1@1+ (1.000000,0.000000) [0.000000|1.000000] "" Vector__XXX
 SG_ KST_Fahrerhinweis_6  : 31|1@1+ (1.000000,0.000000) [0.000000|1.000000] "" Vector__XXX

BO_ 2463978753 Klemmen_Status_02: 8 ICAS1_Gateway
 SG_ KST_WFS_Fahrfreigabe_Anforderung  : 12|2@1+ (1.000000,0.000000) [0.000000|3.000000] "" LE1 LE2
 SG_ KST_Sonderzustand_Status  : 14|2@1+ (1.000000,0.000000) [0.000000|3.000000] "" LE1 LE2
 SG_ KST_Sonderzustand_Anforderung  : 16|5@1+ (1.000000,0.000000) [0.000000|31.000000] "" LE1 LE2

BO_ 1420 Klemmen_Steuerung_01: 8 ICAS1_Gateway
 SG_ Klemmen_Steuerung_01_CRC  : 0|8@1+ (1.000000,0.000000) [0.000000|255.000000] "" Vector__XXX
 SG_ Klemmen_Steuerung_01_BZ  : 8|4@1+ (1.000000,0.000000) [0.000000|15.000000] "" Vector__XXX
 SG_ KST_Anf_Klemme_15  : 12|1@1+ (1.000000,0.000000) [0.000000|1.000000] "" Vector__XXX
 SG_ KST_Anf_Klemme_50  : 13|1@1+ (1.000000,0.000000) [0.000000|1.000000] "" Motor_BEV
 SG_ KST_Anf_Klemme_S  : 14|1@1+ (1.000000,0.000000) [0.000000|1.000000] "" Vector__XXX
 SG_ KST_Txt_Werkstatt  : 15|1@1+ (1.000000,0.000000) [0.000000|1.000000] "" Vector__XXX
 SG_ KST_Txt_P_Gang  : 16|1@1+ (1.000000,0.000000) [0.000000|1.000000] "" Vector__XXX
 SG_ KST_Txt_Panikabschaltung  : 17|1@1+ (1.000000,0.000000) [0.000000|1.000000] "" Vector__XXX
 SG_ KST_Anf_Klemmenfreigabe_ELV  : 18|1@1+ (1.000000,0.000000) [0.000000|1.000000] "" Vector__XXX
 SG_ KST_Txt_Komfortabschaltung  : 19|1@1+ (1.000000,0.000000) [0.000000|1.000000] "" Vector__XXX
 SG_ KST_ZAT_betaetigt  : 20|1@1+ (1.000000,0.000000) [0.000000|1.000000] "" Vector__XXX
 SG_ KST_Unterdr_Zuendungsmeldung  : 21|1@1+ (1.000000,0.000000) [0.000000|1.000000] "" Vector__XXX
 SG_ KST_aut_Abschaltung_Zuendung  : 22|1@1+ (1.000000,0.000000) [0.000000|1.000000] "" Vector__XXX
 SG_ KST_Anf_Klemmenfreigabe_WFS  : 23|1@1+ (1.000000,0.000000) [0.000000|1.000000] "" Vector__XXX
 SG_ KST_Anf_ZV_Verriegelung  : 24|1@1+ (1.000000,0.000000) [0.000000|1.000000] "" Vector__XXX
 SG_ Relais_VoKo_angesteuert  : 25|1@1+ (1.000000,0.000000) [0.000000|1.000000] "" Vector__XXX
 SG_ RSt_Anforderung_HMS  : 26|3@1+ (1.000000,0.000000) [0.000000|7.000000] "" Vector__XXX
 SG_ KST_Zuendungswarnung  : 29|2@1+ (1.000000,0.000000) [0.000000|3.000000] "" Vector__XXX
 SG_ KST_Fahrer_Info_Text  : 31|3@1+ (1.000000,0.000000) [0.000000|7.000000] "" Vector__XXX

BO_ 949 Klima_11: 8 ICAS1_Gateway
 SG_ KL_Drehz_Anh  : 0|1@1+ (1.000000,0.000000) [0.000000|1.000000] "" Vector__XXX
 SG_ KL_Vorwarn_Komp_ein  : 1|1@1+ (1.000000,0.000000) [0.000000|1.000000] "" Vector__XXX
 SG_ KL_AC_Schalter  : 2|1@1+ (1.000000,0.000000) [0.000000|1.000000] "" Vector__XXX
 SG_ KL_Komp_Moment_alt  : 3|1@1+ (1.000000,0.000000) [0.000000|1.000000] "" Vector__XXX
 SG_ KL_Vorwarn_Zuheizer_ein  : 6|1@1+ (1.000000,0.000000) [0.000000|1.000000] "" Vector__XXX
 SG_ KL_Zustand  : 7|1@1+ (1.000000,0.000000) [0.000000|1.000000] "" Vector__XXX
 SG_ KL_Kompressorkupplung_linear  : 8|8@1+ (20.000000,0.000000) [0.000000|4000.000000] "Unit_MilliAmper" Vector__XXX
 SG_ KL_Charisma_FahrPr  : 16|4@1+ (1.000000,0.000000) [0.000000|15.000000] "" Vector__XXX
 SG_ KL_Charisma_Status  : 20|2@1+ (1.000000,0.000000) [0.000000|3.000000] "" Vector__XXX
 SG_ KL_nachtr_Stopp_Anf  : 22|1@1+ (1.000000,0.000000) [0.000000|1.000000] "" Vector__XXX
 SG_ KL_T_Charge  : 23|1@1+ (1.000000,0.000000) [0.000000|1.000000] "" Vector__XXX
 SG_ KL_Last_Kompr  : 24|8@1+ (0.250000,0.000000) [0.000000|63.500000] "Unit_NewtoMeter" Vector__XXX
 SG_ KL_Spannungs_Anf  : 32|2@1+ (1.000000,0.000000) [0.000000|3.000000] "" Vector__XXX
 SG_ KL_Thermomanagement  : 34|2@1+ (1.000000,0.000000) [0.000000|3.000000] "" Motor_BEV
 SG_ KL_StartStopp_Info  : 36|2@1+ (1.000000,0.000000) [0.000000|3.000000] "" Vector__XXX
 SG_ KL_Freilauf_Info  : 38|2@1+ (1.000000,0.000000) [0.000000|3.000000] "" Vector__XXX
 SG_ KL_Anf_KL  : 40|8@1+ (0.400000,0.000000) [0.000000|101.600000] "Unit_PerCent" Motor_BEV
 SG_ KL_el_Zuheizer_Stufe  : 48|3@1+ (1.000000,0.000000) [0.000000|7.000000] "" Vector__XXX
 SG_ KL_Ausstattung_Klima  : 51|3@1+ (1.000000,0.000000) [0.000000|7.000000] "" Vector__XXX
 SG_ KL_Variante_Standheizung  : 54|2@1+ (1.000000,0.000000) [0.000000|3.000000] "" Vector__XXX
 SG_ KL_Anf_KV  : 57|7@1+ (1.000000,0.000000) [0.000000|100.000000] "Unit_PerCent" Motor_BEV

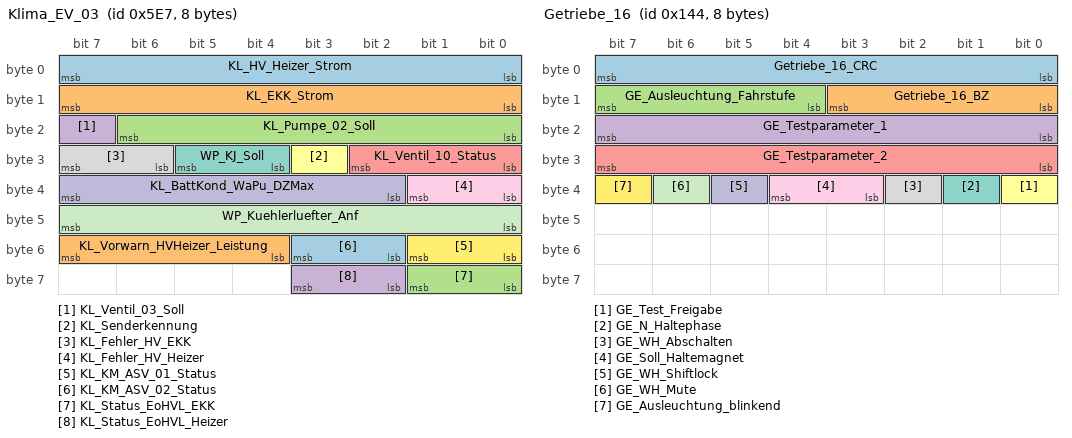
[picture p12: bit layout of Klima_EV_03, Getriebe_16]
BO_ 1511 Klima_EV_03: 8 ICAS1_Gateway
 SG_ KL_HV_Heizer_Strom  : 0|8@1+ (0.250000,0.000000) [0.000000|63.500000] "Unit_Amper" Motor_BEV
 SG_ KL_EKK_Strom  : 8|8@1+ (0.250000,0.000000) [0.000000|63.500000] "Unit_Amper" Motor_BEV
 SG_ KL_Pumpe_02_Soll  : 16|7@1+ (1.000000,0.000000) [0.000000|100.000000] "Unit_PerCent" Motor_BEV
 SG_ KL_Ventil_03_Soll  : 23|1@1+ (1.000000,0.000000) [0.000000|1.000000] "" Vector__XXX
 SG_ KL_Ventil_10_Status  : 24|3@1+ (1.000000,0.000000) [0.000000|7.000000] "" Vector__XXX
 SG_ KL_Senderkennung  : 27|1@1+ (1.000000,0.000000) [0.000000|1.000000] "" Vector__XXX
 SG_ WP_KJ_Soll  : 28|2@1+ (1.000000,0.000000) [0.000000|3.000000] "" Vector__XXX
 SG_ KL_Fehler_HV_EKK  : 30|2@1+ (1.000000,0.000000) [0.000000|3.000000] "" Vector__XXX
 SG_ KL_Fehler_HV_Heizer  : 32|2@1+ (1.000000,0.000000) [0.000000|3.000000] "" Vector__XXX
 SG_ KL_BattKond_WaPu_DZMax  : 34|6@1+ (2.000000,0.000000) [0.000000|100.000000] "Unit_PerCent" Vector__XXX
 SG_ WP_Kuehlerluefter_Anf  : 40|8@1+ (0.400000,0.000000) [0.000000|101.600000] "Unit_PerCent" Vector__XXX
 SG_ KL_KM_ASV_01_Status  : 48|2@1+ (1.000000,0.000000) [0.000000|3.000000] "" Vector__XXX
 SG_ KL_KM_ASV_02_Status  : 50|2@1+ (1.000000,0.000000) [0.000000|3.000000] "" Vector__XXX
 SG_ KL_Vorwarn_HVHeizer_Leistung  : 52|4@1+ (1.000000,0.000000) [0.000000|15.000000] "" Vector__XXX
 SG_ KL_Status_EoHVL_EKK  : 56|2@1+ (1.000000,0.000000) [0.000000|3.000000] "" Motor_BEV
 SG_ KL_Status_EoHVL_Heizer  : 58|2@1+ (1.000000,0.000000) [0.000000|3.000000] "" Motor_BEV

BU_:  Airbag BAP_Tester ICAS1_Gateway ICAS1_KommunikationsServer LE1 LE2 Motor_BEV Schaltbetaetigung

BO_ 324 Getriebe_16: 8 Motor_BEV
 SG_ Getriebe_16_CRC  : 0|8@1+ (1.000000,0.000000) [0.000000|255.000000] "" ICAS1_Gateway Schaltbetaetigung
 SG_ Getriebe_16_BZ  : 8|4@1+ (1.000000,0.000000) [0.000000|15.000000] "" ICAS1_Gateway Schaltbetaetigung
 SG_ GE_Ausleuchtung_Fahrstufe  : 12|4@1+ (1.000000,0.000000) [0.000000|15.000000] "" ICAS1_Gateway Schaltbetaetigung
 SG_ GE_Testparameter_1  : 16|8@1+ (1.000000,0.000000) [0.000000|255.000000] "" ICAS1_Gateway Schaltbetaetigung
 SG_ GE_Testparameter_2  : 24|8@1+ (1.000000,0.000000) [0.000000|255.000000] "" ICAS1_Gateway Schaltbetaetigung
 SG_ GE_Test_Freigabe  : 32|1@1+ (1.000000,0.000000) [0.000000|1.000000] "" ICAS1_Gateway Schaltbetaetigung
 SG_ GE_N_Haltephase  : 33|1@1+ (1.000000,0.000000) [0.000000|1.000000] "" ICAS1_Gateway Schaltbetaetigung
 SG_ GE_WH_Abschalten  : 34|1@1+ (1.000000,0.000000) [0.000000|1.000000] "" ICAS1_Gateway Schaltbetaetigung
 SG_ GE_Soll_Haltemagnet  : 35|2@1+ (1.000000,0.000000) [0.000000|3.000000] "" ICAS1_Gateway Schaltbetaetigung
 SG_ GE_WH_Shiftlock  : 37|1@1+ (1.000000,0.000000) [0.000000|1.000000] "" ICAS1_Gateway Schaltbetaetigung
 SG_ GE_WH_Mute  : 38|1@1+ (1.000000,0.000000) [0.000000|1.000000] "" ICAS1_Gateway Schaltbetaetigung
 SG_ GE_Ausleuchtung_blinkend  : 39|1@1+ (1.000000,0.000000) [0.000000|1.000000] "" ICAS1_Gateway Schaltbetaetigung

BO_ 299 GRA_ACC_01: 8 ICAS1_Gateway
 SG_ GRA_ACC_01_CRC  : 0|8@1+ (1.000000,0.000000) [0.000000|255.000000] "" Motor_BEV
 SG_ GRA_ACC_01_BZ  : 8|4@1+ (1.000000,0.000000) [0.000000|15.000000] "" Motor_BEV
 SG_ GRA_Hauptschalter  : 12|1@1+ (1.000000,0.000000) [0.000000|1.000000] "" Motor_BEV
 SG_ GRA_Abbrechen  : 13|1@1+ (1.000000,0.000000) [0.000000|1.000000] "" Motor_BEV
 SG_ GRA_Typ_Hauptschalter  : 14|1@1+ (1.000000,0.000000) [0.000000|1.000000] "" Motor_BEV
 SG_ GRA_Limiter  : 15|1@1+ (1.000000,0.000000) [0.000000|1.000000] "" Motor_BEV
 SG_ GRA_Tip_Setzen  : 16|1@1+ (1.000000,0.000000) [0.000000|1.000000] "" Motor_BEV
 SG_ GRA_Tip_Hoch  : 17|1@1+ (1.000000,0.000000) [0.000000|1.000000] "" Motor_BEV
 SG_ GRA_Tip_Runter  : 18|1@1+ (1.000000,0.000000) [0.000000|1.000000] "" Motor_BEV
 SG_ GRA_Tip_Wiederaufnahme  : 19|1@1+ (1.000000,0.000000) [0.000000|1.000000] "" Motor_BEV
 SG_ GRA_Verstellung_Zeitluecke  : 20|2@1+ (1.000000,0.000000) [0.000000|3.000000] "" Vector__XXX
 SG_ GRA_Codierung  : 22|2@1+ (1.000000,0.000000) [0.000000|3.000000] "" Motor_BEV
 SG_ GRA_Fehler  : 24|1@1+ (1.000000,0.000000) [0.000000|1.000000] "" Motor_BEV
 SG_ GRA_LIM_Taste_verfuegbar  : 25|1@1+ (1.000000,0.000000) [0.000000|1.000000] "" Motor_BEV
 SG_ GRA_Tip_Stufe_2  : 26|1@1+ (1.000000,0.000000) [0.000000|1.000000] "" Motor_BEV
 SG_ GRA_Typ_Bedienteil  : 27|3@1+ (1.000000,0.000000) [0.000000|7.000000] "" Motor_BEV
 SG_ GRA_TravelAssist  : 30|1@1+ (1.000000,0.000000) [0.000000|1.000000] "" Vector__XXX
 SG_ GRA_reserveByte4  : 31|1@1+ (1.000000,0.000000) [0.000000|1.000000] "" Vector__XXX
 SG_ GRA_reserveByte5  : 32|8@1+ (1.000000,0.000000) [0.000000|255.000000] "" Vector__XXX
 SG_ GRA_reserveByte6  : 40|8@1+ (1.000000,0.000000) [0.000000|255.000000] "" Vector__XXX
 SG_ GRA_reserveByte7  : 48|8@1+ (1.000000,0.000000) [0.000000|255.000000] "" Vector__XXX
 SG_ GRA_reserveByte8  : 56|8@1+ (1.000000,0.000000) [0.000000|255.000000] "" Vector__XXX

BO_ 1452 HVEM_02: 8 ICAS1_Gateway
 SG_ HVEM_IstStrom_HVVerbraucher  : 0|12@1+ (0.100000,-204.700000) [-204.700000|204.600000] "Unit_Amper" Vector__XXX
 SG_ HVEM_Energie_Klima_Vorgabe_HighR  : 12|3@1+ (10.000000,0.000000) [0.000000|50.000000] "Unit_WattHour" Vector__XXX
 SG_ HVEM_IstLeistungNA  : 15|9@1+ (50.000000,0.000000) [0.000000|25450.000000] "Unit_Watt" Motor_BEV
 SG_ HVEM_Leistung_Klima_Vorgabe  : 24|8@1+ (50.000000,0.000000) [0.000000|12650.000000] "Unit_Watt" Vector__XXX
 SG_ HVEM_Nutzbare_Energie  : 32|11@1+ (50.000000,0.000000) [0.000000|102200.000000] "Unit_WattHour" Vector__XXX
 SG_ HVEM_Energie_Klima_Vorgabe  : 43|8@1+ (50.000000,0.000000) [0.000000|12650.000000] "Unit_WattHour" Vector__XXX
 SG_ HVEM_HVK_Aktivitaet  : 51|2@1+ (1.000000,0.000000) [0.000000|3.000000] "" Motor_BEV
 SG_ HVEM_Pruefpuls_Anf  : 53|2@1+ (1.000000,0.000000) [0.000000|3.000000] "" Motor_BEV
 SG_ HVEM_HV_Anf  : 62|1@1+ (1.000000,0.000000) [0.000000|1.000000] "" Motor_BEV
 SG_ HVEM_MO_MaxLeistungIgnoriert  : 63|1@1+ (1.000000,0.000000) [0.000000|1.000000] "" Vector__XXX

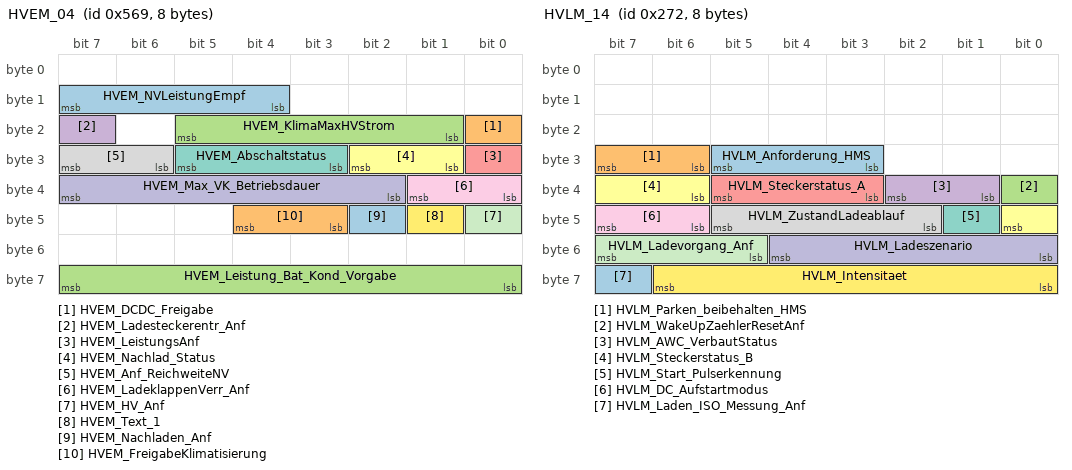
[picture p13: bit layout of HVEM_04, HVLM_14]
BO_ 1385 HVEM_04: 8 ICAS1_Gateway
 SG_ HVEM_NVLeistungEmpf  : 12|4@1+ (100.000000,0.000000) [0.000000|1500.000000] "Unit_Watt" Vector__XXX
 SG_ HVEM_DCDC_Freigabe  : 16|1@1+ (1.000000,0.000000) [0.000000|1.000000] "" Motor_BEV
 SG_ HVEM_KlimaMaxHVStrom  : 17|5@1+ (1.000000,0.000000) [0.000000|31.000000] "Unit_Amper" Vector__XXX
 SG_ HVEM_Ladesteckerentr_Anf  : 23|1@1+ (1.000000,0.000000) [0.000000|1.000000] "" Vector__XXX
 SG_ HVEM_LeistungsAnf  : 24|1@1+ (1.000000,0.000000) [0.000000|1.000000] "" Vector__XXX
 SG_ HVEM_Nachlad_Status  : 25|2@1+ (1.000000,0.000000) [0.000000|3.000000] "" Vector__XXX
 SG_ HVEM_Abschaltstatus  : 27|3@1+ (1.000000,0.000000) [0.000000|7.000000] "" Vector__XXX
 SG_ HVEM_Anf_ReichweiteNV  : 30|2@1+ (1.000000,0.000000) [0.000000|3.000000] "" Vector__XXX
 SG_ HVEM_LadeklappenVerr_Anf  : 32|2@1+ (1.000000,0.000000) [0.000000|3.000000] "" Vector__XXX
 SG_ HVEM_Max_VK_Betriebsdauer  : 34|6@1+ (1.000000,0.000000) [0.000000|60.000000] "Unit_Minut" Vector__XXX
 SG_ HVEM_HV_Anf  : 40|1@1+ (1.000000,0.000000) [0.000000|1.000000] "" Vector__XXX
 SG_ HVEM_Text_1  : 41|1@1+ (1.000000,0.000000) [0.000000|1.000000] "" Vector__XXX
 SG_ HVEM_Nachladen_Anf  : 42|1@1+ (1.000000,0.000000) [0.000000|1.000000] "" Vector__XXX
 SG_ HVEM_FreigabeKlimatisierung  : 43|2@1+ (1.000000,0.000000) [0.000000|3.000000] "" Vector__XXX
 SG_ HVEM_Leistung_Bat_Kond_Vorgabe  : 56|8@1+ (50.000000,0.000000) [0.000000|12650.000000] "Unit_Watt" Vector__XXX

BO_ 1283 HVK_01: 8 Motor_BEV
 SG_ HVK_01_CRC  : 0|8@1+ (1.000000,0.000000) [0.000000|255.000000] "" ICAS1_Gateway LE1 LE2
 SG_ HVK_01_BZ  : 8|4@1+ (1.000000,0.000000) [0.000000|15.000000] "" ICAS1_Gateway LE1 LE2
 SG_ HVK_Istmodus_Anf  : 12|1@1+ (1.000000,0.000000) [0.000000|1.000000] "" ICAS1_Gateway
 SG_ HVK_TN1_Sollmodus  : 13|2@1+ (1.000000,0.000000) [0.000000|3.000000] "" ICAS1_Gateway
 SG_ HVK_Vorladung_aktiv  : 15|1@1+ (1.000000,0.000000) [0.000000|1.000000] "" ICAS1_Gateway
 SG_ HVK_BMS_Sollmodus  : 24|3@1+ (1.000000,0.000000) [0.000000|7.000000] "" ICAS1_Gateway
 SG_ HVK_DCDC_Sollmodus  : 27|3@1+ (1.000000,0.000000) [0.000000|7.000000] "" ICAS1_Gateway
 SG_ HVK_EKK_Sollmodus  : 30|3@1+ (1.000000,0.000000) [0.000000|7.000000] "" ICAS1_Gateway
 SG_ HVK_HVPTC_Sollmodus  : 33|3@1+ (1.000000,0.000000) [0.000000|7.000000] "" ICAS1_Gateway
 SG_ HVK_HVLM_Sollmodus  : 36|3@1+ (1.000000,0.000000) [0.000000|7.000000] "" ICAS1_Gateway
 SG_ HVK_HV_Netz_Warnungen  : 39|2@1+ (1.000000,0.000000) [0.000000|3.000000] "" ICAS1_Gateway ICAS1_KommunikationsServer
 SG_ HV_Bordnetz_aktiv  : 41|1@1+ (1.000000,0.000000) [0.000000|1.000000] "" ICAS1_Gateway LE1 LE2
 SG_ HV_Bordnetz_Fehler  : 42|1@1+ (1.000000,0.000000) [0.000000|1.000000] "" ICAS1_Gateway
 SG_ HVK_Gesamtst_Spgfreiheit  : 43|2@1+ (1.000000,0.000000) [0.000000|3.000000] "" ICAS1_Gateway ICAS1_KommunikationsServer
 SG_ HVK_AktiveEntladung_Anf  : 45|1@1+ (1.000000,0.000000) [0.000000|1.000000] "" ICAS1_Gateway LE1 LE2
 SG_ HVK_HVEM_Freigabe  : 46|2@1+ (1.000000,0.000000) [0.000000|3.000000] "" ICAS1_Gateway
 SG_ HVK_Notentladung_Anf  : 48|2@1+ (1.000000,0.000000) [0.000000|3.000000] "" ICAS1_Gateway LE1 LE2
 SG_ HVK_Iso_Messung_Start  : 50|3@1+ (1.000000,0.000000) [0.000000|7.000000] "" ICAS1_Gateway
 SG_ HVK_Ladebereit  : 53|3@1+ (1.000000,0.000000) [0.000000|7.000000] "" ICAS1_Gateway
 SG_ HVK_PPulsFreigabe  : 56|2@1+ (1.000000,0.000000) [0.000000|3.000000] "" ICAS1_Gateway

BO_ 2463978813 HVL_01: 8 ICAS1_Gateway
 SG_ HVL_01_CRC  : 0|8@1+ (1.000000,0.000000) [0.000000|255.000000] "" Motor_BEV
 SG_ HVL_01_BZ  : 8|4@1+ (1.000000,0.000000) [0.000000|15.000000] "" Motor_BEV
 SG_ HVL_Steckerstatus  : 12|2@1+ (1.000000,0.000000) [0.000000|3.000000] "" Motor_BEV
 SG_ HVL_LadeAnforderung  : 24|3@1+ (1.000000,0.000000) [0.000000|7.000000] "" Motor_BEV

BO_ 626 HVLM_14: 8 ICAS1_Gateway
 SG_ HVLM_Anforderung_HMS  : 27|3@1+ (1.000000,0.000000) [0.000000|7.000000] "" Vector__XXX
 SG_ HVLM_Parken_beibehalten_HMS  : 30|2@1+ (1.000000,0.000000) [0.000000|3.000000] "" Vector__XXX
 SG_ HVLM_WakeUpZaehlerResetAnf  : 32|1@1+ (1.000000,0.000000) [0.000000|1.000000] "" Vector__XXX
 SG_ HVLM_AWC_VerbautStatus  : 33|2@1+ (1.000000,0.000000) [0.000000|3.000000] "" Motor_BEV
 SG_ HVLM_Steckerstatus_A  : 35|3@1+ (1.000000,0.000000) [0.000000|7.000000] "" Motor_BEV
 SG_ HVLM_Steckerstatus_B  : 38|3@1+ (1.000000,0.000000) [0.000000|7.000000] "" Vector__XXX
 SG_ HVLM_Start_Pulserkennung  : 41|1@1+ (1.000000,0.000000) [0.000000|1.000000] "" Vector__XXX
 SG_ HVLM_ZustandLadeablauf  : 42|4@1+ (1.000000,0.000000) [0.000000|15.000000] "" Motor_BEV
 SG_ HVLM_DC_Aufstartmodus  : 46|2@1+ (1.000000,0.000000) [0.000000|3.000000] "" Motor_BEV
 SG_ HVLM_Ladeszenario  : 48|5@1+ (1.000000,0.000000) [0.000000|31.000000] "" Vector__XXX
 SG_ HVLM_Ladevorgang_Anf  : 53|3@1+ (1.000000,0.000000) [0.000000|7.000000] "" Motor_BEV
 SG_ HVLM_Intensitaet  : 56|7@1+ (1.000000,0.000000) [0.000000|100.000000] "Unit_PerCent" Vector__XXX
 SG_ HVLM_Laden_ISO_Messung_Anf  : 63|1@1+ (1.000000,0.000000) [0.000000|1.000000] "" Motor_BEV

BO_ 268 IMMO_CORD_01: 8 Motor_BEV
 SG_ ImoCord_Auth_Aufforderung_WFS  : 63|1@1+ (1.000000,0.000000) [0.000000|1.000000] "" LE1 LE2

BO_ 23 IMMO_MSG3_Antwort: 8 ICAS1_Gateway
 SG_ WFS_IMMO_MSG3_CRC  : 0|32@1+ (1.000000,0.000000) [0.000000|4294967295.000000] "" LE2
 SG_ WFS_IMMO_MSG3_Status  : 56|8@1+ (1.000000,0.000000) [0.000000|255.000000] "" LE2

BO_ 25 IMMO_MSG4_Antwort: 8 ICAS1_Gateway
 SG_ WFS_IMMO_MSG4_CRC  : 0|32@1+ (1.000000,0.000000) [0.000000|4294967295.000000] "" LE1
 SG_ WFS_IMMO_MSG4_Status  : 56|8@1+ (1.000000,0.000000) [0.000000|255.000000] "" LE1

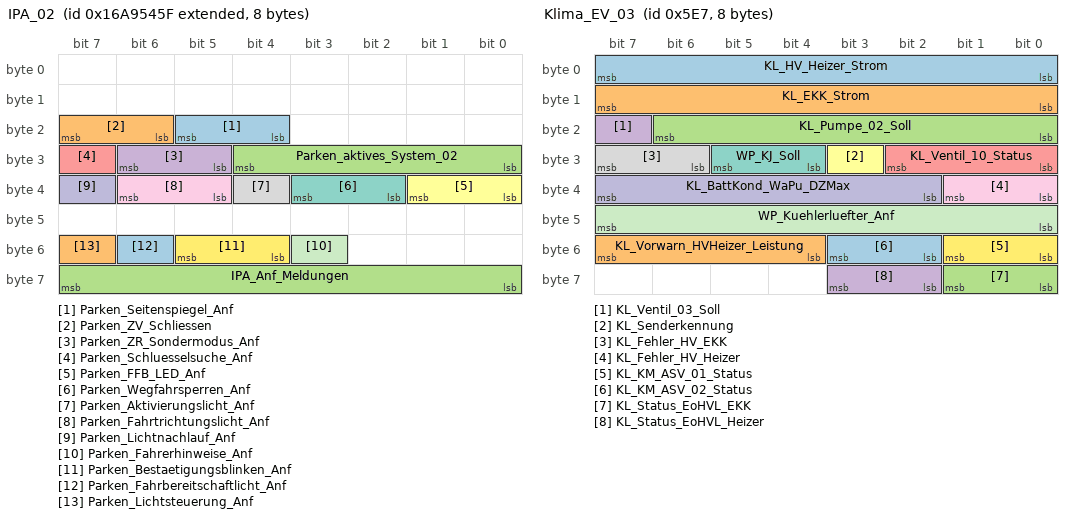
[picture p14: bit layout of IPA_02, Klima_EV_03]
BO_ 2527679583 IPA_02: 8 ICAS1_Gateway
 SG_ Parken_Seitenspiegel_Anf  : 20|2@1+ (1.000000,0.000000) [0.000000|3.000000] "" Vector__XXX
 SG_ Parken_ZV_Schliessen  : 22|2@1+ (1.000000,0.000000) [0.000000|3.000000] "" Vector__XXX
 SG_ Parken_aktives_System_02  : 24|5@1+ (1.000000,0.000000) [0.000000|31.000000] "" Vector__XXX
 SG_ Parken_ZR_Sondermodus_Anf  : 29|2@1+ (1.000000,0.000000) [0.000000|3.000000] "" Vector__XXX
 SG_ Parken_Schluesselsuche_Anf  : 31|1@1+ (1.000000,0.000000) [0.000000|1.000000] "" Vector__XXX
 SG_ Parken_FFB_LED_Anf  : 32|2@1+ (1.000000,0.000000) [0.000000|3.000000] "" Vector__XXX
 SG_ Parken_Wegfahrsperren_Anf  : 34|2@1+ (1.000000,0.000000) [0.000000|3.000000] "" LE1 LE2
 SG_ Parken_Aktivierungslicht_Anf  : 36|1@1+ (1.000000,0.000000) [0.000000|1.000000] "" Vector__XXX
 SG_ Parken_Fahrtrichtungslicht_Anf  : 37|2@1+ (1.000000,0.000000) [0.000000|3.000000] "" Vector__XXX
 SG_ Parken_Lichtnachlauf_Anf  : 39|1@1+ (1.000000,0.000000) [0.000000|1.000000] "" Vector__XXX
 SG_ Parken_Fahrerhinweise_Anf  : 51|1@1+ (1.000000,0.000000) [0.000000|1.000000] "" Vector__XXX
 SG_ Parken_Bestaetigungsblinken_Anf  : 52|2@1+ (1.000000,0.000000) [0.000000|3.000000] "" Vector__XXX
 SG_ Parken_Fahrbereitschaftlicht_Anf  : 54|1@1+ (1.000000,0.000000) [0.000000|1.000000] "" Vector__XXX
 SG_ Parken_Lichtsteuerung_Anf  : 55|1@1+ (1.000000,0.000000) [0.000000|1.000000] "" Vector__XXX
 SG_ IPA_Anf_Meldungen  : 56|8@1+ (1.000000,0.000000) [0.000000|255.000000] "" Vector__XXX

BO_ 1813 ISO_Airbag_01_Req: 8 ICAS1_Gateway
 SG_ ISO_Airbag_01_Req_Data  : 0|64@1+ (1.000000,0.000000) [0.000000|18446744073709551616.000000] "" Airbag

BO_ 1919 ISO_Airbag_01_Resp: 8 Airbag
 SG_ ISO_Airbag_01_Resp_Data  : 0|64@1+ (1.000000,0.000000) [0.000000|18446744073709551616.000000] "" ICAS1_Gateway

BO_ 1792 ISO_Funktionaler_Req_All: 8 ICAS1_Gateway
 SG_ ISO_ALL_01_Req_Data  : 0|64@1+ (1.000000,0.000000) [0.000000|18446744073709551616.000000] "" Airbag LE1 LE2 Motor_BEV

BO_ 2621440021 ISOx_Airbag_01_Req_FD: 64 ICAS1_Gateway
 SG_ ISOx_Airbag_01_Req_FD_Data  : 0|512@1+ (1.000000,0.000000) [0.000000|13407807929942597099574024998205846127479365820592393377723561443721764030073546976801874298166903427690031858186486050853753882811946569946433649006084096.000000] "" Airbag

BO_ 2621571093 ISOx_Airbag_01_Resp_FD: 64 Airbag
 SG_ ISOx_Airbag_01_Resp_FD_Data  : 0|512@1+ (1.000000,0.000000) [0.000000|13407807929942597099574024998205846127479365820592393377723561443721764030073546976801874298166903427690031858186486050853753882811946569946433649006084096.000000] "" ICAS1_Gateway

BO_ 2549874812 ISOx_EMotor_01_Req: 8 ICAS1_Gateway
 SG_ ISO_EMotor_01_Req_Data  : 0|64@1+ (1.000000,0.000000) [0.000000|18446744073709551616.000000] "" LE1

BO_ 2621440124 ISOx_EMotor_01_Req_FD: 64 ICAS1_Gateway
 SG_ ISOx_EMotor_01_Req_FD_Data  : 0|512@1+ (1.000000,0.000000) [0.000000|13407807929942597099574024998205846127479365820592393377723561443721764030073546976801874298166903427690031858186486050853753882811946569946433649006084096.000000] "" LE1

BO_ 2550005884 ISOx_EMotor_01_Resp: 8 LE1
 SG_ ISO_EMotor_01_Resp_Data  : 0|64@1+ (1.000000,0.000000) [0.000000|18446744073709551616.000000] "" ICAS1_Gateway

BO_ 2621571196 ISOx_EMotor_01_Resp_FD: 64 LE1
 SG_ ISOx_EMotor_01_Resp_FD_Data  : 0|512@1+ (1.000000,0.000000) [0.000000|13407807929942597099574024998205846127479365820592393377723561443721764030073546976801874298166903427690031858186486050853753882811946569946433649006084096.000000] "" ICAS1_Gateway

BO_ 2549874872 ISOx_EMotor_02_Req: 8 ICAS1_Gateway
 SG_ ISO_EMotor_02_Req_Data  : 0|64@1+ (1.000000,0.000000) [0.000000|18446744073709551616.000000] "" LE2

BO_ 2621440184 ISOx_EMotor_02_Req_FD: 64 ICAS1_Gateway
 SG_ ISOx_EMotor_02_Req_FD_Data  : 0|512@1+ (1.000000,0.000000) [0.000000|13407807929942597099574024998205846127479365820592393377723561443721764030073546976801874298166903427690031858186486050853753882811946569946433649006084096.000000] "" LE2

BO_ 2550005944 ISOx_EMotor_02_Resp: 8 LE2
 SG_ ISO_EMotor_02_Resp_Data  : 0|64@1+ (1.000000,0.000000) [0.000000|18446744073709551616.000000] "" ICAS1_Gateway

BO_ 2621571256 ISOx_EMotor_02_Resp_FD: 64 LE2
 SG_ ISOx_EMotor_02_Resp_FD_Data  : 0|512@1+ (1.000000,0.000000) [0.000000|13407807929942597099574024998205846127479365820592393377723561443721764030073546976801874298166903427690031858186486050853753882811946569946433649006084096.000000] "" ICAS1_Gateway

BO_ 2621505536 ISOx_Funkt_Req_All_FD: 64 ICAS1_Gateway
 SG_ ISOx_Funkt_Req_All_FD_Data  : 0|512@1+ (1.000000,0.000000) [0.000000|13407807929942597099574024998205846127479365820592393377723561443721764030073546976801874298166903427690031858186486050853753882811946569946433649006084096.000000] "" Airbag LE1 LE2 Motor_BEV

BO_ 2549874806 ISOx_MO_01_Req: 8 ICAS1_Gateway
 SG_ ISOx_MO_01_Req_Data  : 0|64@1+ (1.000000,0.000000) [0.000000|18446744073709551616.000000] "" Motor_BEV

BO_ 2621440118 ISOx_MO_01_Req_FD: 64 ICAS1_Gateway
 SG_ ISOx_MO_01_Req_FD_Data  : 0|512@1+ (1.000000,0.000000) [0.000000|13407807929942597099574024998205846127479365820592393377723561443721764030073546976801874298166903427690031858186486050853753882811946569946433649006084096.000000] "" Motor_BEV

BO_ 2550005878 ISOx_MO_01_Resp: 8 Motor_BEV
 SG_ ISOx_MO_01_Resp_Data  : 0|64@1+ (1.000000,0.000000) [0.000000|18446744073709551616.000000] "" ICAS1_Gateway

BO_ 2621571190 ISOx_MO_01_Resp_FD: 64 Motor_BEV
 SG_ ISOx_MO_01_Resp_FD_Data  : 0|512@1+ (1.000000,0.000000) [0.000000|13407807929942597099574024998205846127479365820592393377723561443721764030073546976801874298166903427690031858186486050853753882811946569946433649006084096.000000] "" ICAS1_Gateway

BO_ 2527679684 Kamera_ASM_01: 8 ICAS1_Gateway
 SG_ Kamera_ASM_Ereignis  : 0|8@1+ (1.000000,0.000000) [1.000000|254.000000] "" Airbag
 SG_ Kamera_ASM_Zeitstempel  : 8|8@1+ (0.080000,0.000000) [0.000000|20.320000] "Unit_Secon" Airbag
 SG_ Kamera_ASM_Data_1  : 16|8@1+ (1.000000,0.000000) [0.000000|255.000000] "" Airbag
 SG_ Kamera_ASM_Data_2  : 24|8@1+ (1.000000,0.000000) [0.000000|255.000000] "" Airbag
 SG_ Kamera_ASM_Data_3  : 32|8@1+ (1.000000,0.000000) [0.000000|255.000000] "" Airbag
 SG_ Kamera_ASM_Data_4  : 40|8@1+ (1.000000,0.000000) [0.000000|255.000000] "" Airbag
 SG_ Kamera_ASM_Data_5  : 48|8@1+ (1.000000,0.000000) [0.000000|255.000000] "" Airbag
 SG_ Kamera_ASM_Data_6  : 56|8@1+ (1.000000,0.000000) [0.000000|255.000000] "" Airbag

BO_ 960 Klemmen_Status_01: 4 ICAS1_Gateway
 SG_ Klemmen_Status_01_CRC  : 0|8@1+ (1.000000,0.000000) [0.000000|255.000000] "" Motor_BEV
 SG_ Klemmen_Status_01_BZ  : 8|4@1+ (1.000000,0.000000) [0.000000|15.000000] "" Motor_BEV
 SG_ RSt_Fahrerhinweise  : 12|4@1+ (1.000000,0.000000) [0.000000|15.000000] "" Vector__XXX
 SG_ ZAS_Kl_S  : 16|1@1+ (1.000000,0.000000) [0.000000|1.000000] "" Vector__XXX
 SG_ ZAS_Kl_15  : 17|1@1+ (1.000000,0.000000) [0.000000|1.000000] "" Airbag LE1 LE2 Motor_BEV Schaltbetaetigung
 SG_ ZAS_Kl_X  : 18|1@1+ (1.000000,0.000000) [0.000000|1.000000] "" Vector__XXX
 SG_ ZAS_Kl_50_Startanforderung  : 19|1@1+ (1.000000,0.000000) [0.000000|1.000000] "" Motor_BEV
 SG_ BCM_Remotestart_Betrieb  : 20|1@1+ (1.000000,0.000000) [0.000000|1.000000] "" Vector__XXX
 SG_ ZAS_Kl_Infotainment  : 21|1@1+ (1.000000,0.000000) [0.000000|1.000000] "" Vector__XXX
 SG_ BCM_Remotestart_KL15_Anf  : 22|1@1+ (1.000000,0.000000) [0.000000|1.000000] "" Vector__XXX
 SG_ BCM_Remotestart_MO_Start  : 23|1@1+ (1.000000,0.000000) [0.000000|1.000000] "" Vector__XXX
 SG_ KST_Warn_P1_ZST_def  : 24|1@1+ (1.000000,0.000000) [0.000000|1.000000] "" Vector__XXX
 SG_ KST_Warn_P2_ZST_def  : 25|1@1+ (1.000000,0.000000) [0.000000|1.000000] "" Vector__XXX
 SG_ KST_Fahrerhinweis_1  : 26|1@1+ (1.000000,0.000000) [0.000000|1.000000] "" Vector__XXX
 SG_ KST_Fahrerhinweis_2  : 27|1@1+ (1.000000,0.000000) [0.000000|1.000000] "" Vector__XXX
 SG_ BCM_Ausparken_Betrieb  : 28|1@1+ (1.000000,0.000000) [0.000000|1.000000] "" Vector__XXX
 SG_ KST_Fahrerhinweis_4  : 29|1@1+ (1.000000,0.000000) [0.000000|1.000000] "" Vector__XXX
 SG_ KST_Fahrerhinweis_5  : 30|1@1+ (1.000000,0.000000) [0.000000|1.000000] "" Vector__XXX
 SG_ KST_Fahrerhinweis_6  : 31|1@1+ (1.000000,0.000000) [0.000000|1.000000] "" Vector__XXX

BO_ 2463978753 Klemmen_Status_02: 8 ICAS1_Gateway
 SG_ KST_WFS_Fahrfreigabe_Anforderung  : 12|2@1+ (1.000000,0.000000) [0.000000|3.000000] "" LE1 LE2
 SG_ KST_Sonderzustand_Status  : 14|2@1+ (1.000000,0.000000) [0.000000|3.000000] "" LE1 LE2
 SG_ KST_Sonderzustand_Anforderung  : 16|5@1+ (1.000000,0.000000) [0.000000|31.000000] "" LE1 LE2

BO_ 1420 Klemmen_Steuerung_01: 8 ICAS1_Gateway
 SG_ Klemmen_Steuerung_01_CRC  : 0|8@1+ (1.000000,0.000000) [0.000000|255.000000] "" Vector__XXX
 SG_ Klemmen_Steuerung_01_BZ  : 8|4@1+ (1.000000,0.000000) [0.000000|15.000000] "" Vector__XXX
 SG_ KST_Anf_Klemme_15  : 12|1@1+ (1.000000,0.000000) [0.000000|1.000000] "" Vector__XXX
 SG_ KST_Anf_Klemme_50  : 13|1@1+ (1.000000,0.000000) [0.000000|1.000000] "" Motor_BEV
 SG_ KST_Anf_Klemme_S  : 14|1@1+ (1.000000,0.000000) [0.000000|1.000000] "" Vector__XXX
 SG_ KST_Txt_Werkstatt  : 15|1@1+ (1.000000,0.000000) [0.000000|1.000000] "" Vector__XXX
 SG_ KST_Txt_P_Gang  : 16|1@1+ (1.000000,0.000000) [0.000000|1.000000] "" Vector__XXX
 SG_ KST_Txt_Panikabschaltung  : 17|1@1+ (1.000000,0.000000) [0.000000|1.000000] "" Vector__XXX
 SG_ KST_Anf_Klemmenfreigabe_ELV  : 18|1@1+ (1.000000,0.000000) [0.000000|1.000000] "" Vector__XXX
 SG_ KST_Txt_Komfortabschaltung  : 19|1@1+ (1.000000,0.000000) [0.000000|1.000000] "" Vector__XXX
 SG_ KST_ZAT_betaetigt  : 20|1@1+ (1.000000,0.000000) [0.000000|1.000000] "" Vector__XXX
 SG_ KST_Unterdr_Zuendungsmeldung  : 21|1@1+ (1.000000,0.000000) [0.000000|1.000000] "" Vector__XXX
 SG_ KST_aut_Abschaltung_Zuendung  : 22|1@1+ (1.000000,0.000000) [0.000000|1.000000] "" Vector__XXX
 SG_ KST_Anf_Klemmenfreigabe_WFS  : 23|1@1+ (1.000000,0.000000) [0.000000|1.000000] "" Vector__XXX
 SG_ KST_Anf_ZV_Verriegelung  : 24|1@1+ (1.000000,0.000000) [0.000000|1.000000] "" Vector__XXX
 SG_ Relais_VoKo_angesteuert  : 25|1@1+ (1.000000,0.000000) [0.000000|1.000000] "" Vector__XXX
 SG_ RSt_Anforderung_HMS  : 26|3@1+ (1.000000,0.000000) [0.000000|7.000000] "" Vector__XXX
 SG_ KST_Zuendungswarnung  : 29|2@1+ (1.000000,0.000000) [0.000000|3.000000] "" Vector__XXX
 SG_ KST_Fahrer_Info_Text  : 31|3@1+ (1.000000,0.000000) [0.000000|7.000000] "" Vector__XXX

BO_ 949 Klima_11: 8 ICAS1_Gateway
 SG_ KL_Drehz_Anh  : 0|1@1+ (1.000000,0.000000) [0.000000|1.000000] "" Vector__XXX
 SG_ KL_Vorwarn_Komp_ein  : 1|1@1+ (1.000000,0.000000) [0.000000|1.000000] "" Vector__XXX
 SG_ KL_AC_Schalter  : 2|1@1+ (1.000000,0.000000) [0.000000|1.000000] "" Vector__XXX
 SG_ KL_Komp_Moment_alt  : 3|1@1+ (1.000000,0.000000) [0.000000|1.000000] "" Vector__XXX
 SG_ KL_Vorwarn_Zuheizer_ein  : 6|1@1+ (1.000000,0.000000) [0.000000|1.000000] "" Vector__XXX
 SG_ KL_Zustand  : 7|1@1+ (1.000000,0.000000) [0.000000|1.000000] "" Vector__XXX
 SG_ KL_Kompressorkupplung_linear  : 8|8@1+ (20.000000,0.000000) [0.000000|4000.000000] "Unit_MilliAmper" Vector__XXX
 SG_ KL_Charisma_FahrPr  : 16|4@1+ (1.000000,0.000000) [0.000000|15.000000] "" Vector__XXX
 SG_ KL_Charisma_Status  : 20|2@1+ (1.000000,0.000000) [0.000000|3.000000] "" Vector__XXX
 SG_ KL_nachtr_Stopp_Anf  : 22|1@1+ (1.000000,0.000000) [0.000000|1.000000] "" Vector__XXX
 SG_ KL_T_Charge  : 23|1@1+ (1.000000,0.000000) [0.000000|1.000000] "" Vector__XXX
 SG_ KL_Last_Kompr  : 24|8@1+ (0.250000,0.000000) [0.000000|63.500000] "Unit_NewtoMeter" Vector__XXX
 SG_ KL_Spannungs_Anf  : 32|2@1+ (1.000000,0.000000) [0.000000|3.000000] "" Vector__XXX
 SG_ KL_Thermomanagement  : 34|2@1+ (1.000000,0.000000) [0.000000|3.000000] "" Motor_BEV
 SG_ KL_StartStopp_Info  : 36|2@1+ (1.000000,0.000000) [0.000000|3.000000] "" Vector__XXX
 SG_ KL_Freilauf_Info  : 38|2@1+ (1.000000,0.000000) [0.000000|3.000000] "" Vector__XXX
 SG_ KL_Anf_KL  : 40|8@1+ (0.400000,0.000000) [0.000000|101.600000] "Unit_PerCent" Motor_BEV
 SG_ KL_el_Zuheizer_Stufe  : 48|3@1+ (1.000000,0.000000) [0.000000|7.000000] "" Vector__XXX
 SG_ KL_Ausstattung_Klima  : 51|3@1+ (1.000000,0.000000) [0.000000|7.000000] "" Vector__XXX
 SG_ KL_Variante_Standheizung  : 54|2@1+ (1.000000,0.000000) [0.000000|3.000000] "" Vector__XXX
 SG_ KL_Anf_KV  : 57|7@1+ (1.000000,0.000000) [0.000000|100.000000] "Unit_PerCent" Motor_BEV

BO_ 1511 Klima_EV_03: 8 ICAS1_Gateway
 SG_ KL_HV_Heizer_Strom  : 0|8@1+ (0.250000,0.000000) [0.000000|63.500000] "Unit_Amper" Motor_BEV
 SG_ KL_EKK_Strom  : 8|8@1+ (0.250000,0.000000) [0.000000|63.500000] "Unit_Amper" Motor_BEV
 SG_ KL_Pumpe_02_Soll  : 16|7@1+ (1.000000,0.000000) [0.000000|100.000000] "Unit_PerCent" Motor_BEV
 SG_ KL_Ventil_03_Soll  : 23|1@1+ (1.000000,0.000000) [0.000000|1.000000] "" Vector__XXX
 SG_ KL_Ventil_10_Status  : 24|3@1+ (1.000000,0.000000) [0.000000|7.000000] "" Vector__XXX
 SG_ KL_Senderkennung  : 27|1@1+ (1.000000,0.000000) [0.000000|1.000000] "" Vector__XXX
 SG_ WP_KJ_Soll  : 28|2@1+ (1.000000,0.000000) [0.000000|3.000000] "" Vector__XXX
 SG_ KL_Fehler_HV_EKK  : 30|2@1+ (1.000000,0.000000) [0.000000|3.000000] "" Vector__XXX
 SG_ KL_Fehler_HV_Heizer  : 32|2@1+ (1.000000,0.000000) [0.000000|3.000000] "" Vector__XXX
 SG_ KL_BattKond_WaPu_DZMax  : 34|6@1+ (2.000000,0.000000) [0.000000|100.000000] "Unit_PerCent" Vector__XXX
 SG_ WP_Kuehlerluefter_Anf  : 40|8@1+ (0.400000,0.000000) [0.000000|101.600000] "Unit_PerCent" Vector__XXX
 SG_ KL_KM_ASV_01_Status  : 48|2@1+ (1.000000,0.000000) [0.000000|3.000000] "" Vector__XXX
 SG_ KL_KM_ASV_02_Status  : 50|2@1+ (1.000000,0.000000) [0.000000|3.000000] "" Vector__XXX
 SG_ KL_Vorwarn_HVHeizer_Leistung  : 52|4@1+ (1.000000,0.000000) [0.000000|15.000000] "" Vector__XXX
 SG_ KL_Status_EoHVL_EKK  : 56|2@1+ (1.000000,0.000000) [0.000000|3.000000] "" Motor_BEV
 SG_ KL_Status_EoHVL_Heizer  : 58|2@1+ (1.000000,0.000000) [0.000000|3.000000] "" Motor_BEV

BU_:  Airbag BAP_Tester ICAS1_Gateway ICAS1_KommunikationsServer LE1 LE2 Motor_BEV Schaltbetaetigung

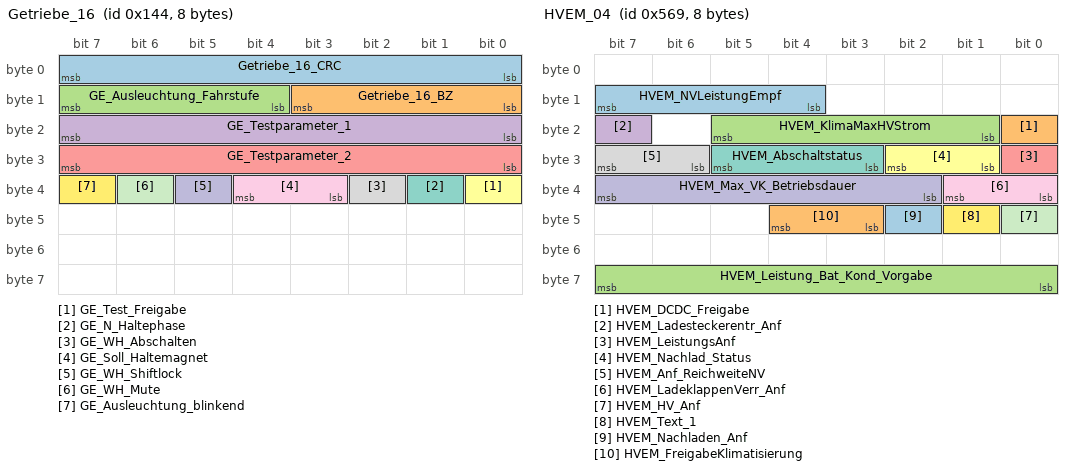
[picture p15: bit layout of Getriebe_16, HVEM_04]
BO_ 324 Getriebe_16: 8 Motor_BEV
 SG_ Getriebe_16_CRC  : 0|8@1+ (1.000000,0.000000) [0.000000|255.000000] "" ICAS1_Gateway Schaltbetaetigung
 SG_ Getriebe_16_BZ  : 8|4@1+ (1.000000,0.000000) [0.000000|15.000000] "" ICAS1_Gateway Schaltbetaetigung
 SG_ GE_Ausleuchtung_Fahrstufe  : 12|4@1+ (1.000000,0.000000) [0.000000|15.000000] "" ICAS1_Gateway Schaltbetaetigung
 SG_ GE_Testparameter_1  : 16|8@1+ (1.000000,0.000000) [0.000000|255.000000] "" ICAS1_Gateway Schaltbetaetigung
 SG_ GE_Testparameter_2  : 24|8@1+ (1.000000,0.000000) [0.000000|255.000000] "" ICAS1_Gateway Schaltbetaetigung
 SG_ GE_Test_Freigabe  : 32|1@1+ (1.000000,0.000000) [0.000000|1.000000] "" ICAS1_Gateway Schaltbetaetigung
 SG_ GE_N_Haltephase  : 33|1@1+ (1.000000,0.000000) [0.000000|1.000000] "" ICAS1_Gateway Schaltbetaetigung
 SG_ GE_WH_Abschalten  : 34|1@1+ (1.000000,0.000000) [0.000000|1.000000] "" ICAS1_Gateway Schaltbetaetigung
 SG_ GE_Soll_Haltemagnet  : 35|2@1+ (1.000000,0.000000) [0.000000|3.000000] "" ICAS1_Gateway Schaltbetaetigung
 SG_ GE_WH_Shiftlock  : 37|1@1+ (1.000000,0.000000) [0.000000|1.000000] "" ICAS1_Gateway Schaltbetaetigung
 SG_ GE_WH_Mute  : 38|1@1+ (1.000000,0.000000) [0.000000|1.000000] "" ICAS1_Gateway Schaltbetaetigung
 SG_ GE_Ausleuchtung_blinkend  : 39|1@1+ (1.000000,0.000000) [0.000000|1.000000] "" ICAS1_Gateway Schaltbetaetigung

BO_ 299 GRA_ACC_01: 8 ICAS1_Gateway
 SG_ GRA_ACC_01_CRC  : 0|8@1+ (1.000000,0.000000) [0.000000|255.000000] "" Motor_BEV
 SG_ GRA_ACC_01_BZ  : 8|4@1+ (1.000000,0.000000) [0.000000|15.000000] "" Motor_BEV
 SG_ GRA_Hauptschalter  : 12|1@1+ (1.000000,0.000000) [0.000000|1.000000] "" Motor_BEV
 SG_ GRA_Abbrechen  : 13|1@1+ (1.000000,0.000000) [0.000000|1.000000] "" Motor_BEV
 SG_ GRA_Typ_Hauptschalter  : 14|1@1+ (1.000000,0.000000) [0.000000|1.000000] "" Motor_BEV
 SG_ GRA_Limiter  : 15|1@1+ (1.000000,0.000000) [0.000000|1.000000] "" Motor_BEV
 SG_ GRA_Tip_Setzen  : 16|1@1+ (1.000000,0.000000) [0.000000|1.000000] "" Motor_BEV
 SG_ GRA_Tip_Hoch  : 17|1@1+ (1.000000,0.000000) [0.000000|1.000000] "" Motor_BEV
 SG_ GRA_Tip_Runter  : 18|1@1+ (1.000000,0.000000) [0.000000|1.000000] "" Motor_BEV
 SG_ GRA_Tip_Wiederaufnahme  : 19|1@1+ (1.000000,0.000000) [0.000000|1.000000] "" Motor_BEV
 SG_ GRA_Verstellung_Zeitluecke  : 20|2@1+ (1.000000,0.000000) [0.000000|3.000000] "" Vector__XXX
 SG_ GRA_Codierung  : 22|2@1+ (1.000000,0.000000) [0.000000|3.000000] "" Motor_BEV
 SG_ GRA_Fehler  : 24|1@1+ (1.000000,0.000000) [0.000000|1.000000] "" Motor_BEV
 SG_ GRA_LIM_Taste_verfuegbar  : 25|1@1+ (1.000000,0.000000) [0.000000|1.000000] "" Motor_BEV
 SG_ GRA_Tip_Stufe_2  : 26|1@1+ (1.000000,0.000000) [0.000000|1.000000] "" Motor_BEV
 SG_ GRA_Typ_Bedienteil  : 27|3@1+ (1.000000,0.000000) [0.000000|7.000000] "" Motor_BEV
 SG_ GRA_TravelAssist  : 30|1@1+ (1.000000,0.000000) [0.000000|1.000000] "" Vector__XXX
 SG_ GRA_reserveByte4  : 31|1@1+ (1.000000,0.000000) [0.000000|1.000000] "" Vector__XXX
 SG_ GRA_reserveByte5  : 32|8@1+ (1.000000,0.000000) [0.000000|255.000000] "" Vector__XXX
 SG_ GRA_reserveByte6  : 40|8@1+ (1.000000,0.000000) [0.000000|255.000000] "" Vector__XXX
 SG_ GRA_reserveByte7  : 48|8@1+ (1.000000,0.000000) [0.000000|255.000000] "" Vector__XXX
 SG_ GRA_reserveByte8  : 56|8@1+ (1.000000,0.000000) [0.000000|255.000000] "" Vector__XXX

BO_ 1452 HVEM_02: 8 ICAS1_Gateway
 SG_ HVEM_IstStrom_HVVerbraucher  : 0|12@1+ (0.100000,-204.700000) [-204.700000|204.600000] "Unit_Amper" Vector__XXX
 SG_ HVEM_Energie_Klima_Vorgabe_HighR  : 12|3@1+ (10.000000,0.000000) [0.000000|50.000000] "Unit_WattHour" Vector__XXX
 SG_ HVEM_IstLeistungNA  : 15|9@1+ (50.000000,0.000000) [0.000000|25450.000000] "Unit_Watt" Motor_BEV
 SG_ HVEM_Leistung_Klima_Vorgabe  : 24|8@1+ (50.000000,0.000000) [0.000000|12650.000000] "Unit_Watt" Vector__XXX
 SG_ HVEM_Nutzbare_Energie  : 32|11@1+ (50.000000,0.000000) [0.000000|102200.000000] "Unit_WattHour" Vector__XXX
 SG_ HVEM_Energie_Klima_Vorgabe  : 43|8@1+ (50.000000,0.000000) [0.000000|12650.000000] "Unit_WattHour" Vector__XXX
 SG_ HVEM_HVK_Aktivitaet  : 51|2@1+ (1.000000,0.000000) [0.000000|3.000000] "" Motor_BEV
 SG_ HVEM_Pruefpuls_Anf  : 53|2@1+ (1.000000,0.000000) [0.000000|3.000000] "" Motor_BEV
 SG_ HVEM_HV_Anf  : 62|1@1+ (1.000000,0.000000) [0.000000|1.000000] "" Motor_BEV
 SG_ HVEM_MO_MaxLeistungIgnoriert  : 63|1@1+ (1.000000,0.000000) [0.000000|1.000000] "" Vector__XXX

BO_ 1385 HVEM_04: 8 ICAS1_Gateway
 SG_ HVEM_NVLeistungEmpf  : 12|4@1+ (100.000000,0.000000) [0.000000|1500.000000] "Unit_Watt" Vector__XXX
 SG_ HVEM_DCDC_Freigabe  : 16|1@1+ (1.000000,0.000000) [0.000000|1.000000] "" Motor_BEV
 SG_ HVEM_KlimaMaxHVStrom  : 17|5@1+ (1.000000,0.000000) [0.000000|31.000000] "Unit_Amper" Vector__XXX
 SG_ HVEM_Ladesteckerentr_Anf  : 23|1@1+ (1.000000,0.000000) [0.000000|1.000000] "" Vector__XXX
 SG_ HVEM_LeistungsAnf  : 24|1@1+ (1.000000,0.000000) [0.000000|1.000000] "" Vector__XXX
 SG_ HVEM_Nachlad_Status  : 25|2@1+ (1.000000,0.000000) [0.000000|3.000000] "" Vector__XXX
 SG_ HVEM_Abschaltstatus  : 27|3@1+ (1.000000,0.000000) [0.000000|7.000000] "" Vector__XXX
 SG_ HVEM_Anf_ReichweiteNV  : 30|2@1+ (1.000000,0.000000) [0.000000|3.000000] "" Vector__XXX
 SG_ HVEM_LadeklappenVerr_Anf  : 32|2@1+ (1.000000,0.000000) [0.000000|3.000000] "" Vector__XXX
 SG_ HVEM_Max_VK_Betriebsdauer  : 34|6@1+ (1.000000,0.000000) [0.000000|60.000000] "Unit_Minut" Vector__XXX
 SG_ HVEM_HV_Anf  : 40|1@1+ (1.000000,0.000000) [0.000000|1.000000] "" Vector__XXX
 SG_ HVEM_Text_1  : 41|1@1+ (1.000000,0.000000) [0.000000|1.000000] "" Vector__XXX
 SG_ HVEM_Nachladen_Anf  : 42|1@1+ (1.000000,0.000000) [0.000000|1.000000] "" Vector__XXX
 SG_ HVEM_FreigabeKlimatisierung  : 43|2@1+ (1.000000,0.000000) [0.000000|3.000000] "" Vector__XXX
 SG_ HVEM_Leistung_Bat_Kond_Vorgabe  : 56|8@1+ (50.000000,0.000000) [0.000000|12650.000000] "Unit_Watt" Vector__XXX

BO_ 1283 HVK_01: 8 Motor_BEV
 SG_ HVK_01_CRC  : 0|8@1+ (1.000000,0.000000) [0.000000|255.000000] "" ICAS1_Gateway LE1 LE2
 SG_ HVK_01_BZ  : 8|4@1+ (1.000000,0.000000) [0.000000|15.000000] "" ICAS1_Gateway LE1 LE2
 SG_ HVK_Istmodus_Anf  : 12|1@1+ (1.000000,0.000000) [0.000000|1.000000] "" ICAS1_Gateway
 SG_ HVK_TN1_Sollmodus  : 13|2@1+ (1.000000,0.000000) [0.000000|3.000000] "" ICAS1_Gateway
 SG_ HVK_Vorladung_aktiv  : 15|1@1+ (1.000000,0.000000) [0.000000|1.000000] "" ICAS1_Gateway
 SG_ HVK_BMS_Sollmodus  : 24|3@1+ (1.000000,0.000000) [0.000000|7.000000] "" ICAS1_Gateway
 SG_ HVK_DCDC_Sollmodus  : 27|3@1+ (1.000000,0.000000) [0.000000|7.000000] "" ICAS1_Gateway
 SG_ HVK_EKK_Sollmodus  : 30|3@1+ (1.000000,0.000000) [0.000000|7.000000] "" ICAS1_Gateway
 SG_ HVK_HVPTC_Sollmodus  : 33|3@1+ (1.000000,0.000000) [0.000000|7.000000] "" ICAS1_Gateway
 SG_ HVK_HVLM_Sollmodus  : 36|3@1+ (1.000000,0.000000) [0.000000|7.000000] "" ICAS1_Gateway
 SG_ HVK_HV_Netz_Warnungen  : 39|2@1+ (1.000000,0.000000) [0.000000|3.000000] "" ICAS1_Gateway ICAS1_KommunikationsServer
 SG_ HV_Bordnetz_aktiv  : 41|1@1+ (1.000000,0.000000) [0.000000|1.000000] "" ICAS1_Gateway LE1 LE2
 SG_ HV_Bordnetz_Fehler  : 42|1@1+ (1.000000,0.000000) [0.000000|1.000000] "" ICAS1_Gateway
 SG_ HVK_Gesamtst_Spgfreiheit  : 43|2@1+ (1.000000,0.000000) [0.000000|3.000000] "" ICAS1_Gateway ICAS1_KommunikationsServer
 SG_ HVK_AktiveEntladung_Anf  : 45|1@1+ (1.000000,0.000000) [0.000000|1.000000] "" ICAS1_Gateway LE1 LE2
 SG_ HVK_HVEM_Freigabe  : 46|2@1+ (1.000000,0.000000) [0.000000|3.000000] "" ICAS1_Gateway
 SG_ HVK_Notentladung_Anf  : 48|2@1+ (1.000000,0.000000) [0.000000|3.000000] "" ICAS1_Gateway LE1 LE2
 SG_ HVK_Iso_Messung_Start  : 50|3@1+ (1.000000,0.000000) [0.000000|7.000000] "" ICAS1_Gateway
 SG_ HVK_Ladebereit  : 53|3@1+ (1.000000,0.000000) [0.000000|7.000000] "" ICAS1_Gateway
 SG_ HVK_PPulsFreigabe  : 56|2@1+ (1.000000,0.000000) [0.000000|3.000000] "" ICAS1_Gateway

BO_ 2463978813 HVL_01: 8 ICAS1_Gateway
 SG_ HVL_01_CRC  : 0|8@1+ (1.000000,0.000000) [0.000000|255.000000] "" Motor_BEV
 SG_ HVL_01_BZ  : 8|4@1+ (1.000000,0.000000) [0.000000|15.000000] "" Motor_BEV
 SG_ HVL_Steckerstatus  : 12|2@1+ (1.000000,0.000000) [0.000000|3.000000] "" Motor_BEV
 SG_ HVL_LadeAnforderung  : 24|3@1+ (1.000000,0.000000) [0.000000|7.000000] "" Motor_BEV

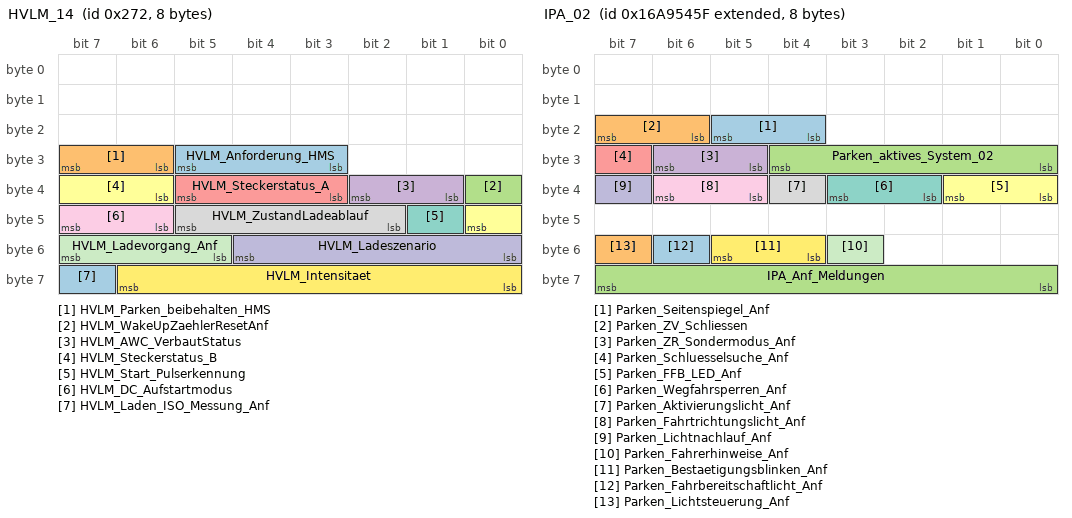
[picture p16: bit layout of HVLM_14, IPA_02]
BO_ 626 HVLM_14: 8 ICAS1_Gateway
 SG_ HVLM_Anforderung_HMS  : 27|3@1+ (1.000000,0.000000) [0.000000|7.000000] "" Vector__XXX
 SG_ HVLM_Parken_beibehalten_HMS  : 30|2@1+ (1.000000,0.000000) [0.000000|3.000000] "" Vector__XXX
 SG_ HVLM_WakeUpZaehlerResetAnf  : 32|1@1+ (1.000000,0.000000) [0.000000|1.000000] "" Vector__XXX
 SG_ HVLM_AWC_VerbautStatus  : 33|2@1+ (1.000000,0.000000) [0.000000|3.000000] "" Motor_BEV
 SG_ HVLM_Steckerstatus_A  : 35|3@1+ (1.000000,0.000000) [0.000000|7.000000] "" Motor_BEV
 SG_ HVLM_Steckerstatus_B  : 38|3@1+ (1.000000,0.000000) [0.000000|7.000000] "" Vector__XXX
 SG_ HVLM_Start_Pulserkennung  : 41|1@1+ (1.000000,0.000000) [0.000000|1.000000] "" Vector__XXX
 SG_ HVLM_ZustandLadeablauf  : 42|4@1+ (1.000000,0.000000) [0.000000|15.000000] "" Motor_BEV
 SG_ HVLM_DC_Aufstartmodus  : 46|2@1+ (1.000000,0.000000) [0.000000|3.000000] "" Motor_BEV
 SG_ HVLM_Ladeszenario  : 48|5@1+ (1.000000,0.000000) [0.000000|31.000000] "" Vector__XXX
 SG_ HVLM_Ladevorgang_Anf  : 53|3@1+ (1.000000,0.000000) [0.000000|7.000000] "" Motor_BEV
 SG_ HVLM_Intensitaet  : 56|7@1+ (1.000000,0.000000) [0.000000|100.000000] "Unit_PerCent" Vector__XXX
 SG_ HVLM_Laden_ISO_Messung_Anf  : 63|1@1+ (1.000000,0.000000) [0.000000|1.000000] "" Motor_BEV

BO_ 268 IMMO_CORD_01: 8 Motor_BEV
 SG_ ImoCord_Auth_Aufforderung_WFS  : 63|1@1+ (1.000000,0.000000) [0.000000|1.000000] "" LE1 LE2

BO_ 23 IMMO_MSG3_Antwort: 8 ICAS1_Gateway
 SG_ WFS_IMMO_MSG3_CRC  : 0|32@1+ (1.000000,0.000000) [0.000000|4294967295.000000] "" LE2
 SG_ WFS_IMMO_MSG3_Status  : 56|8@1+ (1.000000,0.000000) [0.000000|255.000000] "" LE2

BO_ 25 IMMO_MSG4_Antwort: 8 ICAS1_Gateway
 SG_ WFS_IMMO_MSG4_CRC  : 0|32@1+ (1.000000,0.000000) [0.000000|4294967295.000000] "" LE1
 SG_ WFS_IMMO_MSG4_Status  : 56|8@1+ (1.000000,0.000000) [0.000000|255.000000] "" LE1

BO_ 2527679583 IPA_02: 8 ICAS1_Gateway
 SG_ Parken_Seitenspiegel_Anf  : 20|2@1+ (1.000000,0.000000) [0.000000|3.000000] "" Vector__XXX
 SG_ Parken_ZV_Schliessen  : 22|2@1+ (1.000000,0.000000) [0.000000|3.000000] "" Vector__XXX
 SG_ Parken_aktives_System_02  : 24|5@1+ (1.000000,0.000000) [0.000000|31.000000] "" Vector__XXX
 SG_ Parken_ZR_Sondermodus_Anf  : 29|2@1+ (1.000000,0.000000) [0.000000|3.000000] "" Vector__XXX
 SG_ Parken_Schluesselsuche_Anf  : 31|1@1+ (1.000000,0.000000) [0.000000|1.000000] "" Vector__XXX
 SG_ Parken_FFB_LED_Anf  : 32|2@1+ (1.000000,0.000000) [0.000000|3.000000] "" Vector__XXX
 SG_ Parken_Wegfahrsperren_Anf  : 34|2@1+ (1.000000,0.000000) [0.000000|3.000000] "" LE1 LE2
 SG_ Parken_Aktivierungslicht_Anf  : 36|1@1+ (1.000000,0.000000) [0.000000|1.000000] "" Vector__XXX
 SG_ Parken_Fahrtrichtungslicht_Anf  : 37|2@1+ (1.000000,0.000000) [0.000000|3.000000] "" Vector__XXX
 SG_ Parken_Lichtnachlauf_Anf  : 39|1@1+ (1.000000,0.000000) [0.000000|1.000000] "" Vector__XXX
 SG_ Parken_Fahrerhinweise_Anf  : 51|1@1+ (1.000000,0.000000) [0.000000|1.000000] "" Vector__XXX
 SG_ Parken_Bestaetigungsblinken_Anf  : 52|2@1+ (1.000000,0.000000) [0.000000|3.000000] "" Vector__XXX
 SG_ Parken_Fahrbereitschaftlicht_Anf  : 54|1@1+ (1.000000,0.000000) [0.000000|1.000000] "" Vector__XXX
 SG_ Parken_Lichtsteuerung_Anf  : 55|1@1+ (1.000000,0.000000) [0.000000|1.000000] "" Vector__XXX
 SG_ IPA_Anf_Meldungen  : 56|8@1+ (1.000000,0.000000) [0.000000|255.000000] "" Vector__XXX

BO_ 1813 ISO_Airbag_01_Req: 8 ICAS1_Gateway
 SG_ ISO_Airbag_01_Req_Data  : 0|64@1+ (1.000000,0.000000) [0.000000|18446744073709551616.000000] "" Airbag

BO_ 1919 ISO_Airbag_01_Resp: 8 Airbag
 SG_ ISO_Airbag_01_Resp_Data  : 0|64@1+ (1.000000,0.000000) [0.000000|18446744073709551616.000000] "" ICAS1_Gateway

BO_ 1792 ISO_Funktionaler_Req_All: 8 ICAS1_Gateway
 SG_ ISO_ALL_01_Req_Data  : 0|64@1+ (1.000000,0.000000) [0.000000|18446744073709551616.000000] "" Airbag LE1 LE2 Motor_BEV

BO_ 2621440021 ISOx_Airbag_01_Req_FD: 64 ICAS1_Gateway
 SG_ ISOx_Airbag_01_Req_FD_Data  : 0|512@1+ (1.000000,0.000000) [0.000000|13407807929942597099574024998205846127479365820592393377723561443721764030073546976801874298166903427690031858186486050853753882811946569946433649006084096.000000] "" Airbag

BO_ 2621571093 ISOx_Airbag_01_Resp_FD: 64 Airbag
 SG_ ISOx_Airbag_01_Resp_FD_Data  : 0|512@1+ (1.000000,0.000000) [0.000000|13407807929942597099574024998205846127479365820592393377723561443721764030073546976801874298166903427690031858186486050853753882811946569946433649006084096.000000] "" ICAS1_Gateway

BO_ 2549874812 ISOx_EMotor_01_Req: 8 ICAS1_Gateway
 SG_ ISO_EMotor_01_Req_Data  : 0|64@1+ (1.000000,0.000000) [0.000000|18446744073709551616.000000] "" LE1

BO_ 2621440124 ISOx_EMotor_01_Req_FD: 64 ICAS1_Gateway
 SG_ ISOx_EMotor_01_Req_FD_Data  : 0|512@1+ (1.000000,0.000000) [0.000000|13407807929942597099574024998205846127479365820592393377723561443721764030073546976801874298166903427690031858186486050853753882811946569946433649006084096.000000] "" LE1

BO_ 2550005884 ISOx_EMotor_01_Resp: 8 LE1
 SG_ ISO_EMotor_01_Resp_Data  : 0|64@1+ (1.000000,0.000000) [0.000000|18446744073709551616.000000] "" ICAS1_Gateway

BO_ 2621571196 ISOx_EMotor_01_Resp_FD: 64 LE1
 SG_ ISOx_EMotor_01_Resp_FD_Data  : 0|512@1+ (1.000000,0.000000) [0.000000|13407807929942597099574024998205846127479365820592393377723561443721764030073546976801874298166903427690031858186486050853753882811946569946433649006084096.000000] "" ICAS1_Gateway

BO_ 2549874872 ISOx_EMotor_02_Req: 8 ICAS1_Gateway
 SG_ ISO_EMotor_02_Req_Data  : 0|64@1+ (1.000000,0.000000) [0.000000|18446744073709551616.000000] "" LE2

BO_ 2621440184 ISOx_EMotor_02_Req_FD: 64 ICAS1_Gateway
 SG_ ISOx_EMotor_02_Req_FD_Data  : 0|512@1+ (1.000000,0.000000) [0.000000|13407807929942597099574024998205846127479365820592393377723561443721764030073546976801874298166903427690031858186486050853753882811946569946433649006084096.000000] "" LE2

BO_ 2550005944 ISOx_EMotor_02_Resp: 8 LE2
 SG_ ISO_EMotor_02_Resp_Data  : 0|64@1+ (1.000000,0.000000) [0.000000|18446744073709551616.000000] "" ICAS1_Gateway

BO_ 2621571256 ISOx_EMotor_02_Resp_FD: 64 LE2
 SG_ ISOx_EMotor_02_Resp_FD_Data  : 0|512@1+ (1.000000,0.000000) [0.000000|13407807929942597099574024998205846127479365820592393377723561443721764030073546976801874298166903427690031858186486050853753882811946569946433649006084096.000000] "" ICAS1_Gateway

BO_ 2621505536 ISOx_Funkt_Req_All_FD: 64 ICAS1_Gateway
 SG_ ISOx_Funkt_Req_All_FD_Data  : 0|512@1+ (1.000000,0.000000) [0.000000|13407807929942597099574024998205846127479365820592393377723561443721764030073546976801874298166903427690031858186486050853753882811946569946433649006084096.000000] "" Airbag LE1 LE2 Motor_BEV

BO_ 2549874806 ISOx_MO_01_Req: 8 ICAS1_Gateway
 SG_ ISOx_MO_01_Req_Data  : 0|64@1+ (1.000000,0.000000) [0.000000|18446744073709551616.000000] "" Motor_BEV

BO_ 2621440118 ISOx_MO_01_Req_FD: 64 ICAS1_Gateway
 SG_ ISOx_MO_01_Req_FD_Data  : 0|512@1+ (1.000000,0.000000) [0.000000|13407807929942597099574024998205846127479365820592393377723561443721764030073546976801874298166903427690031858186486050853753882811946569946433649006084096.000000] "" Motor_BEV

BO_ 2550005878 ISOx_MO_01_Resp: 8 Motor_BEV
 SG_ ISOx_MO_01_Resp_Data  : 0|64@1+ (1.000000,0.000000) [0.000000|18446744073709551616.000000] "" ICAS1_Gateway

BO_ 2621571190 ISOx_MO_01_Resp_FD: 64 Motor_BEV
 SG_ ISOx_MO_01_Resp_FD_Data  : 0|512@1+ (1.000000,0.000000) [0.000000|13407807929942597099574024998205846127479365820592393377723561443721764030073546976801874298166903427690031858186486050853753882811946569946433649006084096.000000] "" ICAS1_Gateway

BO_ 2527679684 Kamera_ASM_01: 8 ICAS1_Gateway
 SG_ Kamera_ASM_Ereignis  : 0|8@1+ (1.000000,0.000000) [1.000000|254.000000] "" Airbag
 SG_ Kamera_ASM_Zeitstempel  : 8|8@1+ (0.080000,0.000000) [0.000000|20.320000] "Unit_Secon" Airbag
 SG_ Kamera_ASM_Data_1  : 16|8@1+ (1.000000,0.000000) [0.000000|255.000000] "" Airbag
 SG_ Kamera_ASM_Data_2  : 24|8@1+ (1.000000,0.000000) [0.000000|255.000000] "" Airbag
 SG_ Kamera_ASM_Data_3  : 32|8@1+ (1.000000,0.000000) [0.000000|255.000000] "" Airbag
 SG_ Kamera_ASM_Data_4  : 40|8@1+ (1.000000,0.000000) [0.000000|255.000000] "" Airbag
 SG_ Kamera_ASM_Data_5  : 48|8@1+ (1.000000,0.000000) [0.000000|255.000000] "" Airbag
 SG_ Kamera_ASM_Data_6  : 56|8@1+ (1.000000,0.000000) [0.000000|255.000000] "" Airbag

BO_ 960 Klemmen_Status_01: 4 ICAS1_Gateway
 SG_ Klemmen_Status_01_CRC  : 0|8@1+ (1.000000,0.000000) [0.000000|255.000000] "" Motor_BEV
 SG_ Klemmen_Status_01_BZ  : 8|4@1+ (1.000000,0.000000) [0.000000|15.000000] "" Motor_BEV
 SG_ RSt_Fahrerhinweise  : 12|4@1+ (1.000000,0.000000) [0.000000|15.000000] "" Vector__XXX
 SG_ ZAS_Kl_S  : 16|1@1+ (1.000000,0.000000) [0.000000|1.000000] "" Vector__XXX
 SG_ ZAS_Kl_15  : 17|1@1+ (1.000000,0.000000) [0.000000|1.000000] "" Airbag LE1 LE2 Motor_BEV Schaltbetaetigung
 SG_ ZAS_Kl_X  : 18|1@1+ (1.000000,0.000000) [0.000000|1.000000] "" Vector__XXX
 SG_ ZAS_Kl_50_Startanforderung  : 19|1@1+ (1.000000,0.000000) [0.000000|1.000000] "" Motor_BEV
 SG_ BCM_Remotestart_Betrieb  : 20|1@1+ (1.000000,0.000000) [0.000000|1.000000] "" Vector__XXX
 SG_ ZAS_Kl_Infotainment  : 21|1@1+ (1.000000,0.000000) [0.000000|1.000000] "" Vector__XXX
 SG_ BCM_Remotestart_KL15_Anf  : 22|1@1+ (1.000000,0.000000) [0.000000|1.000000] "" Vector__XXX
 SG_ BCM_Remotestart_MO_Start  : 23|1@1+ (1.000000,0.000000) [0.000000|1.000000] "" Vector__XXX
 SG_ KST_Warn_P1_ZST_def  : 24|1@1+ (1.000000,0.000000) [0.000000|1.000000] "" Vector__XXX
 SG_ KST_Warn_P2_ZST_def  : 25|1@1+ (1.000000,0.000000) [0.000000|1.000000] "" Vector__XXX
 SG_ KST_Fahrerhinweis_1  : 26|1@1+ (1.000000,0.000000) [0.000000|1.000000] "" Vector__XXX
 SG_ KST_Fahrerhinweis_2  : 27|1@1+ (1.000000,0.000000) [0.000000|1.000000] "" Vector__XXX
 SG_ BCM_Ausparken_Betrieb  : 28|1@1+ (1.000000,0.000000) [0.000000|1.000000] "" Vector__XXX
 SG_ KST_Fahrerhinweis_4  : 29|1@1+ (1.000000,0.000000) [0.000000|1.000000] "" Vector__XXX
 SG_ KST_Fahrerhinweis_5  : 30|1@1+ (1.000000,0.000000) [0.000000|1.000000] "" Vector__XXX
 SG_ KST_Fahrerhinweis_6  : 31|1@1+ (1.000000,0.000000) [0.000000|1.000000] "" Vector__XXX

BO_ 2463978753 Klemmen_Status_02: 8 ICAS1_Gateway
 SG_ KST_WFS_Fahrfreigabe_Anforderung  : 12|2@1+ (1.000000,0.000000) [0.000000|3.000000] "" LE1 LE2
 SG_ KST_Sonderzustand_Status  : 14|2@1+ (1.000000,0.000000) [0.000000|3.000000] "" LE1 LE2
 SG_ KST_Sonderzustand_Anforderung  : 16|5@1+ (1.000000,0.000000) [0.000000|31.000000] "" LE1 LE2

BO_ 1420 Klemmen_Steuerung_01: 8 ICAS1_Gateway
 SG_ Klemmen_Steuerung_01_CRC  : 0|8@1+ (1.000000,0.000000) [0.000000|255.000000] "" Vector__XXX
 SG_ Klemmen_Steuerung_01_BZ  : 8|4@1+ (1.000000,0.000000) [0.000000|15.000000] "" Vector__XXX
 SG_ KST_Anf_Klemme_15  : 12|1@1+ (1.000000,0.000000) [0.000000|1.000000] "" Vector__XXX
 SG_ KST_Anf_Klemme_50  : 13|1@1+ (1.000000,0.000000) [0.000000|1.000000] "" Motor_BEV
 SG_ KST_Anf_Klemme_S  : 14|1@1+ (1.000000,0.000000) [0.000000|1.000000] "" Vector__XXX
 SG_ KST_Txt_Werkstatt  : 15|1@1+ (1.000000,0.000000) [0.000000|1.000000] "" Vector__XXX
 SG_ KST_Txt_P_Gang  : 16|1@1+ (1.000000,0.000000) [0.000000|1.000000] "" Vector__XXX
 SG_ KST_Txt_Panikabschaltung  : 17|1@1+ (1.000000,0.000000) [0.000000|1.000000] "" Vector__XXX
 SG_ KST_Anf_Klemmenfreigabe_ELV  : 18|1@1+ (1.000000,0.000000) [0.000000|1.000000] "" Vector__XXX
 SG_ KST_Txt_Komfortabschaltung  : 19|1@1+ (1.000000,0.000000) [0.000000|1.000000] "" Vector__XXX
 SG_ KST_ZAT_betaetigt  : 20|1@1+ (1.000000,0.000000) [0.000000|1.000000] "" Vector__XXX
 SG_ KST_Unterdr_Zuendungsmeldung  : 21|1@1+ (1.000000,0.000000) [0.000000|1.000000] "" Vector__XXX
 SG_ KST_aut_Abschaltung_Zuendung  : 22|1@1+ (1.000000,0.000000) [0.000000|1.000000] "" Vector__XXX
 SG_ KST_Anf_Klemmenfreigabe_WFS  : 23|1@1+ (1.000000,0.000000) [0.000000|1.000000] "" Vector__XXX
 SG_ KST_Anf_ZV_Verriegelung  : 24|1@1+ (1.000000,0.000000) [0.000000|1.000000] "" Vector__XXX
 SG_ Relais_VoKo_angesteuert  : 25|1@1+ (1.000000,0.000000) [0.000000|1.000000] "" Vector__XXX
 SG_ RSt_Anforderung_HMS  : 26|3@1+ (1.000000,0.000000) [0.000000|7.000000] "" Vector__XXX
 SG_ KST_Zuendungswarnung  : 29|2@1+ (1.000000,0.000000) [0.000000|3.000000] "" Vector__XXX
 SG_ KST_Fahrer_Info_Text  : 31|3@1+ (1.000000,0.000000) [0.000000|7.000000] "" Vector__XXX

BO_ 949 Klima_11: 8 ICAS1_Gateway
 SG_ KL_Drehz_Anh  : 0|1@1+ (1.000000,0.000000) [0.000000|1.000000] "" Vector__XXX
 SG_ KL_Vorwarn_Komp_ein  : 1|1@1+ (1.000000,0.000000) [0.000000|1.000000] "" Vector__XXX
 SG_ KL_AC_Schalter  : 2|1@1+ (1.000000,0.000000) [0.000000|1.000000] "" Vector__XXX
 SG_ KL_Komp_Moment_alt  : 3|1@1+ (1.000000,0.000000) [0.000000|1.000000] "" Vector__XXX
 SG_ KL_Vorwarn_Zuheizer_ein  : 6|1@1+ (1.000000,0.000000) [0.000000|1.000000] "" Vector__XXX
 SG_ KL_Zustand  : 7|1@1+ (1.000000,0.000000) [0.000000|1.000000] "" Vector__XXX
 SG_ KL_Kompressorkupplung_linear  : 8|8@1+ (20.000000,0.000000) [0.000000|4000.000000] "Unit_MilliAmper" Vector__XXX
 SG_ KL_Charisma_FahrPr  : 16|4@1+ (1.000000,0.000000) [0.000000|15.000000] "" Vector__XXX
 SG_ KL_Charisma_Status  : 20|2@1+ (1.000000,0.000000) [0.000000|3.000000] "" Vector__XXX
 SG_ KL_nachtr_Stopp_Anf  : 22|1@1+ (1.000000,0.000000) [0.000000|1.000000] "" Vector__XXX
 SG_ KL_T_Charge  : 23|1@1+ (1.000000,0.000000) [0.000000|1.000000] "" Vector__XXX
 SG_ KL_Last_Kompr  : 24|8@1+ (0.250000,0.000000) [0.000000|63.500000] "Unit_NewtoMeter" Vector__XXX
 SG_ KL_Spannungs_Anf  : 32|2@1+ (1.000000,0.000000) [0.000000|3.000000] "" Vector__XXX
 SG_ KL_Thermomanagement  : 34|2@1+ (1.000000,0.000000) [0.000000|3.000000] "" Motor_BEV
 SG_ KL_StartStopp_Info  : 36|2@1+ (1.000000,0.000000) [0.000000|3.000000] "" Vector__XXX
 SG_ KL_Freilauf_Info  : 38|2@1+ (1.000000,0.000000) [0.000000|3.000000] "" Vector__XXX
 SG_ KL_Anf_KL  : 40|8@1+ (0.400000,0.000000) [0.000000|101.600000] "Unit_PerCent" Motor_BEV
 SG_ KL_el_Zuheizer_Stufe  : 48|3@1+ (1.000000,0.000000) [0.000000|7.000000] "" Vector__XXX
 SG_ KL_Ausstattung_Klima  : 51|3@1+ (1.000000,0.000000) [0.000000|7.000000] "" Vector__XXX
 SG_ KL_Variante_Standheizung  : 54|2@1+ (1.000000,0.000000) [0.000000|3.000000] "" Vector__XXX
 SG_ KL_Anf_KV  : 57|7@1+ (1.000000,0.000000) [0.000000|100.000000] "Unit_PerCent" Motor_BEV

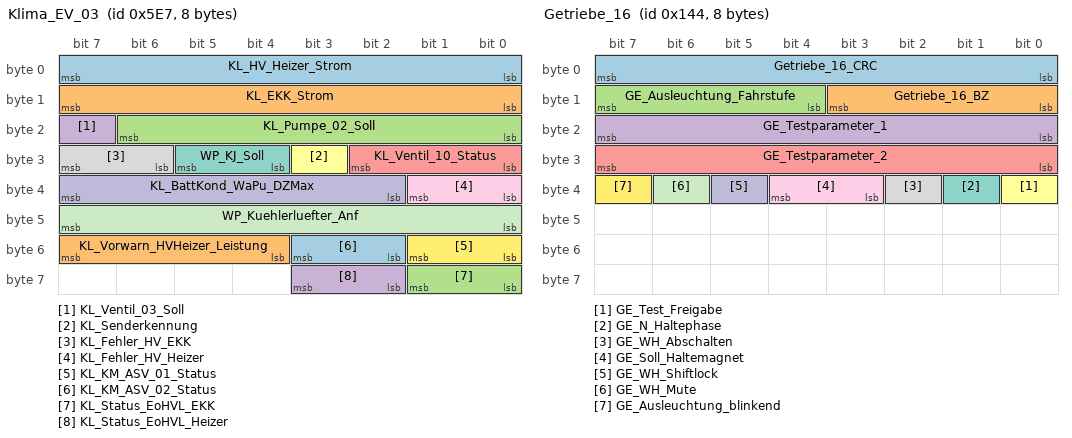
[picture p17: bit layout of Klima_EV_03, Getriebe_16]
BO_ 1511 Klima_EV_03: 8 ICAS1_Gateway
 SG_ KL_HV_Heizer_Strom  : 0|8@1+ (0.250000,0.000000) [0.000000|63.500000] "Unit_Amper" Motor_BEV
 SG_ KL_EKK_Strom  : 8|8@1+ (0.250000,0.000000) [0.000000|63.500000] "Unit_Amper" Motor_BEV
 SG_ KL_Pumpe_02_Soll  : 16|7@1+ (1.000000,0.000000) [0.000000|100.000000] "Unit_PerCent" Motor_BEV
 SG_ KL_Ventil_03_Soll  : 23|1@1+ (1.000000,0.000000) [0.000000|1.000000] "" Vector__XXX
 SG_ KL_Ventil_10_Status  : 24|3@1+ (1.000000,0.000000) [0.000000|7.000000] "" Vector__XXX
 SG_ KL_Senderkennung  : 27|1@1+ (1.000000,0.000000) [0.000000|1.000000] "" Vector__XXX
 SG_ WP_KJ_Soll  : 28|2@1+ (1.000000,0.000000) [0.000000|3.000000] "" Vector__XXX
 SG_ KL_Fehler_HV_EKK  : 30|2@1+ (1.000000,0.000000) [0.000000|3.000000] "" Vector__XXX
 SG_ KL_Fehler_HV_Heizer  : 32|2@1+ (1.000000,0.000000) [0.000000|3.000000] "" Vector__XXX
 SG_ KL_BattKond_WaPu_DZMax  : 34|6@1+ (2.000000,0.000000) [0.000000|100.000000] "Unit_PerCent" Vector__XXX
 SG_ WP_Kuehlerluefter_Anf  : 40|8@1+ (0.400000,0.000000) [0.000000|101.600000] "Unit_PerCent" Vector__XXX
 SG_ KL_KM_ASV_01_Status  : 48|2@1+ (1.000000,0.000000) [0.000000|3.000000] "" Vector__XXX
 SG_ KL_KM_ASV_02_Status  : 50|2@1+ (1.000000,0.000000) [0.000000|3.000000] "" Vector__XXX
 SG_ KL_Vorwarn_HVHeizer_Leistung  : 52|4@1+ (1.000000,0.000000) [0.000000|15.000000] "" Vector__XXX
 SG_ KL_Status_EoHVL_EKK  : 56|2@1+ (1.000000,0.000000) [0.000000|3.000000] "" Motor_BEV
 SG_ KL_Status_EoHVL_Heizer  : 58|2@1+ (1.000000,0.000000) [0.000000|3.000000] "" Motor_BEV

BU_:  Airbag BAP_Tester ICAS1_Gateway ICAS1_KommunikationsServer LE1 LE2 Motor_BEV Schaltbetaetigung

BO_ 324 Getriebe_16: 8 Motor_BEV
 SG_ Getriebe_16_CRC  : 0|8@1+ (1.000000,0.000000) [0.000000|255.000000] "" ICAS1_Gateway Schaltbetaetigung
 SG_ Getriebe_16_BZ  : 8|4@1+ (1.000000,0.000000) [0.000000|15.000000] "" ICAS1_Gateway Schaltbetaetigung
 SG_ GE_Ausleuchtung_Fahrstufe  : 12|4@1+ (1.000000,0.000000) [0.000000|15.000000] "" ICAS1_Gateway Schaltbetaetigung
 SG_ GE_Testparameter_1  : 16|8@1+ (1.000000,0.000000) [0.000000|255.000000] "" ICAS1_Gateway Schaltbetaetigung
 SG_ GE_Testparameter_2  : 24|8@1+ (1.000000,0.000000) [0.000000|255.000000] "" ICAS1_Gateway Schaltbetaetigung
 SG_ GE_Test_Freigabe  : 32|1@1+ (1.000000,0.000000) [0.000000|1.000000] "" ICAS1_Gateway Schaltbetaetigung
 SG_ GE_N_Haltephase  : 33|1@1+ (1.000000,0.000000) [0.000000|1.000000] "" ICAS1_Gateway Schaltbetaetigung
 SG_ GE_WH_Abschalten  : 34|1@1+ (1.000000,0.000000) [0.000000|1.000000] "" ICAS1_Gateway Schaltbetaetigung
 SG_ GE_Soll_Haltemagnet  : 35|2@1+ (1.000000,0.000000) [0.000000|3.000000] "" ICAS1_Gateway Schaltbetaetigung
 SG_ GE_WH_Shiftlock  : 37|1@1+ (1.000000,0.000000) [0.000000|1.000000] "" ICAS1_Gateway Schaltbetaetigung
 SG_ GE_WH_Mute  : 38|1@1+ (1.000000,0.000000) [0.000000|1.000000] "" ICAS1_Gateway Schaltbetaetigung
 SG_ GE_Ausleuchtung_blinkend  : 39|1@1+ (1.000000,0.000000) [0.000000|1.000000] "" ICAS1_Gateway Schaltbetaetigung

BO_ 299 GRA_ACC_01: 8 ICAS1_Gateway
 SG_ GRA_ACC_01_CRC  : 0|8@1+ (1.000000,0.000000) [0.000000|255.000000] "" Motor_BEV
 SG_ GRA_ACC_01_BZ  : 8|4@1+ (1.000000,0.000000) [0.000000|15.000000] "" Motor_BEV
 SG_ GRA_Hauptschalter  : 12|1@1+ (1.000000,0.000000) [0.000000|1.000000] "" Motor_BEV
 SG_ GRA_Abbrechen  : 13|1@1+ (1.000000,0.000000) [0.000000|1.000000] "" Motor_BEV
 SG_ GRA_Typ_Hauptschalter  : 14|1@1+ (1.000000,0.000000) [0.000000|1.000000] "" Motor_BEV
 SG_ GRA_Limiter  : 15|1@1+ (1.000000,0.000000) [0.000000|1.000000] "" Motor_BEV
 SG_ GRA_Tip_Setzen  : 16|1@1+ (1.000000,0.000000) [0.000000|1.000000] "" Motor_BEV
 SG_ GRA_Tip_Hoch  : 17|1@1+ (1.000000,0.000000) [0.000000|1.000000] "" Motor_BEV
 SG_ GRA_Tip_Runter  : 18|1@1+ (1.000000,0.000000) [0.000000|1.000000] "" Motor_BEV
 SG_ GRA_Tip_Wiederaufnahme  : 19|1@1+ (1.000000,0.000000) [0.000000|1.000000] "" Motor_BEV
 SG_ GRA_Verstellung_Zeitluecke  : 20|2@1+ (1.000000,0.000000) [0.000000|3.000000] "" Vector__XXX
 SG_ GRA_Codierung  : 22|2@1+ (1.000000,0.000000) [0.000000|3.000000] "" Motor_BEV
 SG_ GRA_Fehler  : 24|1@1+ (1.000000,0.000000) [0.000000|1.000000] "" Motor_BEV
 SG_ GRA_LIM_Taste_verfuegbar  : 25|1@1+ (1.000000,0.000000) [0.000000|1.000000] "" Motor_BEV
 SG_ GRA_Tip_Stufe_2  : 26|1@1+ (1.000000,0.000000) [0.000000|1.000000] "" Motor_BEV
 SG_ GRA_Typ_Bedienteil  : 27|3@1+ (1.000000,0.000000) [0.000000|7.000000] "" Motor_BEV
 SG_ GRA_TravelAssist  : 30|1@1+ (1.000000,0.000000) [0.000000|1.000000] "" Vector__XXX
 SG_ GRA_reserveByte4  : 31|1@1+ (1.000000,0.000000) [0.000000|1.000000] "" Vector__XXX
 SG_ GRA_reserveByte5  : 32|8@1+ (1.000000,0.000000) [0.000000|255.000000] "" Vector__XXX
 SG_ GRA_reserveByte6  : 40|8@1+ (1.000000,0.000000) [0.000000|255.000000] "" Vector__XXX
 SG_ GRA_reserveByte7  : 48|8@1+ (1.000000,0.000000) [0.000000|255.000000] "" Vector__XXX
 SG_ GRA_reserveByte8  : 56|8@1+ (1.000000,0.000000) [0.000000|255.000000] "" Vector__XXX

BO_ 1452 HVEM_02: 8 ICAS1_Gateway
 SG_ HVEM_IstStrom_HVVerbraucher  : 0|12@1+ (0.100000,-204.700000) [-204.700000|204.600000] "Unit_Amper" Vector__XXX
 SG_ HVEM_Energie_Klima_Vorgabe_HighR  : 12|3@1+ (10.000000,0.000000) [0.000000|50.000000] "Unit_WattHour" Vector__XXX
 SG_ HVEM_IstLeistungNA  : 15|9@1+ (50.000000,0.000000) [0.000000|25450.000000] "Unit_Watt" Motor_BEV
 SG_ HVEM_Leistung_Klima_Vorgabe  : 24|8@1+ (50.000000,0.000000) [0.000000|12650.000000] "Unit_Watt" Vector__XXX
 SG_ HVEM_Nutzbare_Energie  : 32|11@1+ (50.000000,0.000000) [0.000000|102200.000000] "Unit_WattHour" Vector__XXX
 SG_ HVEM_Energie_Klima_Vorgabe  : 43|8@1+ (50.000000,0.000000) [0.000000|12650.000000] "Unit_WattHour" Vector__XXX
 SG_ HVEM_HVK_Aktivitaet  : 51|2@1+ (1.000000,0.000000) [0.000000|3.000000] "" Motor_BEV
 SG_ HVEM_Pruefpuls_Anf  : 53|2@1+ (1.000000,0.000000) [0.000000|3.000000] "" Motor_BEV
 SG_ HVEM_HV_Anf  : 62|1@1+ (1.000000,0.000000) [0.000000|1.000000] "" Motor_BEV
 SG_ HVEM_MO_MaxLeistungIgnoriert  : 63|1@1+ (1.000000,0.000000) [0.000000|1.000000] "" Vector__XXX

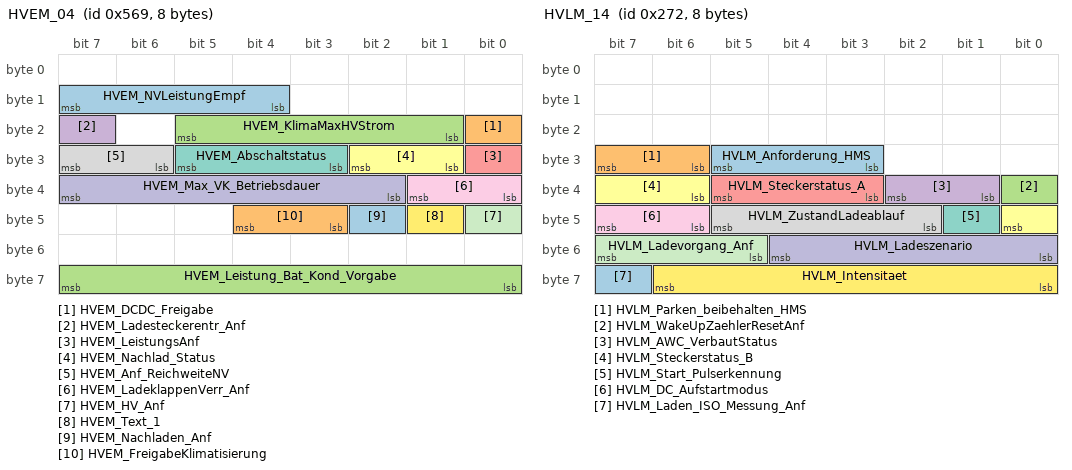
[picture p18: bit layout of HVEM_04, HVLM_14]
BO_ 1385 HVEM_04: 8 ICAS1_Gateway
 SG_ HVEM_NVLeistungEmpf  : 12|4@1+ (100.000000,0.000000) [0.000000|1500.000000] "Unit_Watt" Vector__XXX
 SG_ HVEM_DCDC_Freigabe  : 16|1@1+ (1.000000,0.000000) [0.000000|1.000000] "" Motor_BEV
 SG_ HVEM_KlimaMaxHVStrom  : 17|5@1+ (1.000000,0.000000) [0.000000|31.000000] "Unit_Amper" Vector__XXX
 SG_ HVEM_Ladesteckerentr_Anf  : 23|1@1+ (1.000000,0.000000) [0.000000|1.000000] "" Vector__XXX
 SG_ HVEM_LeistungsAnf  : 24|1@1+ (1.000000,0.000000) [0.000000|1.000000] "" Vector__XXX
 SG_ HVEM_Nachlad_Status  : 25|2@1+ (1.000000,0.000000) [0.000000|3.000000] "" Vector__XXX
 SG_ HVEM_Abschaltstatus  : 27|3@1+ (1.000000,0.000000) [0.000000|7.000000] "" Vector__XXX
 SG_ HVEM_Anf_ReichweiteNV  : 30|2@1+ (1.000000,0.000000) [0.000000|3.000000] "" Vector__XXX
 SG_ HVEM_LadeklappenVerr_Anf  : 32|2@1+ (1.000000,0.000000) [0.000000|3.000000] "" Vector__XXX
 SG_ HVEM_Max_VK_Betriebsdauer  : 34|6@1+ (1.000000,0.000000) [0.000000|60.000000] "Unit_Minut" Vector__XXX
 SG_ HVEM_HV_Anf  : 40|1@1+ (1.000000,0.000000) [0.000000|1.000000] "" Vector__XXX
 SG_ HVEM_Text_1  : 41|1@1+ (1.000000,0.000000) [0.000000|1.000000] "" Vector__XXX
 SG_ HVEM_Nachladen_Anf  : 42|1@1+ (1.000000,0.000000) [0.000000|1.000000] "" Vector__XXX
 SG_ HVEM_FreigabeKlimatisierung  : 43|2@1+ (1.000000,0.000000) [0.000000|3.000000] "" Vector__XXX
 SG_ HVEM_Leistung_Bat_Kond_Vorgabe  : 56|8@1+ (50.000000,0.000000) [0.000000|12650.000000] "Unit_Watt" Vector__XXX

BO_ 1283 HVK_01: 8 Motor_BEV
 SG_ HVK_01_CRC  : 0|8@1+ (1.000000,0.000000) [0.000000|255.000000] "" ICAS1_Gateway LE1 LE2
 SG_ HVK_01_BZ  : 8|4@1+ (1.000000,0.000000) [0.000000|15.000000] "" ICAS1_Gateway LE1 LE2
 SG_ HVK_Istmodus_Anf  : 12|1@1+ (1.000000,0.000000) [0.000000|1.000000] "" ICAS1_Gateway
 SG_ HVK_TN1_Sollmodus  : 13|2@1+ (1.000000,0.000000) [0.000000|3.000000] "" ICAS1_Gateway
 SG_ HVK_Vorladung_aktiv  : 15|1@1+ (1.000000,0.000000) [0.000000|1.000000] "" ICAS1_Gateway
 SG_ HVK_BMS_Sollmodus  : 24|3@1+ (1.000000,0.000000) [0.000000|7.000000] "" ICAS1_Gateway
 SG_ HVK_DCDC_Sollmodus  : 27|3@1+ (1.000000,0.000000) [0.000000|7.000000] "" ICAS1_Gateway
 SG_ HVK_EKK_Sollmodus  : 30|3@1+ (1.000000,0.000000) [0.000000|7.000000] "" ICAS1_Gateway
 SG_ HVK_HVPTC_Sollmodus  : 33|3@1+ (1.000000,0.000000) [0.000000|7.000000] "" ICAS1_Gateway
 SG_ HVK_HVLM_Sollmodus  : 36|3@1+ (1.000000,0.000000) [0.000000|7.000000] "" ICAS1_Gateway
 SG_ HVK_HV_Netz_Warnungen  : 39|2@1+ (1.000000,0.000000) [0.000000|3.000000] "" ICAS1_Gateway ICAS1_KommunikationsServer
 SG_ HV_Bordnetz_aktiv  : 41|1@1+ (1.000000,0.000000) [0.000000|1.000000] "" ICAS1_Gateway LE1 LE2
 SG_ HV_Bordnetz_Fehler  : 42|1@1+ (1.000000,0.000000) [0.000000|1.000000] "" ICAS1_Gateway
 SG_ HVK_Gesamtst_Spgfreiheit  : 43|2@1+ (1.000000,0.000000) [0.000000|3.000000] "" ICAS1_Gateway ICAS1_KommunikationsServer
 SG_ HVK_AktiveEntladung_Anf  : 45|1@1+ (1.000000,0.000000) [0.000000|1.000000] "" ICAS1_Gateway LE1 LE2
 SG_ HVK_HVEM_Freigabe  : 46|2@1+ (1.000000,0.000000) [0.000000|3.000000] "" ICAS1_Gateway
 SG_ HVK_Notentladung_Anf  : 48|2@1+ (1.000000,0.000000) [0.000000|3.000000] "" ICAS1_Gateway LE1 LE2
 SG_ HVK_Iso_Messung_Start  : 50|3@1+ (1.000000,0.000000) [0.000000|7.000000] "" ICAS1_Gateway
 SG_ HVK_Ladebereit  : 53|3@1+ (1.000000,0.000000) [0.000000|7.000000] "" ICAS1_Gateway
 SG_ HVK_PPulsFreigabe  : 56|2@1+ (1.000000,0.000000) [0.000000|3.000000] "" ICAS1_Gateway

BO_ 2463978813 HVL_01: 8 ICAS1_Gateway
 SG_ HVL_01_CRC  : 0|8@1+ (1.000000,0.000000) [0.000000|255.000000] "" Motor_BEV
 SG_ HVL_01_BZ  : 8|4@1+ (1.000000,0.000000) [0.000000|15.000000] "" Motor_BEV
 SG_ HVL_Steckerstatus  : 12|2@1+ (1.000000,0.000000) [0.000000|3.000000] "" Motor_BEV
 SG_ HVL_LadeAnforderung  : 24|3@1+ (1.000000,0.000000) [0.000000|7.000000] "" Motor_BEV

BO_ 626 HVLM_14: 8 ICAS1_Gateway
 SG_ HVLM_Anforderung_HMS  : 27|3@1+ (1.000000,0.000000) [0.000000|7.000000] "" Vector__XXX
 SG_ HVLM_Parken_beibehalten_HMS  : 30|2@1+ (1.000000,0.000000) [0.000000|3.000000] "" Vector__XXX
 SG_ HVLM_WakeUpZaehlerResetAnf  : 32|1@1+ (1.000000,0.000000) [0.000000|1.000000] "" Vector__XXX
 SG_ HVLM_AWC_VerbautStatus  : 33|2@1+ (1.000000,0.000000) [0.000000|3.000000] "" Motor_BEV
 SG_ HVLM_Steckerstatus_A  : 35|3@1+ (1.000000,0.000000) [0.000000|7.000000] "" Motor_BEV
 SG_ HVLM_Steckerstatus_B  : 38|3@1+ (1.000000,0.000000) [0.000000|7.000000] "" Vector__XXX
 SG_ HVLM_Start_Pulserkennung  : 41|1@1+ (1.000000,0.000000) [0.000000|1.000000] "" Vector__XXX
 SG_ HVLM_ZustandLadeablauf  : 42|4@1+ (1.000000,0.000000) [0.000000|15.000000] "" Motor_BEV
 SG_ HVLM_DC_Aufstartmodus  : 46|2@1+ (1.000000,0.000000) [0.000000|3.000000] "" Motor_BEV
 SG_ HVLM_Ladeszenario  : 48|5@1+ (1.000000,0.000000) [0.000000|31.000000] "" Vector__XXX
 SG_ HVLM_Ladevorgang_Anf  : 53|3@1+ (1.000000,0.000000) [0.000000|7.000000] "" Motor_BEV
 SG_ HVLM_Intensitaet  : 56|7@1+ (1.000000,0.000000) [0.000000|100.000000] "Unit_PerCent" Vector__XXX
 SG_ HVLM_Laden_ISO_Messung_Anf  : 63|1@1+ (1.000000,0.000000) [0.000000|1.000000] "" Motor_BEV

BO_ 268 IMMO_CORD_01: 8 Motor_BEV
 SG_ ImoCord_Auth_Aufforderung_WFS  : 63|1@1+ (1.000000,0.000000) [0.000000|1.000000] "" LE1 LE2

BO_ 23 IMMO_MSG3_Antwort: 8 ICAS1_Gateway
 SG_ WFS_IMMO_MSG3_CRC  : 0|32@1+ (1.000000,0.000000) [0.000000|4294967295.000000] "" LE2
 SG_ WFS_IMMO_MSG3_Status  : 56|8@1+ (1.000000,0.000000) [0.000000|255.000000] "" LE2

BO_ 25 IMMO_MSG4_Antwort: 8 ICAS1_Gateway
 SG_ WFS_IMMO_MSG4_CRC  : 0|32@1+ (1.000000,0.000000) [0.000000|4294967295.000000] "" LE1
 SG_ WFS_IMMO_MSG4_Status  : 56|8@1+ (1.000000,0.000000) [0.000000|255.000000] "" LE1

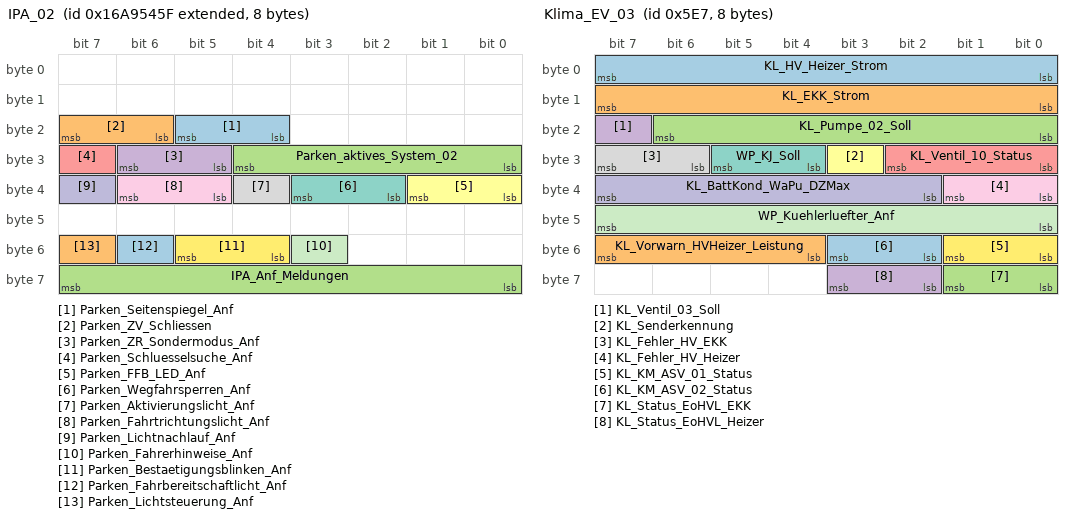
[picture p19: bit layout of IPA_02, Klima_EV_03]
BO_ 2527679583 IPA_02: 8 ICAS1_Gateway
 SG_ Parken_Seitenspiegel_Anf  : 20|2@1+ (1.000000,0.000000) [0.000000|3.000000] "" Vector__XXX
 SG_ Parken_ZV_Schliessen  : 22|2@1+ (1.000000,0.000000) [0.000000|3.000000] "" Vector__XXX
 SG_ Parken_aktives_System_02  : 24|5@1+ (1.000000,0.000000) [0.000000|31.000000] "" Vector__XXX
 SG_ Parken_ZR_Sondermodus_Anf  : 29|2@1+ (1.000000,0.000000) [0.000000|3.000000] "" Vector__XXX
 SG_ Parken_Schluesselsuche_Anf  : 31|1@1+ (1.000000,0.000000) [0.000000|1.000000] "" Vector__XXX
 SG_ Parken_FFB_LED_Anf  : 32|2@1+ (1.000000,0.000000) [0.000000|3.000000] "" Vector__XXX
 SG_ Parken_Wegfahrsperren_Anf  : 34|2@1+ (1.000000,0.000000) [0.000000|3.000000] "" LE1 LE2
 SG_ Parken_Aktivierungslicht_Anf  : 36|1@1+ (1.000000,0.000000) [0.000000|1.000000] "" Vector__XXX
 SG_ Parken_Fahrtrichtungslicht_Anf  : 37|2@1+ (1.000000,0.000000) [0.000000|3.000000] "" Vector__XXX
 SG_ Parken_Lichtnachlauf_Anf  : 39|1@1+ (1.000000,0.000000) [0.000000|1.000000] "" Vector__XXX
 SG_ Parken_Fahrerhinweise_Anf  : 51|1@1+ (1.000000,0.000000) [0.000000|1.000000] "" Vector__XXX
 SG_ Parken_Bestaetigungsblinken_Anf  : 52|2@1+ (1.000000,0.000000) [0.000000|3.000000] "" Vector__XXX
 SG_ Parken_Fahrbereitschaftlicht_Anf  : 54|1@1+ (1.000000,0.000000) [0.000000|1.000000] "" Vector__XXX
 SG_ Parken_Lichtsteuerung_Anf  : 55|1@1+ (1.000000,0.000000) [0.000000|1.000000] "" Vector__XXX
 SG_ IPA_Anf_Meldungen  : 56|8@1+ (1.000000,0.000000) [0.000000|255.000000] "" Vector__XXX

BO_ 1813 ISO_Airbag_01_Req: 8 ICAS1_Gateway
 SG_ ISO_Airbag_01_Req_Data  : 0|64@1+ (1.000000,0.000000) [0.000000|18446744073709551616.000000] "" Airbag

BO_ 1919 ISO_Airbag_01_Resp: 8 Airbag
 SG_ ISO_Airbag_01_Resp_Data  : 0|64@1+ (1.000000,0.000000) [0.000000|18446744073709551616.000000] "" ICAS1_Gateway

BO_ 1792 ISO_Funktionaler_Req_All: 8 ICAS1_Gateway
 SG_ ISO_ALL_01_Req_Data  : 0|64@1+ (1.000000,0.000000) [0.000000|18446744073709551616.000000] "" Airbag LE1 LE2 Motor_BEV

BO_ 2621440021 ISOx_Airbag_01_Req_FD: 64 ICAS1_Gateway
 SG_ ISOx_Airbag_01_Req_FD_Data  : 0|512@1+ (1.000000,0.000000) [0.000000|13407807929942597099574024998205846127479365820592393377723561443721764030073546976801874298166903427690031858186486050853753882811946569946433649006084096.000000] "" Airbag

BO_ 2621571093 ISOx_Airbag_01_Resp_FD: 64 Airbag
 SG_ ISOx_Airbag_01_Resp_FD_Data  : 0|512@1+ (1.000000,0.000000) [0.000000|13407807929942597099574024998205846127479365820592393377723561443721764030073546976801874298166903427690031858186486050853753882811946569946433649006084096.000000] "" ICAS1_Gateway

BO_ 2549874812 ISOx_EMotor_01_Req: 8 ICAS1_Gateway
 SG_ ISO_EMotor_01_Req_Data  : 0|64@1+ (1.000000,0.000000) [0.000000|18446744073709551616.000000] "" LE1

BO_ 2621440124 ISOx_EMotor_01_Req_FD: 64 ICAS1_Gateway
 SG_ ISOx_EMotor_01_Req_FD_Data  : 0|512@1+ (1.000000,0.000000) [0.000000|13407807929942597099574024998205846127479365820592393377723561443721764030073546976801874298166903427690031858186486050853753882811946569946433649006084096.000000] "" LE1

BO_ 2550005884 ISOx_EMotor_01_Resp: 8 LE1
 SG_ ISO_EMotor_01_Resp_Data  : 0|64@1+ (1.000000,0.000000) [0.000000|18446744073709551616.000000] "" ICAS1_Gateway

BO_ 2621571196 ISOx_EMotor_01_Resp_FD: 64 LE1
 SG_ ISOx_EMotor_01_Resp_FD_Data  : 0|512@1+ (1.000000,0.000000) [0.000000|13407807929942597099574024998205846127479365820592393377723561443721764030073546976801874298166903427690031858186486050853753882811946569946433649006084096.000000] "" ICAS1_Gateway

BO_ 2549874872 ISOx_EMotor_02_Req: 8 ICAS1_Gateway
 SG_ ISO_EMotor_02_Req_Data  : 0|64@1+ (1.000000,0.000000) [0.000000|18446744073709551616.000000] "" LE2

BO_ 2621440184 ISOx_EMotor_02_Req_FD: 64 ICAS1_Gateway
 SG_ ISOx_EMotor_02_Req_FD_Data  : 0|512@1+ (1.000000,0.000000) [0.000000|13407807929942597099574024998205846127479365820592393377723561443721764030073546976801874298166903427690031858186486050853753882811946569946433649006084096.000000] "" LE2

BO_ 2550005944 ISOx_EMotor_02_Resp: 8 LE2
 SG_ ISO_EMotor_02_Resp_Data  : 0|64@1+ (1.000000,0.000000) [0.000000|18446744073709551616.000000] "" ICAS1_Gateway

BO_ 2621571256 ISOx_EMotor_02_Resp_FD: 64 LE2
 SG_ ISOx_EMotor_02_Resp_FD_Data  : 0|512@1+ (1.000000,0.000000) [0.000000|13407807929942597099574024998205846127479365820592393377723561443721764030073546976801874298166903427690031858186486050853753882811946569946433649006084096.000000] "" ICAS1_Gateway

BO_ 2621505536 ISOx_Funkt_Req_All_FD: 64 ICAS1_Gateway
 SG_ ISOx_Funkt_Req_All_FD_Data  : 0|512@1+ (1.000000,0.000000) [0.000000|13407807929942597099574024998205846127479365820592393377723561443721764030073546976801874298166903427690031858186486050853753882811946569946433649006084096.000000] "" Airbag LE1 LE2 Motor_BEV

BO_ 2549874806 ISOx_MO_01_Req: 8 ICAS1_Gateway
 SG_ ISOx_MO_01_Req_Data  : 0|64@1+ (1.000000,0.000000) [0.000000|18446744073709551616.000000] "" Motor_BEV

BO_ 2621440118 ISOx_MO_01_Req_FD: 64 ICAS1_Gateway
 SG_ ISOx_MO_01_Req_FD_Data  : 0|512@1+ (1.000000,0.000000) [0.000000|13407807929942597099574024998205846127479365820592393377723561443721764030073546976801874298166903427690031858186486050853753882811946569946433649006084096.000000] "" Motor_BEV

BO_ 2550005878 ISOx_MO_01_Resp: 8 Motor_BEV
 SG_ ISOx_MO_01_Resp_Data  : 0|64@1+ (1.000000,0.000000) [0.000000|18446744073709551616.000000] "" ICAS1_Gateway

BO_ 2621571190 ISOx_MO_01_Resp_FD: 64 Motor_BEV
 SG_ ISOx_MO_01_Resp_FD_Data  : 0|512@1+ (1.000000,0.000000) [0.000000|13407807929942597099574024998205846127479365820592393377723561443721764030073546976801874298166903427690031858186486050853753882811946569946433649006084096.000000] "" ICAS1_Gateway

BO_ 2527679684 Kamera_ASM_01: 8 ICAS1_Gateway
 SG_ Kamera_ASM_Ereignis  : 0|8@1+ (1.000000,0.000000) [1.000000|254.000000] "" Airbag
 SG_ Kamera_ASM_Zeitstempel  : 8|8@1+ (0.080000,0.000000) [0.000000|20.320000] "Unit_Secon" Airbag
 SG_ Kamera_ASM_Data_1  : 16|8@1+ (1.000000,0.000000) [0.000000|255.000000] "" Airbag
 SG_ Kamera_ASM_Data_2  : 24|8@1+ (1.000000,0.000000) [0.000000|255.000000] "" Airbag
 SG_ Kamera_ASM_Data_3  : 32|8@1+ (1.000000,0.000000) [0.000000|255.000000] "" Airbag
 SG_ Kamera_ASM_Data_4  : 40|8@1+ (1.000000,0.000000) [0.000000|255.000000] "" Airbag
 SG_ Kamera_ASM_Data_5  : 48|8@1+ (1.000000,0.000000) [0.000000|255.000000] "" Airbag
 SG_ Kamera_ASM_Data_6  : 56|8@1+ (1.000000,0.000000) [0.000000|255.000000] "" Airbag

BO_ 960 Klemmen_Status_01: 4 ICAS1_Gateway
 SG_ Klemmen_Status_01_CRC  : 0|8@1+ (1.000000,0.000000) [0.000000|255.000000] "" Motor_BEV
 SG_ Klemmen_Status_01_BZ  : 8|4@1+ (1.000000,0.000000) [0.000000|15.000000] "" Motor_BEV
 SG_ RSt_Fahrerhinweise  : 12|4@1+ (1.000000,0.000000) [0.000000|15.000000] "" Vector__XXX
 SG_ ZAS_Kl_S  : 16|1@1+ (1.000000,0.000000) [0.000000|1.000000] "" Vector__XXX
 SG_ ZAS_Kl_15  : 17|1@1+ (1.000000,0.000000) [0.000000|1.000000] "" Airbag LE1 LE2 Motor_BEV Schaltbetaetigung
 SG_ ZAS_Kl_X  : 18|1@1+ (1.000000,0.000000) [0.000000|1.000000] "" Vector__XXX
 SG_ ZAS_Kl_50_Startanforderung  : 19|1@1+ (1.000000,0.000000) [0.000000|1.000000] "" Motor_BEV
 SG_ BCM_Remotestart_Betrieb  : 20|1@1+ (1.000000,0.000000) [0.000000|1.000000] "" Vector__XXX
 SG_ ZAS_Kl_Infotainment  : 21|1@1+ (1.000000,0.000000) [0.000000|1.000000] "" Vector__XXX
 SG_ BCM_Remotestart_KL15_Anf  : 22|1@1+ (1.000000,0.000000) [0.000000|1.000000] "" Vector__XXX
 SG_ BCM_Remotestart_MO_Start  : 23|1@1+ (1.000000,0.000000) [0.000000|1.000000] "" Vector__XXX
 SG_ KST_Warn_P1_ZST_def  : 24|1@1+ (1.000000,0.000000) [0.000000|1.000000] "" Vector__XXX
 SG_ KST_Warn_P2_ZST_def  : 25|1@1+ (1.000000,0.000000) [0.000000|1.000000] "" Vector__XXX
 SG_ KST_Fahrerhinweis_1  : 26|1@1+ (1.000000,0.000000) [0.000000|1.000000] "" Vector__XXX
 SG_ KST_Fahrerhinweis_2  : 27|1@1+ (1.000000,0.000000) [0.000000|1.000000] "" Vector__XXX
 SG_ BCM_Ausparken_Betrieb  : 28|1@1+ (1.000000,0.000000) [0.000000|1.000000] "" Vector__XXX
 SG_ KST_Fahrerhinweis_4  : 29|1@1+ (1.000000,0.000000) [0.000000|1.000000] "" Vector__XXX
 SG_ KST_Fahrerhinweis_5  : 30|1@1+ (1.000000,0.000000) [0.000000|1.000000] "" Vector__XXX
 SG_ KST_Fahrerhinweis_6  : 31|1@1+ (1.000000,0.000000) [0.000000|1.000000] "" Vector__XXX

BO_ 2463978753 Klemmen_Status_02: 8 ICAS1_Gateway
 SG_ KST_WFS_Fahrfreigabe_Anforderung  : 12|2@1+ (1.000000,0.000000) [0.000000|3.000000] "" LE1 LE2
 SG_ KST_Sonderzustand_Status  : 14|2@1+ (1.000000,0.000000) [0.000000|3.000000] "" LE1 LE2
 SG_ KST_Sonderzustand_Anforderung  : 16|5@1+ (1.000000,0.000000) [0.000000|31.000000] "" LE1 LE2

BO_ 1420 Klemmen_Steuerung_01: 8 ICAS1_Gateway
 SG_ Klemmen_Steuerung_01_CRC  : 0|8@1+ (1.000000,0.000000) [0.000000|255.000000] "" Vector__XXX
 SG_ Klemmen_Steuerung_01_BZ  : 8|4@1+ (1.000000,0.000000) [0.000000|15.000000] "" Vector__XXX
 SG_ KST_Anf_Klemme_15  : 12|1@1+ (1.000000,0.000000) [0.000000|1.000000] "" Vector__XXX
 SG_ KST_Anf_Klemme_50  : 13|1@1+ (1.000000,0.000000) [0.000000|1.000000] "" Motor_BEV
 SG_ KST_Anf_Klemme_S  : 14|1@1+ (1.000000,0.000000) [0.000000|1.000000] "" Vector__XXX
 SG_ KST_Txt_Werkstatt  : 15|1@1+ (1.000000,0.000000) [0.000000|1.000000] "" Vector__XXX
 SG_ KST_Txt_P_Gang  : 16|1@1+ (1.000000,0.000000) [0.000000|1.000000] "" Vector__XXX
 SG_ KST_Txt_Panikabschaltung  : 17|1@1+ (1.000000,0.000000) [0.000000|1.000000] "" Vector__XXX
 SG_ KST_Anf_Klemmenfreigabe_ELV  : 18|1@1+ (1.000000,0.000000) [0.000000|1.000000] "" Vector__XXX
 SG_ KST_Txt_Komfortabschaltung  : 19|1@1+ (1.000000,0.000000) [0.000000|1.000000] "" Vector__XXX
 SG_ KST_ZAT_betaetigt  : 20|1@1+ (1.000000,0.000000) [0.000000|1.000000] "" Vector__XXX
 SG_ KST_Unterdr_Zuendungsmeldung  : 21|1@1+ (1.000000,0.000000) [0.000000|1.000000] "" Vector__XXX
 SG_ KST_aut_Abschaltung_Zuendung  : 22|1@1+ (1.000000,0.000000) [0.000000|1.000000] "" Vector__XXX
 SG_ KST_Anf_Klemmenfreigabe_WFS  : 23|1@1+ (1.000000,0.000000) [0.000000|1.000000] "" Vector__XXX
 SG_ KST_Anf_ZV_Verriegelung  : 24|1@1+ (1.000000,0.000000) [0.000000|1.000000] "" Vector__XXX
 SG_ Relais_VoKo_angesteuert  : 25|1@1+ (1.000000,0.000000) [0.000000|1.000000] "" Vector__XXX
 SG_ RSt_Anforderung_HMS  : 26|3@1+ (1.000000,0.000000) [0.000000|7.000000] "" Vector__XXX
 SG_ KST_Zuendungswarnung  : 29|2@1+ (1.000000,0.000000) [0.000000|3.000000] "" Vector__XXX
 SG_ KST_Fahrer_Info_Text  : 31|3@1+ (1.000000,0.000000) [0.000000|7.000000] "" Vector__XXX

BO_ 949 Klima_11: 8 ICAS1_Gateway
 SG_ KL_Drehz_Anh  : 0|1@1+ (1.000000,0.000000) [0.000000|1.000000] "" Vector__XXX
 SG_ KL_Vorwarn_Komp_ein  : 1|1@1+ (1.000000,0.000000) [0.000000|1.000000] "" Vector__XXX
 SG_ KL_AC_Schalter  : 2|1@1+ (1.000000,0.000000) [0.000000|1.000000] "" Vector__XXX
 SG_ KL_Komp_Moment_alt  : 3|1@1+ (1.000000,0.000000) [0.000000|1.000000] "" Vector__XXX
 SG_ KL_Vorwarn_Zuheizer_ein  : 6|1@1+ (1.000000,0.000000) [0.000000|1.000000] "" Vector__XXX
 SG_ KL_Zustand  : 7|1@1+ (1.000000,0.000000) [0.000000|1.000000] "" Vector__XXX
 SG_ KL_Kompressorkupplung_linear  : 8|8@1+ (20.000000,0.000000) [0.000000|4000.000000] "Unit_MilliAmper" Vector__XXX
 SG_ KL_Charisma_FahrPr  : 16|4@1+ (1.000000,0.000000) [0.000000|15.000000] "" Vector__XXX
 SG_ KL_Charisma_Status  : 20|2@1+ (1.000000,0.000000) [0.000000|3.000000] "" Vector__XXX
 SG_ KL_nachtr_Stopp_Anf  : 22|1@1+ (1.000000,0.000000) [0.000000|1.000000] "" Vector__XXX
 SG_ KL_T_Charge  : 23|1@1+ (1.000000,0.000000) [0.000000|1.000000] "" Vector__XXX
 SG_ KL_Last_Kompr  : 24|8@1+ (0.250000,0.000000) [0.000000|63.500000] "Unit_NewtoMeter" Vector__XXX
 SG_ KL_Spannungs_Anf  : 32|2@1+ (1.000000,0.000000) [0.000000|3.000000] "" Vector__XXX
 SG_ KL_Thermomanagement  : 34|2@1+ (1.000000,0.000000) [0.000000|3.000000] "" Motor_BEV
 SG_ KL_StartStopp_Info  : 36|2@1+ (1.000000,0.000000) [0.000000|3.000000] "" Vector__XXX
 SG_ KL_Freilauf_Info  : 38|2@1+ (1.000000,0.000000) [0.000000|3.000000] "" Vector__XXX
 SG_ KL_Anf_KL  : 40|8@1+ (0.400000,0.000000) [0.000000|101.600000] "Unit_PerCent" Motor_BEV
 SG_ KL_el_Zuheizer_Stufe  : 48|3@1+ (1.000000,0.000000) [0.000000|7.000000] "" Vector__XXX
 SG_ KL_Ausstattung_Klima  : 51|3@1+ (1.000000,0.000000) [0.000000|7.000000] "" Vector__XXX
 SG_ KL_Variante_Standheizung  : 54|2@1+ (1.000000,0.000000) [0.000000|3.000000] "" Vector__XXX
 SG_ KL_Anf_KV  : 57|7@1+ (1.000000,0.000000) [0.000000|100.000000] "Unit_PerCent" Motor_BEV

BO_ 1511 Klima_EV_03: 8 ICAS1_Gateway
 SG_ KL_HV_Heizer_Strom  : 0|8@1+ (0.250000,0.000000) [0.000000|63.500000] "Unit_Amper" Motor_BEV
 SG_ KL_EKK_Strom  : 8|8@1+ (0.250000,0.000000) [0.000000|63.500000] "Unit_Amper" Motor_BEV
 SG_ KL_Pumpe_02_Soll  : 16|7@1+ (1.000000,0.000000) [0.000000|100.000000] "Unit_PerCent" Motor_BEV
 SG_ KL_Ventil_03_Soll  : 23|1@1+ (1.000000,0.000000) [0.000000|1.000000] "" Vector__XXX
 SG_ KL_Ventil_10_Status  : 24|3@1+ (1.000000,0.000000) [0.000000|7.000000] "" Vector__XXX
 SG_ KL_Senderkennung  : 27|1@1+ (1.000000,0.000000) [0.000000|1.000000] "" Vector__XXX
 SG_ WP_KJ_Soll  : 28|2@1+ (1.000000,0.000000) [0.000000|3.000000] "" Vector__XXX
 SG_ KL_Fehler_HV_EKK  : 30|2@1+ (1.000000,0.000000) [0.000000|3.000000] "" Vector__XXX
 SG_ KL_Fehler_HV_Heizer  : 32|2@1+ (1.000000,0.000000) [0.000000|3.000000] "" Vector__XXX
 SG_ KL_BattKond_WaPu_DZMax  : 34|6@1+ (2.000000,0.000000) [0.000000|100.000000] "Unit_PerCent" Vector__XXX
 SG_ WP_Kuehlerluefter_Anf  : 40|8@1+ (0.400000,0.000000) [0.000000|101.600000] "Unit_PerCent" Vector__XXX
 SG_ KL_KM_ASV_01_Status  : 48|2@1+ (1.000000,0.000000) [0.000000|3.000000] "" Vector__XXX
 SG_ KL_KM_ASV_02_Status  : 50|2@1+ (1.000000,0.000000) [0.000000|3.000000] "" Vector__XXX
 SG_ KL_Vorwarn_HVHeizer_Leistung  : 52|4@1+ (1.000000,0.000000) [0.000000|15.000000] "" Vector__XXX
 SG_ KL_Status_EoHVL_EKK  : 56|2@1+ (1.000000,0.000000) [0.000000|3.000000] "" Motor_BEV
 SG_ KL_Status_EoHVL_Heizer  : 58|2@1+ (1.000000,0.000000) [0.000000|3.000000] "" Motor_BEV
